VERSION "0.0.1"

NS_ :

BS_:

BU_: TCU BRK ESP MCU RDD GP TMS GW KPD1 RDE FNR ECU KPD2 ATSGO ACU IMU1 IMU2 IMU3 IMU4 IMU5 AGW PMI HDOQS EGOQS OBC EEC CBSW EJRH EJLH EPDLT EPDL2 EPDLR EPDLA TRBDZ ECU1 CLST LC510 EGDL JS SMB KPAC ACCU Audio TGU RDRR RDLH RDRH AVM CHMSL CTC SMK MC3D EVC MCU2

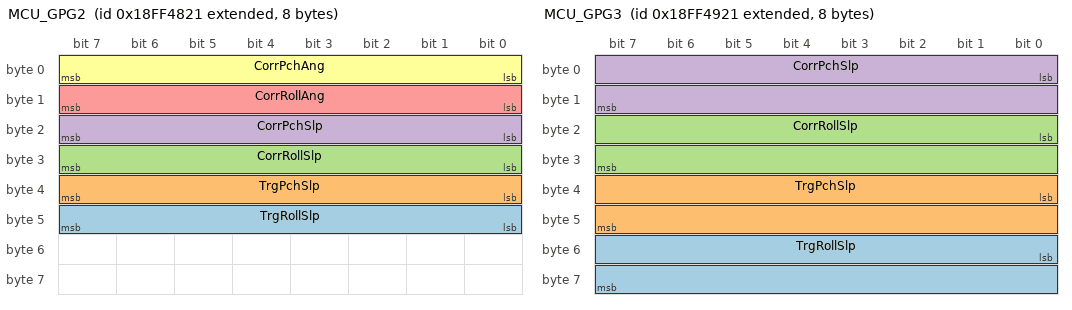
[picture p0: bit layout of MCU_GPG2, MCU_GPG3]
BO_ 2566866977 MCU_GPG2: 8 MCU
 SG_ TrgRollSlp : 40|8@1+ (1,-125) [-125|125] "%" Vector__XXX
 SG_ TrgPchSlp : 32|8@1+ (1,-125) [-125|125] "%" Vector__XXX
 SG_ CorrRollSlp : 24|8@1+ (1,-125) [-125|125] "%" Vector__XXX
 SG_ CorrPchSlp : 16|8@1+ (1,-125) [-125|125] "%" Vector__XXX
 SG_ CorrRollAng : 8|8@1+ (0.5,-65) [-65|60] "deg" Vector__XXX
 SG_ CorrPchAng : 0|8@1+ (0.5,-65) [-65|60] "deg" Vector__XXX

BO_ 2566867233 MCU_GPG3: 8 MCU
 SG_ TrgRollSlp : 48|16@1+ (0.01,-321.27) [-321.27|321.28] "%" Vector__XXX
 SG_ TrgPchSlp : 32|16@1+ (0.01,-321.27) [-321.27|321.28] "%" Vector__XXX
 SG_ CorrRollSlp : 16|16@1+ (0.01,-321.27) [-321.27|321.28] "%" Vector__XXX
 SG_ CorrPchSlp : 0|16@1+ (0.01,-321.27) [-321.27|321.28] "%" Vector__XXX

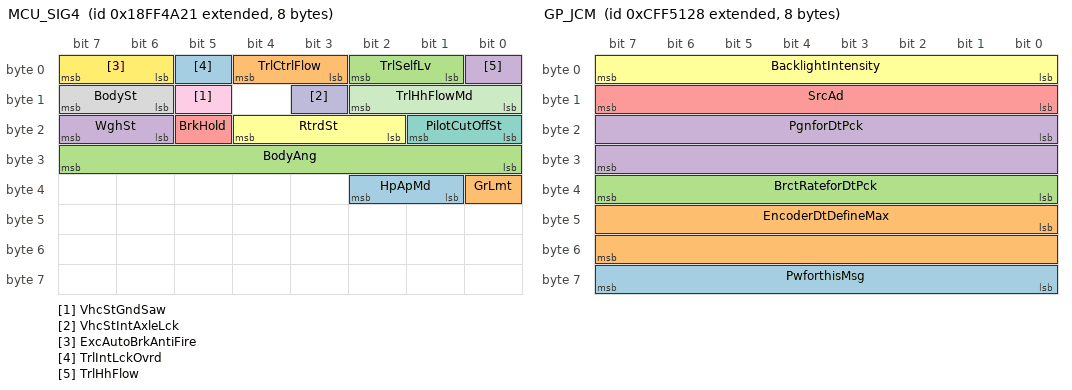
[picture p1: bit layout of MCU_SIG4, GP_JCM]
BO_ 2566867489 MCU_SIG4: 8 MCU
 SG_ HpApMd : 33|2@1+ (1,0) [0|3] "" Vector__XXX
 SG_ GrLmt : 32|1@1+ (1,0) [0|1] "" Vector__XXX
 SG_ BodyAng : 24|8@1+ (1,-125) [-125|125] "deg" Vector__XXX
 SG_ WghSt : 22|2@1+ (1,0) [0|3] "" Vector__XXX
 SG_ BrkHold : 21|1@1+ (1,0) [0|1] "" Vector__XXX
 SG_ RtrdSt : 18|3@1+ (1,0) [0|7] "" Vector__XXX
 SG_ PilotCutOffSt : 16|2@1+ (1,0) [0|3] "" Vector__XXX
 SG_ BodySt : 14|2@1+ (1,0) [0|3] "" Vector__XXX
 SG_ VhcStGndSaw : 13|1@1+ (1,0) [0|1] "" Vector__XXX
 SG_ VhcStIntAxleLck : 11|1@1+ (1,0) [0|1] "" Vector__XXX
 SG_ TrlHhFlowMd : 8|3@1+ (1,0) [0|7] "" Vector__XXX
 SG_ ExcAutoBrkAntiFire : 6|2@1+ (1,0) [0|3] "" Vector__XXX
 SG_ TrlIntLckOvrd : 5|1@1+ (1,0) [0|1] "" Vector__XXX
 SG_ TrlCtrlFlow : 3|2@1+ (1,0) [0|3] "" Vector__XXX
 SG_ TrlSelfLv : 1|2@1+ (1,0) [0|3] "" Vector__XXX
 SG_ TrlHhFlow : 0|1@1+ (1,0) [0|1] "" Vector__XXX

BO_ 2566867745 MCU_GPG4: 8 MCU
 SG_ EcoGgSt : 8|3@1+ (1,0) [0|7] "" Vector__XXX
 SG_ EcoGgLv : 0|8@1+ (1,0) [0|250] "%" Vector__XXX

BO_ 2566868257 MCU_METPSC: 250 MCU
 SG_ MaximumEgSpd : 40|16@1+ (0.125,0) [0|8031.875] "Rpm" Vector__XXX
 SG_ AutoCalbMd : 35|1@1+ (1,0) [0|1] "" Vector__XXX
 SG_ CalbReq : 34|1@1+ (1,0) [0|1] "" Vector__XXX
 SG_ VhcStTpsCalb : 32|2@1+ (1,0) [0|3] "" Vector__XXX
 SG_ MinimumEgSpd : 8|16@1+ (0.125,0) [0|8031.875] "rpm" Vector__XXX
 SG_ VhcStSsNrm : 3|1@1+ (1,0) [0|1] "" Vector__XXX
 SG_ VhcStEgIgn : 2|1@1+ (1,0) [0|1] "" Vector__XXX
 SG_ VhcStPilotCutOff : 1|1@1+ (1,0) [0|1] "" Vector__XXX
 SG_ VhcStEgCtrlDialMax : 0|1@1+ (1,0) [0|1] "" Vector__XXX

BO_ 2566868921 EGDL_EDO: 8 EGDL

BO_ 2566869025 MCU_JSO: 8 MCU

BO_ 2566869158 JS_JSO: 8 JS

BO_ 2365542696 GP_JCM: 8 GP
 SG_ PwforthisMsg : 56|8@1+ (1,0) [0|254] "" Vector__XXX
 SG_ EncoderDtDefineMax : 40|16@1+ (1,0) [0|65534] "" Vector__XXX
 SG_ BrctRateforDtPck : 32|8@1+ (1,0) [0|254] "" Vector__XXX
 SG_ PgnforDtPck : 16|16@1+ (1,0) [0|65534] "" Vector__XXX
 SG_ SrcAd : 8|8@1+ (1,0) [0|254] "" Vector__XXX
 SG_ BacklightIntensity : 0|8@1+ (1,0) [0|254] "" Vector__XXX

BO_ 2365542917 FNR_ZFTC1: 8 FNR

BO_ 2365543201 MCU_KEYPADBI: 8 MCU

BO_ 2365543504 KPD1_KEYPADS: 8 KPD1

BO_ 2365543713 MCU_KEYPADI1: 8 MCU

BO_ 2365543969 MCU_KEYPADMI1: 8 MCU

BO_ 2365544225 MCU_KEYPADMI2: 8 MCU

BO_ 2365544481 MCU_KEYPADI2: 8 MCU

BO_ 2365544737 MCU_KEYPADI3: 8 MCU

BO_ 2566871629 CBSW_HCMD: 8 CBSW

BO_ 2566872001 IMU1_ASI: 8 IMU1

BO_ 2566872002 IMU2_ASI: 8 IMU2

BO_ 2566872003 IMU3_ASI: 8 IMU3

BO_ 2566872004 IMU4_ASI: 8 IMU4

BO_ 2566872005 IMU5_ASI: 8 IMU5

BO_ 2365545552 KPD1_KEYPADS2: 8 KPD1

BO_ 2365545761 MCU_KEYPADI4: 8 MCU

BO_ 2566873377 MCU_ACUCTR: 8 MCU
 SG_ LowOutReq8 : 46|2@1+ (1,0) [0|3] "" Vector__XXX
 SG_ LowOutReq7 : 44|2@1+ (1,0) [0|3] "" Vector__XXX
 SG_ LowOutReq6 : 42|2@1+ (1,0) [0|3] "" Vector__XXX
 SG_ LowOutReq5 : 40|2@1+ (1,0) [0|3] "" Vector__XXX
 SG_ LowOutReq4 : 38|2@1+ (1,0) [0|3] "" Vector__XXX
 SG_ LowOutReq3 : 36|2@1+ (1,0) [0|3] "" Vector__XXX
 SG_ LowOutReq2 : 34|2@1+ (1,0) [0|3] "" Vector__XXX
 SG_ LowOutReq1 : 32|2@1+ (1,0) [0|3] "" Vector__XXX
 SG_ OutReq15 : 28|2@1+ (1,0) [0|3] "" Vector__XXX
 SG_ OutReq14 : 26|2@1+ (1,0) [0|3] "" Vector__XXX
 SG_ OutReq13 : 24|2@1+ (1,0) [0|3] "" Vector__XXX
 SG_ OutReq12 : 22|2@1+ (1,0) [0|3] "" Vector__XXX
 SG_ OutReq11 : 20|2@1+ (1,0) [0|3] "" Vector__XXX
 SG_ OutReq10 : 18|2@1+ (1,0) [0|3] "" Vector__XXX
 SG_ OutReq9 : 16|2@1+ (1,0) [0|3] "" Vector__XXX
 SG_ OutReq8 : 14|2@1+ (1,0) [0|3] "" Vector__XXX
 SG_ OutReq7 : 12|2@1+ (1,0) [0|3] "" Vector__XXX
 SG_ OutReq6 : 10|2@1+ (1,0) [0|3] "" Vector__XXX
 SG_ OutReq5 : 8|2@1+ (1,0) [0|3] "" Vector__XXX
 SG_ OutReq4 : 6|2@1+ (1,0) [0|3] "" Vector__XXX
 SG_ OutReq3 : 4|2@1+ (1,0) [0|3] "" Vector__XXX
 SG_ OutReq2 : 2|2@1+ (1,0) [0|3] "" Vector__XXX
 SG_ OutReq1 : 0|2@1+ (1,0) [0|3] "" Vector__XXX

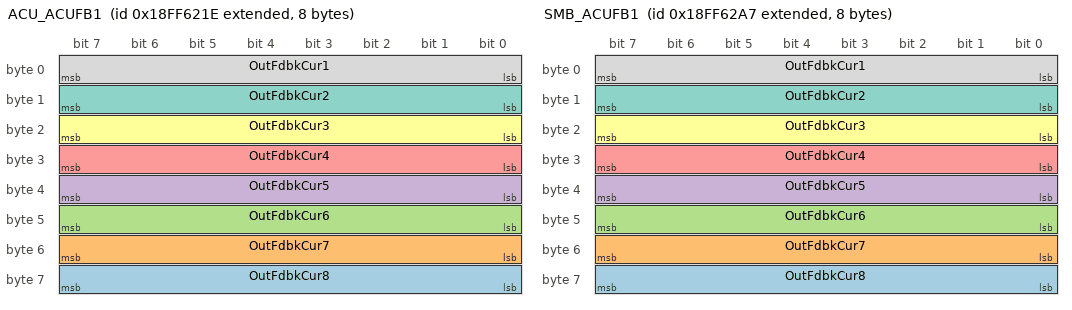
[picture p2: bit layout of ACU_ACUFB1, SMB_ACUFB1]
BO_ 2566873630 ACU_ACUFB1: 8 ACU
 SG_ OutFdbkCur8 : 56|8@1+ (1,0) [0|255] "" Vector__XXX
 SG_ OutFdbkCur7 : 48|8@1+ (1,0) [0|255] "" Vector__XXX
 SG_ OutFdbkCur6 : 40|8@1+ (1,0) [0|255] "" Vector__XXX
 SG_ OutFdbkCur5 : 32|8@1+ (1,0) [0|255] "" Vector__XXX
 SG_ OutFdbkCur4 : 24|8@1+ (1,0) [0|255] "" Vector__XXX
 SG_ OutFdbkCur3 : 16|8@1+ (1,0) [0|255] "" Vector__XXX
 SG_ OutFdbkCur2 : 8|8@1+ (1,0) [0|255] "" Vector__XXX
 SG_ OutFdbkCur1 : 0|8@1+ (0.05,0) [0|12.65] "A" Vector__XXX

BO_ 2566873767 SMB_ACUFB1: 8 SMB
 SG_ OutFdbkCur8 : 56|8@1+ (1,0) [0|255] "" Vector__XXX
 SG_ OutFdbkCur7 : 48|8@1+ (1,0) [0|255] "" Vector__XXX
 SG_ OutFdbkCur6 : 40|8@1+ (1,0) [0|255] "" Vector__XXX
 SG_ OutFdbkCur5 : 32|8@1+ (1,0) [0|255] "" Vector__XXX
 SG_ OutFdbkCur4 : 24|8@1+ (1,0) [0|255] "" Vector__XXX
 SG_ OutFdbkCur3 : 16|8@1+ (1,0) [0|255] "" Vector__XXX
 SG_ OutFdbkCur2 : 8|8@1+ (1,0) [0|255] "" Vector__XXX
 SG_ OutFdbkCur1 : 0|8@1+ (0.05,0) [0|12.65] "A" Vector__XXX

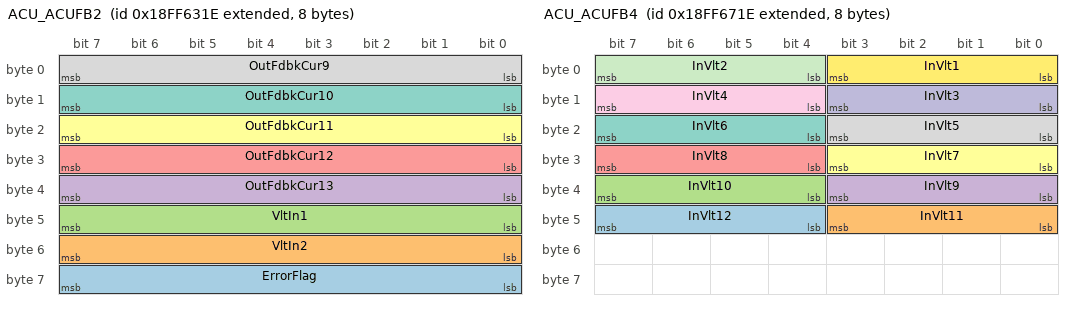
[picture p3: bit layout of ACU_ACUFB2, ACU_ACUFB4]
BO_ 2566873886 ACU_ACUFB2: 8 ACU
 SG_ ErrorFlag : 56|8@1+ (1,0) [0|255] "" Vector__XXX
 SG_ VltIn2 : 48|8@1+ (1,0) [0|255] "" Vector__XXX
 SG_ VltIn1 : 40|8@1+ (0.125,0) [0|31.625] "V" Vector__XXX
 SG_ OutFdbkCur13 : 32|8@1+ (1,0) [0|255] "" Vector__XXX
 SG_ OutFdbkCur12 : 24|8@1+ (1,0) [0|255] "" Vector__XXX
 SG_ OutFdbkCur11 : 16|8@1+ (1,0) [0|255] "" Vector__XXX
 SG_ OutFdbkCur10 : 8|8@1+ (1,0) [0|255] "" Vector__XXX
 SG_ OutFdbkCur9 : 0|8@1+ (0.05,0) [0|12.65] "A" Vector__XXX

BO_ 2566874654 ACU_ACUFB3: 8 ACU
 SG_ OutFdbkActvLowCur8 : 62|2@1+ (1,0) [0|3] "" Vector__XXX
 SG_ OutFdbkActvLowCur7 : 60|2@1+ (1,0) [0|3] "" Vector__XXX
 SG_ OutFdbkActvLowCur6 : 58|2@1+ (1,0) [0|3] "" Vector__XXX
 SG_ OutFdbkActvLowCur5 : 56|2@1+ (1,0) [0|3] "" Vector__XXX
 SG_ OutFdbkActvLowCur4 : 54|2@1+ (1,0) [0|3] "" Vector__XXX
 SG_ OutFdbkActvLowCur3 : 52|2@1+ (1,0) [0|3] "" Vector__XXX
 SG_ OutFdbkActvLowCur2 : 50|2@1+ (1,0) [0|3] "" Vector__XXX
 SG_ OutFdbkActvLowCur1 : 48|2@1+ (1,0) [0|3] "" Vector__XXX
 SG_ OutFdbkActvHighCur15 : 46|2@1+ (1,0) [0|3] "" Vector__XXX
 SG_ OutFdbkActvHighCur14 : 44|2@1+ (1,0) [0|3] "" Vector__XXX
 SG_ OutFdbkActvHighCur13 : 42|2@1+ (1,0) [0|3] "" Vector__XXX
 SG_ OutFdbkActvHighCur12 : 40|2@1+ (1,0) [0|3] "" Vector__XXX
 SG_ OutFdbkActvHighCur11 : 38|2@1+ (1,0) [0|3] "" Vector__XXX
 SG_ OutFdbkActvHighCur10 : 36|2@1+ (1,0) [0|3] "" Vector__XXX
 SG_ OutFdbkActvHighCur9 : 34|2@1+ (1,0) [0|3] "" Vector__XXX
 SG_ OutFdbkActvHighCur8 : 32|2@1+ (1,0) [0|3] "" Vector__XXX
 SG_ OutFdbkActvHighCur7 : 30|2@1+ (1,0) [0|3] "" Vector__XXX
 SG_ OutFdbkActvHighCur6 : 28|2@1+ (1,0) [0|3] "" Vector__XXX
 SG_ OutFdbkActvHighCur5 : 26|2@1+ (1,0) [0|3] "" Vector__XXX
 SG_ OutFdbkActvHighCur4 : 24|2@1+ (1,0) [0|3] "" Vector__XXX
 SG_ OutFdbkActvHighCur3 : 16|8@1+ (1,0) [0|255] "" Vector__XXX
 SG_ OutFdbkActvHighCur2 : 8|8@1+ (1,0) [0|255] "" Vector__XXX
 SG_ OutFdbkActvHighCur1 : 0|8@1+ (0.1,0) [0|25.3] "A" Vector__XXX

BO_ 2566874910 ACU_ACUFB4: 8 ACU
 SG_ InVlt12 : 44|4@1+ (1,0) [0|15] "" Vector__XXX
 SG_ InVlt11 : 40|4@1+ (1,0) [0|15] "" Vector__XXX
 SG_ InVlt10 : 36|4@1+ (1,0) [0|15] "" Vector__XXX
 SG_ InVlt9 : 32|4@1+ (1,0) [0|15] "" Vector__XXX
 SG_ InVlt8 : 28|4@1+ (1,0) [0|15] "" Vector__XXX
 SG_ InVlt7 : 24|4@1+ (1,0) [0|15] "" Vector__XXX
 SG_ InVlt6 : 20|4@1+ (1,0) [0|15] "" Vector__XXX
 SG_ InVlt5 : 16|4@1+ (1,0) [0|15] "" Vector__XXX
 SG_ InVlt4 : 12|4@1+ (1,0) [0|15] "" Vector__XXX
 SG_ InVlt3 : 8|4@1+ (1,0) [0|15] "" Vector__XXX
 SG_ InVlt2 : 4|4@1+ (1,0) [0|15] "" Vector__XXX
 SG_ InVlt1 : 0|4@1+ (2,0) [0|30] "V" Vector__XXX

BO_ 2566875297 KPAC_ACCMD: 8 KPAC

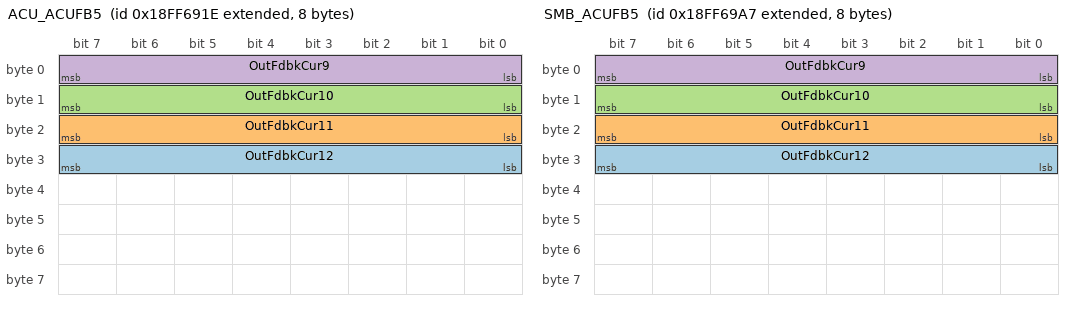
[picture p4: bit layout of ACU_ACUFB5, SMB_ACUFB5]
BO_ 2566875422 ACU_ACUFB5: 8 ACU
 SG_ OutFdbkCur12 : 24|8@1+ (1,0) [0|255] "" Vector__XXX
 SG_ OutFdbkCur11 : 16|8@1+ (1,0) [0|255] "" Vector__XXX
 SG_ OutFdbkCur10 : 8|8@1+ (1,0) [0|255] "" Vector__XXX
 SG_ OutFdbkCur9 : 0|8@1+ (0.1,0) [0|25.3] "A" Vector__XXX

BO_ 2566875559 SMB_ACUFB5: 8 SMB
 SG_ OutFdbkCur12 : 24|8@1+ (1,0) [0|255] "" Vector__XXX
 SG_ OutFdbkCur11 : 16|8@1+ (1,0) [0|255] "" Vector__XXX
 SG_ OutFdbkCur10 : 8|8@1+ (1,0) [0|255] "" Vector__XXX
 SG_ OutFdbkCur9 : 0|8@1+ (0.1,0) [0|25.3] "A" Vector__XXX

BO_ 2566875678 ACU_ACUFB6: 28 ACU
 SG_ MiniRly30AFuse2St : 221|1@1+ (1,0) [0|1] "" Vector__XXX
 SG_ MiniRly30AFuse1St : 220|1@1+ (1,0) [0|1] "" Vector__XXX
 SG_ MicroRly20AFuse5St : 219|1@1+ (1,0) [0|1] "" Vector__XXX
 SG_ MicroRly20AFuse4St : 218|1@1+ (1,0) [0|1] "" Vector__XXX
 SG_ MicroRly20AFuse3St : 217|1@1+ (1,0) [0|1] "" Vector__XXX
 SG_ MicroRly20AFuse2St : 216|1@1+ (1,0) [0|1] "" Vector__XXX
 SG_ MicroRly20AFuse1St : 215|1@1+ (1,0) [0|1] "" Vector__XXX
 SG_ KeyOn30AFuse5St : 214|1@1+ (1,0) [0|1] "" Vector__XXX
 SG_ KeyOn30AFuse4St : 213|1@1+ (1,0) [0|1] "" Vector__XXX
 SG_ KeyOn30AFuse3St : 212|1@1+ (1,0) [0|1] "" Vector__XXX
 SG_ KeyOn30AFuse2St : 211|1@1+ (1,0) [0|1] "" Vector__XXX
 SG_ KeyOn30AFuse1St : 210|1@1+ (1,0) [0|1] "" Vector__XXX
 SG_ KeyOn20AFuse10St : 209|1@1+ (1,0) [0|1] "" Vector__XXX
 SG_ KeyOn20AFuse9St : 208|1@1+ (1,0) [0|1] "" Vector__XXX
 SG_ KeyOn20AFuse8St : 207|1@1+ (1,0) [0|1] "" Vector__XXX
 SG_ KeyOn20AFuse7St : 206|1@1+ (1,0) [0|1] "" Vector__XXX
 SG_ KeyOn20AFuse6St : 205|1@1+ (1,0) [0|1] "" Vector__XXX
 SG_ KeyOn20AFuse5St : 204|1@1+ (1,0) [0|1] "" Vector__XXX
 SG_ KeyOn20AFuse4St : 203|1@1+ (1,0) [0|1] "" Vector__XXX
 SG_ KeyOn20AFuse3St : 202|1@1+ (1,0) [0|1] "" Vector__XXX
 SG_ KeyOn20AFuse2St : 201|1@1+ (1,0) [0|1] "" Vector__XXX
 SG_ KeyOn20AFuse1St : 200|1@1+ (1,0) [0|1] "" Vector__XXX
 SG_ KeyOn10AFuse5St : 199|1@1+ (1,0) [0|1] "" Vector__XXX
 SG_ KeyOn10AFuse4St : 198|1@1+ (1,0) [0|1] "" Vector__XXX
 SG_ KeyOn10AFuse3St : 197|1@1+ (1,0) [0|1] "" Vector__XXX
 SG_ KeyOn10AFuse2St : 196|1@1+ (1,0) [0|1] "" Vector__XXX
 SG_ KeyOn10AFuse1St : 195|1@1+ (1,0) [0|1] "" Vector__XXX
 SG_ KeyOn5AFuse15St : 194|1@1+ (1,0) [0|1] "" Vector__XXX
 SG_ KeyOn5AFuse14St : 193|1@1+ (1,0) [0|1] "" Vector__XXX
 SG_ KeyOn5AFuse13St : 192|1@1+ (1,0) [0|1] "" Vector__XXX
 SG_ KeyOn5AFuse12St : 191|1@1+ (1,0) [0|1] "" Vector__XXX
 SG_ KeyOn5AFuse11St : 190|1@1+ (1,0) [0|1] "" Vector__XXX
 SG_ KeyOn5AFuse10St : 189|1@1+ (1,0) [0|1] "" Vector__XXX
 SG_ KeyOn5AFuse9St : 188|1@1+ (1,0) [0|1] "" Vector__XXX
 SG_ KeyOn5AFuse8St : 187|1@1+ (1,0) [0|1] "" Vector__XXX
 SG_ KeyOn5AFuse7St : 186|1@1+ (1,0) [0|1] "" Vector__XXX
 SG_ KeyOn5AFuse6St : 185|1@1+ (1,0) [0|1] "" Vector__XXX
 SG_ KeyOn5AFuse5St : 184|1@1+ (1,0) [0|1] "" Vector__XXX
 SG_ KeyOn5AFuse4St : 183|1@1+ (1,0) [0|1] "" Vector__XXX
 SG_ KeyOn5AFuse3St : 182|1@1+ (1,0) [0|1] "" Vector__XXX
 SG_ KeyOn5AFuse2St : 181|1@1+ (1,0) [0|1] "" Vector__XXX
 SG_ KeyOn5AFuse1St : 180|1@1+ (1,0) [0|1] "" Vector__XXX
 SG_ BPlus30AFuse5St : 179|1@1+ (1,0) [0|1] "" Vector__XXX
 SG_ BPlus30AFuse4St : 178|1@1+ (1,0) [0|1] "" Vector__XXX
 SG_ BPlus30AFuse3St : 177|1@1+ (1,0) [0|1] "" Vector__XXX
 SG_ BPlus30AFuse2St : 176|1@1+ (1,0) [0|1] "" Vector__XXX
 SG_ BPlus30AFuse1St : 175|1@1+ (1,0) [0|1] "" Vector__XXX
 SG_ BPlus20AFuse5St : 174|1@1+ (1,0) [0|1] "" Vector__XXX
 SG_ BPlus20AFuse4St : 173|1@1+ (1,0) [0|1] "" Vector__XXX
 SG_ BPlus20AFuse3St : 172|1@1+ (1,0) [0|1] "" Vector__XXX
 SG_ BPlus20AFuse2St : 171|1@1+ (1,0) [0|1] "" Vector__XXX
 SG_ BPlus20AFuse1St : 170|1@1+ (1,0) [0|1] "" Vector__XXX
 SG_ BPlus5AFuse10St : 169|1@1+ (1,0) [0|1] "" Vector__XXX
 SG_ BPlus5AFuse9St : 168|1@1+ (1,0) [0|1] "" Vector__XXX
 SG_ BPlus5AFuse8St : 167|1@1+ (1,0) [0|1] "" Vector__XXX
 SG_ BPlus5AFuse7St : 166|1@1+ (1,0) [0|1] "" Vector__XXX
 SG_ BPlus5AFuse6St : 165|1@1+ (1,0) [0|1] "" Vector__XXX
 SG_ BPlus5AFuse5St : 164|1@1+ (1,0) [0|1] "" Vector__XXX
 SG_ BPlus5AFuse4St : 163|1@1+ (1,0) [0|1] "" Vector__XXX
 SG_ BPlus5AFuse3St : 162|1@1+ (1,0) [0|1] "" Vector__XXX
 SG_ BPlus5AFuse2St : 161|1@1+ (1,0) [0|1] "" Vector__XXX
 SG_ BPlus5AFuse1St : 160|1@1+ (1,0) [0|1] "" Vector__XXX
 SG_ IPSTotalCur : 144|16@1+ (0.1,0) [0|102] "%" Vector__XXX
 SG_ MINIFuse2Cur : 128|16@1+ (0.05,0) [0|3212.75] "A" Vector__XXX
 SG_ MINIFuse1Cur : 112|16@1+ (0.05,0) [0|3212.75] "A" Vector__XXX
 SG_ MicroFuse5Cur : 96|16@1+ (0.05,0) [0|3212.75] "A" Vector__XXX
 SG_ MicroFuse4Cur : 80|16@1+ (0.05,0) [0|3212.75] "A" Vector__XXX
 SG_ MicroFuse3Cur : 64|16@1+ (0.05,0) [0|3212.75] "A" Vector__XXX
 SG_ MicroFuse2Cur : 48|16@1+ (0.05,0) [0|3212.75] "A" Vector__XXX
 SG_ MicroFuse1Cur : 32|16@1+ (0.05,0) [0|3212.75] "A" Vector__XXX
 SG_ KeyOnPwrCur : 16|16@1+ (0.05,0) [0|3212.75] "A" Vector__XXX
 SG_ BPlusPwrCur : 0|16@1+ (0.05,0) [0|3212.75] "A" Vector__XXX

BO_ 2566875815 SMB_ACUFB6: 28 SMB
 SG_ MiniRly30AFuse2St : 221|1@1+ (1,0) [0|1] "" Vector__XXX
 SG_ MiniRly30AFuse1St : 220|1@1+ (1,0) [0|1] "" Vector__XXX
 SG_ MicroRly20AFuse5St : 219|1@1+ (1,0) [0|1] "" Vector__XXX
 SG_ MicroRly20AFuse4St : 218|1@1+ (1,0) [0|1] "" Vector__XXX
 SG_ MicroRly20AFuse3St : 217|1@1+ (1,0) [0|1] "" Vector__XXX
 SG_ MicroRly20AFuse2St : 216|1@1+ (1,0) [0|1] "" Vector__XXX
 SG_ MicroRly20AFuse1St : 215|1@1+ (1,0) [0|1] "" Vector__XXX
 SG_ KeyOn30AFuse5St : 214|1@1+ (1,0) [0|1] "" Vector__XXX
 SG_ KeyOn30AFuse4St : 213|1@1+ (1,0) [0|1] "" Vector__XXX
 SG_ KeyOn30AFuse3St : 212|1@1+ (1,0) [0|1] "" Vector__XXX
 SG_ KeyOn30AFuse2St : 211|1@1+ (1,0) [0|1] "" Vector__XXX
 SG_ KeyOn30AFuse1St : 210|1@1+ (1,0) [0|1] "" Vector__XXX
 SG_ KeyOn20AFuse10St : 209|1@1+ (1,0) [0|1] "" Vector__XXX
 SG_ KeyOn20AFuse9St : 208|1@1+ (1,0) [0|1] "" Vector__XXX
 SG_ KeyOn20AFuse8St : 207|1@1+ (1,0) [0|1] "" Vector__XXX
 SG_ KeyOn20AFuse7St : 206|1@1+ (1,0) [0|1] "" Vector__XXX
 SG_ KeyOn20AFuse6St : 205|1@1+ (1,0) [0|1] "" Vector__XXX
 SG_ KeyOn20AFuse5St : 204|1@1+ (1,0) [0|1] "" Vector__XXX
 SG_ KeyOn20AFuse4St : 203|1@1+ (1,0) [0|1] "" Vector__XXX
 SG_ KeyOn20AFuse3St : 202|1@1+ (1,0) [0|1] "" Vector__XXX
 SG_ KeyOn20AFuse2St : 201|1@1+ (1,0) [0|1] "" Vector__XXX
 SG_ KeyOn20AFuse1St : 200|1@1+ (1,0) [0|1] "" Vector__XXX
 SG_ KeyOn10AFuse5St : 199|1@1+ (1,0) [0|1] "" Vector__XXX
 SG_ KeyOn10AFuse4St : 198|1@1+ (1,0) [0|1] "" Vector__XXX
 SG_ KeyOn10AFuse3St : 197|1@1+ (1,0) [0|1] "" Vector__XXX
 SG_ KeyOn10AFuse2St : 196|1@1+ (1,0) [0|1] "" Vector__XXX
 SG_ KeyOn10AFuse1St : 195|1@1+ (1,0) [0|1] "" Vector__XXX
 SG_ KeyOn5AFuse15St : 194|1@1+ (1,0) [0|1] "" Vector__XXX
 SG_ KeyOn5AFuse14St : 193|1@1+ (1,0) [0|1] "" Vector__XXX
 SG_ KeyOn5AFuse13St : 192|1@1+ (1,0) [0|1] "" Vector__XXX
 SG_ KeyOn5AFuse12St : 191|1@1+ (1,0) [0|1] "" Vector__XXX
 SG_ KeyOn5AFuse11St : 190|1@1+ (1,0) [0|1] "" Vector__XXX
 SG_ KeyOn5AFuse10St : 189|1@1+ (1,0) [0|1] "" Vector__XXX
 SG_ KeyOn5AFuse9St : 188|1@1+ (1,0) [0|1] "" Vector__XXX
 SG_ KeyOn5AFuse8St : 187|1@1+ (1,0) [0|1] "" Vector__XXX
 SG_ KeyOn5AFuse7St : 186|1@1+ (1,0) [0|1] "" Vector__XXX
 SG_ KeyOn5AFuse6St : 185|1@1+ (1,0) [0|1] "" Vector__XXX
 SG_ KeyOn5AFuse5St : 184|1@1+ (1,0) [0|1] "" Vector__XXX
 SG_ KeyOn5AFuse4St : 183|1@1+ (1,0) [0|1] "" Vector__XXX
 SG_ KeyOn5AFuse3St : 182|1@1+ (1,0) [0|1] "" Vector__XXX
 SG_ KeyOn5AFuse2St : 181|1@1+ (1,0) [0|1] "" Vector__XXX
 SG_ KeyOn5AFuse1St : 180|1@1+ (1,0) [0|1] "" Vector__XXX
 SG_ BPlus30AFuse5St : 179|1@1+ (1,0) [0|1] "" Vector__XXX
 SG_ BPlus30AFuse4St : 178|1@1+ (1,0) [0|1] "" Vector__XXX
 SG_ BPlus30AFuse3St : 177|1@1+ (1,0) [0|1] "" Vector__XXX
 SG_ BPlus30AFuse2St : 176|1@1+ (1,0) [0|1] "" Vector__XXX
 SG_ BPlus30AFuse1St : 175|1@1+ (1,0) [0|1] "" Vector__XXX
 SG_ BPlus20AFuse5St : 174|1@1+ (1,0) [0|1] "" Vector__XXX
 SG_ BPlus20AFuse4St : 173|1@1+ (1,0) [0|1] "" Vector__XXX
 SG_ BPlus20AFuse3St : 172|1@1+ (1,0) [0|1] "" Vector__XXX
 SG_ BPlus20AFuse2St : 171|1@1+ (1,0) [0|1] "" Vector__XXX
 SG_ BPlus20AFuse1St : 170|1@1+ (1,0) [0|1] "" Vector__XXX
 SG_ BPlus5AFuse10St : 169|1@1+ (1,0) [0|1] "" Vector__XXX
 SG_ BPlus5AFuse9St : 168|1@1+ (1,0) [0|1] "" Vector__XXX
 SG_ BPlus5AFuse8St : 167|1@1+ (1,0) [0|1] "" Vector__XXX
 SG_ BPlus5AFuse7St : 166|1@1+ (1,0) [0|1] "" Vector__XXX
 SG_ BPlus5AFuse6St : 165|1@1+ (1,0) [0|1] "" Vector__XXX
 SG_ BPlus5AFuse5St : 164|1@1+ (1,0) [0|1] "" Vector__XXX
 SG_ BPlus5AFuse4St : 163|1@1+ (1,0) [0|1] "" Vector__XXX
 SG_ BPlus5AFuse3St : 162|1@1+ (1,0) [0|1] "" Vector__XXX
 SG_ BPlus5AFuse2St : 161|1@1+ (1,0) [0|1] "" Vector__XXX
 SG_ BPlus5AFuse1St : 160|1@1+ (1,0) [0|1] "" Vector__XXX
 SG_ IPSTotalCur : 144|16@1+ (0.1,0) [0|102] "%" Vector__XXX
 SG_ MINIFuse2Cur : 128|16@1+ (0.05,0) [0|3212.75] "A" Vector__XXX
 SG_ MINIFuse1Cur : 112|16@1+ (0.05,0) [0|3212.75] "A" Vector__XXX
 SG_ MicroFuse5Cur : 96|16@1+ (0.05,0) [0|3212.75] "A" Vector__XXX
 SG_ MicroFuse4Cur : 80|16@1+ (0.05,0) [0|3212.75] "A" Vector__XXX
 SG_ MicroFuse3Cur : 64|16@1+ (0.05,0) [0|3212.75] "A" Vector__XXX
 SG_ MicroFuse2Cur : 48|16@1+ (0.05,0) [0|3212.75] "A" Vector__XXX
 SG_ MicroFuse1Cur : 32|16@1+ (0.05,0) [0|3212.75] "A" Vector__XXX
 SG_ KeyOnPwrCur : 16|16@1+ (0.05,0) [0|3212.75] "A" Vector__XXX
 SG_ BPlusPwrCur : 0|16@1+ (0.05,0) [0|3212.75] "A" Vector__XXX

BO_ 2566875929 ACCU_ACRM: 8 ACCU
 SG_ AcpSsPrs : 56|8@1+ (16,0) [0|4000] "" Vector__XXX
 SG_ CurAmbTmpCelsRealTm : 48|8@1+ (0.5,-40) [-40|86] "Celsius" Vector__XXX
 SG_ TmpSt : 44|4@1+ (1,0) [1|15] "Step" Vector__XXX
 SG_ CurBlowerSpd : 40|4@1+ (1,0) [0|13] "" Vector__XXX
 SG_ CurAmbTmpCelsFilt : 32|8@1+ (0.5,-40) [-40|86] "Celsius" Vector__XXX
 SG_ VhcStSybACOffInd : 29|2@1+ (1,0) [0|3] "" Vector__XXX
 SG_ CurTmpSet : 24|5@1+ (0.5,17) [17|32] "Celsius" Vector__XXX
 SG_ CpsSt : 22|2@1+ (1,0) [0|3] "" Vector__XXX
 SG_ TmpSetValBelowSt : 20|2@1+ (1,0) [0|3] "" Vector__XXX
 SG_ TmpSetValOverSt : 18|2@1+ (1,0) [0|3] "" Vector__XXX
 SG_ HvacPwrSt : 16|2@1+ (1,0) [0|3] "" Vector__XXX
 SG_ WindDirDefIndSt : 14|2@1+ (1,0) [0|3] "" Vector__XXX
 SG_ WindDirFloorIndSt : 12|2@1+ (1,0) [0|3] "" Vector__XXX
 SG_ WindDirRrIndSt : 10|2@1+ (1,0) [0|3] "" Vector__XXX
 SG_ WindDirFrIndSt : 8|2@1+ (1,0) [0|3] "" Vector__XXX
 SG_ DefMdSt : 6|2@1+ (1,0) [0|3] "" Vector__XXX
 SG_ OutInMdSel : 4|2@1+ (1,0) [0|3] "" Vector__XXX
 SG_ AcMdSt : 2|2@1+ (1,0) [0|3] "" Vector__XXX
 SG_ MnAutoMdSt : 0|2@1+ (1,0) [0|3] "" Vector__XXX

BO_ 2566876320 Audio_DCAI: 8 Audio

BO_ 2566876576 Audio_AFRTGP: 250 Audio

BO_ 2566876832 Audio_APFGP: 250 Audio

BO_ 2566876961 MCU_ACUCTR2: 8 MCU
 SG_ LowOutReq8 : 46|2@1+ (1,0) [0|3] "" Vector__XXX
 SG_ LowOutReq7 : 44|2@1+ (1,0) [0|3] "" Vector__XXX
 SG_ LowOutReq6 : 42|2@1+ (1,0) [0|3] "" Vector__XXX
 SG_ LowOutReq5 : 40|2@1+ (1,0) [0|3] "" Vector__XXX
 SG_ LowOutReq4 : 38|2@1+ (1,0) [0|3] "" Vector__XXX
 SG_ LowOutReq3 : 36|2@1+ (1,0) [0|3] "" Vector__XXX
 SG_ LowOutReq2 : 34|2@1+ (1,0) [0|3] "" Vector__XXX
 SG_ LowOutReq1 : 32|2@1+ (1,0) [0|3] "" Vector__XXX
 SG_ OutReq15 : 28|2@1+ (1,0) [0|3] "" Vector__XXX
 SG_ OutReq14 : 26|2@1+ (1,0) [0|3] "" Vector__XXX
 SG_ OutReq13 : 24|2@1+ (1,0) [0|3] "" Vector__XXX
 SG_ OutReq12 : 22|2@1+ (1,0) [0|3] "" Vector__XXX
 SG_ OutReq11 : 20|2@1+ (1,0) [0|3] "" Vector__XXX
 SG_ OutReq10 : 18|2@1+ (1,0) [0|3] "" Vector__XXX
 SG_ OutReq9 : 16|2@1+ (1,0) [0|3] "" Vector__XXX
 SG_ OutReq8 : 14|2@1+ (1,0) [0|3] "" Vector__XXX
 SG_ OutReq7 : 12|2@1+ (1,0) [0|3] "" Vector__XXX
 SG_ OutReq6 : 10|2@1+ (1,0) [0|3] "" Vector__XXX
 SG_ OutReq5 : 8|2@1+ (1,0) [0|3] "" Vector__XXX
 SG_ OutReq4 : 6|2@1+ (1,0) [0|3] "" Vector__XXX
 SG_ OutReq3 : 4|2@1+ (1,0) [0|3] "" Vector__XXX
 SG_ OutReq2 : 2|2@1+ (1,0) [0|3] "" Vector__XXX
 SG_ OutReq1 : 0|2@1+ (1,0) [0|3] "" Vector__XXX

BO_ 2566877258 TMS_TMSVI: 250 TMS

BO_ 2566877514 TMS_TMSVTI: 250 TMS

BO_ 2566877770 TGU_TMSGPSI: 17 TGU
 SG_ Offset : 104|32@1+ (1,0) [-43200|43200] "S" Vector__XXX
 SG_ St : 96|8@1+ (1,0) [0|3] "" Vector__XXX
 SG_ GpsSatNo : 88|8@1+ (1,0) [0|255] "" Vector__XXX
 SG_ Spd : 80|8@1+ (1,0) [0|255] "km/h" Vector__XXX
 SG_ Z : 48|32@1+ (1,0) [-2147483648|2147483647] "m" Vector__XXX
 SG_ Y : 24|24@1+ (1,0) [-180|180] "Degree" Vector__XXX
 SG_ X : 0|24@1+ (1,0) [-90|90] "Degree" Vector__XXX

BO_ 2566878026 TGU_TMSNIC: 250 TGU

BO_ 2566878282 TMS_TMSNIS: 250 TMS

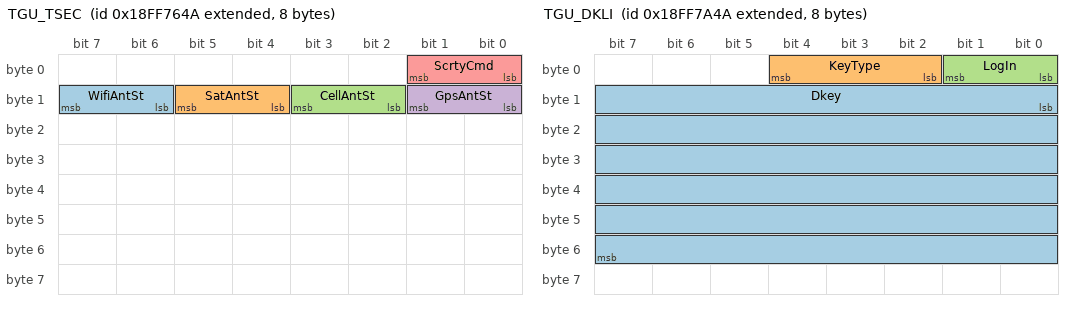
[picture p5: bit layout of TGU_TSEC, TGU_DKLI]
BO_ 2566878794 TGU_TSEC: 8 TGU
 SG_ WifiAntSt : 14|2@1+ (1,0) [0|3] "" Vector__XXX
 SG_ SatAntSt : 12|2@1+ (1,0) [0|3] "" Vector__XXX
 SG_ CellAntSt : 10|2@1+ (1,0) [0|3] "" Vector__XXX
 SG_ GpsAntSt : 8|2@1+ (1,0) [0|3] "" Vector__XXX
 SG_ ScrtyCmd : 0|2@1+ (1,0) [0|3] "" Vector__XXX

BO_ 2566879050 TMS_TMSGPSI2: 8 TMS

BO_ 2566879272 GP_TMSTP: 8 GP
 SG_ Sha1Hash : 0|32@1+ (1,0) [0|255] "" Vector__XXX

BO_ 2566879306 TGU_TMSTP: 8 TGU
 SG_ Sha1Hash : 0|32@1+ (1,0) [0|255] "" Vector__XXX

BO_ 2566879562 TGU_TMSLURT: 8 TGU
 SG_ Cd : 0|48@1+ (1,0) [0|255] "" Vector__XXX

BO_ 2566879818 TGU_DKLI: 8 TGU
 SG_ Dkey : 8|48@1+ (1,0) [0|281474976710655] "" Vector__XXX
 SG_ KeyType : 2|3@1+ (1,0) [0|7] "" Vector__XXX
 SG_ LogIn : 0|2@1+ (1,0) [0|3] "" Vector__XXX

BO_ 2566880074 TGU_DKLD: 9 TGU
 SG_ DkeyList : 8|64@1+ (1,0) [0|0] "" Vector__XXX
 SG_ Cnt : 0|8@1+ (1,0) [0|255] "" Vector__XXX

BO_ 2566880330 TGU_DKSEL: 8 TGU
 SG_ DigitalKey : 8|48@1+ (1,0) [0|281474976710655] "" Vector__XXX
 SG_ SelType : 0|3@1+ (1,0) [0|7] "" Vector__XXX

BO_ 2566880586 TMS_TMSACKNACK: 8 TMS

BO_ 2566880842 TGU_TMSPUC: 8 TGU
 SG_ TmsPmntUnlockCd : 0|32@1+ (1,0) [0|4294967295] "" Vector__XXX

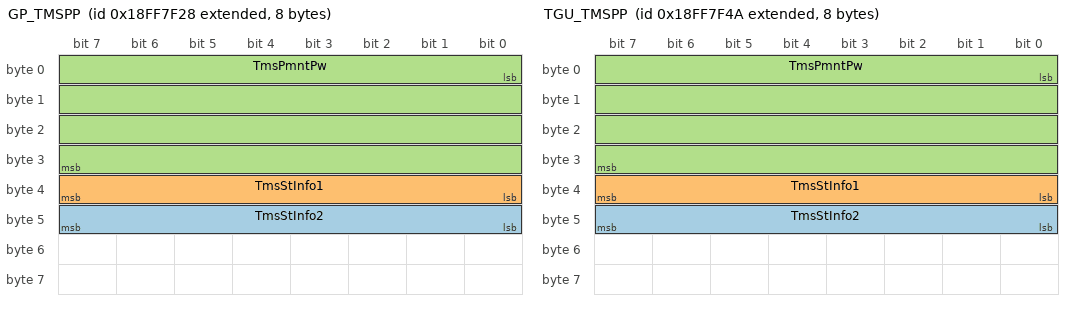
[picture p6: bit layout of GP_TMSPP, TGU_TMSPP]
BO_ 2566881064 GP_TMSPP: 8 GP
 SG_ TmsStInfo2 : 40|8@1+ (1,0) [0|255] "" Vector__XXX
 SG_ TmsStInfo1 : 32|8@1+ (1,0) [0|255] "" Vector__XXX
 SG_ TmsPmntPw : 0|32@1+ (1,0) [0|4294967295] "" Vector__XXX

BO_ 2566881098 TGU_TMSPP: 8 TGU
 SG_ TmsStInfo2 : 40|8@1+ (1,0) [0|255] "" Vector__XXX
 SG_ TmsStInfo1 : 32|8@1+ (1,0) [0|255] "" Vector__XXX
 SG_ TmsPmntPw : 0|32@1+ (1,0) [0|4294967295] "" Vector__XXX

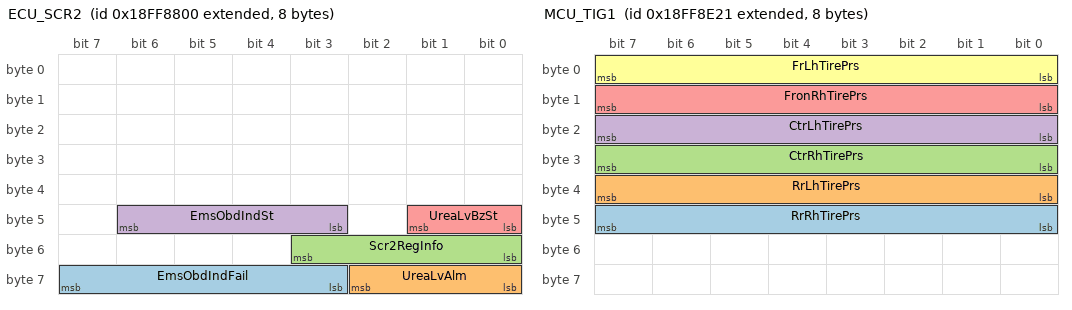
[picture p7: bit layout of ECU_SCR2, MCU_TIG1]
BO_ 2566883328 ECU_SCR2: 8 ECU
 SG_ EmsObdIndFail : 59|5@1+ (1,0) [0|31] "" Vector__XXX
 SG_ UreaLvAlm : 56|3@1+ (1,0) [0|7] "" Vector__XXX
 SG_ Scr2RegInfo : 48|4@1+ (1,0) [0|15] "" Vector__XXX
 SG_ EmsObdIndSt : 43|4@1+ (1,0) [0|15] "" Vector__XXX
 SG_ UreaLvBzSt : 40|2@1+ (1,0) [0|3] "" Vector__XXX

BO_ 2566883873 MCU_AASI: 62 MCU
 SG_ AltVlt : 480|16@1+ (0.001,0) [0|64.255] "V" Vector__XXX
 SG_ Rr2BrkSsPrs : 464|16@1+ (0.0625,0) [0|500] "bar" Vector__XXX
 SG_ BoomCylRodSsPrs : 448|16@1+ (0.0625,0) [0|500] "bar" Vector__XXX
 SG_ BoomCylHeadSsPrs : 432|16@1+ (0.0625,0) [0|500] "bar" Vector__XXX
 SG_ CtrPinAngSs1Vlt : 416|16@1+ (0.001,0) [0|64.255] "V" Vector__XXX
 SG_ AccPdlSs2Vlt : 400|16@1+ (0.001,0) [0|64.255] "V" Vector__XXX
 SG_ DumpBedAngSs2Vlt : 384|16@1+ (0.001,0) [0|64.255] "V" Vector__XXX
 SG_ DumpBedAngSs1Vlt : 368|16@1+ (0.001,0) [0|64.255] "V" Vector__XXX
 SG_ BrkInchPdlSs1Vlt : 352|16@1+ (0.001,0) [0|64.255] "V" Vector__XXX
 SG_ TipJoySs1Vlt : 336|16@1+ (0.001,0) [0|64.255] "V" Vector__XXX
 SG_ RhCylSsPrs : 320|16@1+ (0.0625,0) [0|500] "bar" Vector__XXX
 SG_ EmgStrSsPrs : 304|16@1+ (0.0625,0) [0|500] "bar" Vector__XXX
 SG_ AxleOilSsTmp : 288|16@1+ (1,-40) [-40|210] "�C" Vector__XXX
 SG_ FuelSsLv : 272|16@1+ (1,0) [0|250] "%" Vector__XXX
 SG_ Rr1BrkSsPrs : 256|16@1+ (0.0625,0) [0|500] "bar" Vector__XXX
 SG_ FrBrkSsPrs : 240|16@1+ (0.0625,0) [0|500] "bar" Vector__XXX
 SG_ AccPdlSs1Vlt : 224|16@1+ (0.001,0) [0|64.255] "V" Vector__XXX
 SG_ CtrPinAngSs2Vlt : 208|16@1+ (0.001,0) [0|64.255] "V" Vector__XXX
 SG_ TmsSecVlt : 192|16@1+ (0.001,0) [0|64.255] "V" Vector__XXX
 SG_ LhCylSsPrs : 176|16@1+ (0.0625,0) [0|500] "bar" Vector__XXX
 SG_ Acc3SsPrs : 160|16@1+ (0.0625,0) [0|500] "bar" Vector__XXX
 SG_ BrkInchPdlSs2Vlt : 144|16@1+ (0.001,0) [0|64.255] "V" Vector__XXX
 SG_ CacFanSsPrs : 128|16@1+ (0.0625,0) [0|500] "bar" Vector__XXX
 SG_ Acc2SsPrs : 112|16@1+ (0.0625,0) [0|500] "bar" Vector__XXX
 SG_ TipJoySs2Vlt : 96|16@1+ (0.001,0) [0|64.255] "V" Vector__XXX
 SG_ TocFanSsPrs : 80|16@1+ (0.0625,0) [0|500] "bar" Vector__XXX
 SG_ Acc1SsPrs : 64|16@1+ (0.0625,0) [0|500] "bar" Vector__XXX
 SG_ PrkBrkSsPrs : 48|16@1+ (0.0625,0) [0|500] "bar" Vector__XXX
 SG_ MainSsPrs : 32|16@1+ (0.0625,0) [0|500] "bar" Vector__XXX
 SG_ WifSsVlt : 16|16@1+ (0.001,0) [0|64.255] "V" Vector__XXX
 SG_ HydOilSsTmp : 0|16@1+ (1,-40) [-40|210] "�C" Vector__XXX

BO_ 2566884129 MCU_AAAI: 16 MCU
 SG_ FanDrvTocEvc : 112|16@1+ (1,0) [0|2000] "mA" Vector__XXX
 SG_ eFan2DutyRatio : 96|16@1+ (0.01,-321.27) [-321.27|321.28] "%" Vector__XXX
 SG_ eFan3DutyRatio : 80|16@1+ (0.01,-321.27) [-321.27|321.28] "%" Vector__XXX
 SG_ eBrkEvc : 64|16@1+ (1,0) [0|2000] "mA" Vector__XXX
 SG_ eFan1DutyRatio : 48|16@1+ (0.01,-321.27) [-321.27|321.28] "%" Vector__XXX
 SG_ FanDrvRadCacEvc : 32|16@1+ (1,0) [0|2000] "mA" Vector__XXX
 SG_ BodyDnEvc : 16|16@1+ (1,0) [0|2000] "mA" Vector__XXX
 SG_ BodyUpEvc : 0|16@1+ (1,0) [0|2000] "mA" Vector__XXX

BO_ 2566884385 MCU_ADSI: 250 MCU
 SG_ StartCrkSw : 38|2@1+ (1,0) [0|3] "" Vector__XXX
 SG_ GrSelSw : 36|2@1+ (1,0) [0|3] "" Vector__XXX
 SG_ GrSelNtrlSw : 34|2@1+ (1,0) [0|3] "" Vector__XXX
 SG_ PrkSw : 32|2@1+ (1,0) [0|3] "" Vector__XXX
 SG_ GrSelRvsSw : 30|2@1+ (1,0) [0|3] "" Vector__XXX
 SG_ GrSelShftDnSw : 28|2@1+ (1,0) [0|3] "" Vector__XXX
 SG_ GrSelShftUpSw : 26|2@1+ (1,0) [0|3] "" Vector__XXX
 SG_ GrSelFwdSw : 24|2@1+ (1,0) [0|3] "" Vector__XXX
 SG_ DustIndSw : 22|2@1+ (1,0) [0|3] "" Vector__XXX
 SG_ StartAccSw : 20|2@1+ (1,0) [0|3] "" Vector__XXX
 SG_ AtsForceRgnSw : 18|2@1+ (1,0) [0|3] "" Vector__XXX
 SG_ AtsRgnIhbsw : 16|2@1+ (1,0) [0|3] "" Vector__XXX
 SG_ eFan3ErrSt : 14|2@1+ (1,0) [0|3] "" Vector__XXX
 SG_ KeyBrSw : 12|2@1+ (1,0) [0|3] "" Vector__XXX
 SG_ TipJoySw : 10|2@1+ (1,0) [0|3] "" Vector__XXX
 SG_ AgsSw : 8|2@1+ (1,0) [0|3] "" Vector__XXX
 SG_ eFan2ErrSt : 6|2@1+ (1,0) [0|3] "" Vector__XXX
 SG_ eFan1ErrSt : 4|2@1+ (1,0) [0|3] "" Vector__XXX
 SG_ SeatBeltSt : 2|2@1+ (1,0) [0|3] "" Vector__XXX
 SG_ FrWiperStpSw : 0|2@1+ (1,0) [0|3] "" Vector__XXX

BO_ 2566884641 MCU_ADAI: 250 MCU
 SG_ SusRhDn : 40|2@1+ (1,0) [0|3] "" Vector__XXX
 SG_ TocRvs : 38|2@1+ (1,0) [0|3] "" Vector__XXX
 SG_ TurnSigRhRly : 36|2@1+ (1,0) [0|3] "" Vector__XXX
 SG_ TurnSigLhRly : 34|2@1+ (1,0) [0|3] "" Vector__XXX
 SG_ SusRhUp : 32|2@1+ (1,0) [0|3] "" Vector__XXX
 SG_ EgRunOutSig : 30|2@1+ (1,0) [0|3] "" Vector__XXX
 SG_ SusLhDn : 28|2@1+ (1,0) [0|3] "" Vector__XXX
 SG_ UreaSuperChgWrnSig : 26|2@1+ (1,0) [0|3] "" Vector__XXX
 SG_ FanStpSv : 24|2@1+ (1,0) [0|3] "" Vector__XXX
 SG_ Dhl3Sig : 22|2@1+ (1,0) [0|3] "" Vector__XXX
 SG_ Dhl2Sig : 20|2@1+ (1,0) [0|3] "" Vector__XXX
 SG_ SusLhUp : 18|2@1+ (1,0) [0|3] "" Vector__XXX
 SG_ PrkBrkRlsSv : 16|2@1+ (1,0) [0|3] "" Vector__XXX
 SG_ AxleOilCoolSv : 14|2@1+ (1,0) [0|3] "" Vector__XXX
 SG_ TocUnloading : 12|2@1+ (1,0) [0|3] "" Vector__XXX
 SG_ AccRly : 10|2@1+ (1,0) [0|3] "" Vector__XXX
 SG_ RrWinHtRly : 8|2@1+ (1,0) [0|3] "" Vector__XXX
 SG_ LiftArmFlt : 6|2@1+ (1,0) [0|3] "" Vector__XXX
 SG_ AutoShutOffRly : 4|2@1+ (1,0) [0|3] "" Vector__XXX
 SG_ BrkChgSv : 2|2@1+ (1,0) [0|3] "" Vector__XXX
 SG_ Dhl1Sig : 0|2@1+ (1,0) [0|3] "" Vector__XXX

BO_ 2566884897 MCU_TIG1: 8 MCU
 SG_ RrRhTirePrs : 40|8@1+ (4,0) [0|1000] "kPa" Vector__XXX
 SG_ RrLhTirePrs : 32|8@1+ (4,0) [0|1000] "kPa" Vector__XXX
 SG_ CtrRhTirePrs : 24|8@1+ (4,0) [0|1000] "kPa" Vector__XXX
 SG_ CtrLhTirePrs : 16|8@1+ (4,0) [0|1000] "kPa" Vector__XXX
 SG_ FronRhTirePrs : 8|8@1+ (4,0) [0|1000] "kPa" Vector__XXX
 SG_ FrLhTirePrs : 0|8@1+ (4,0) [0|1000] "kPa" Vector__XXX

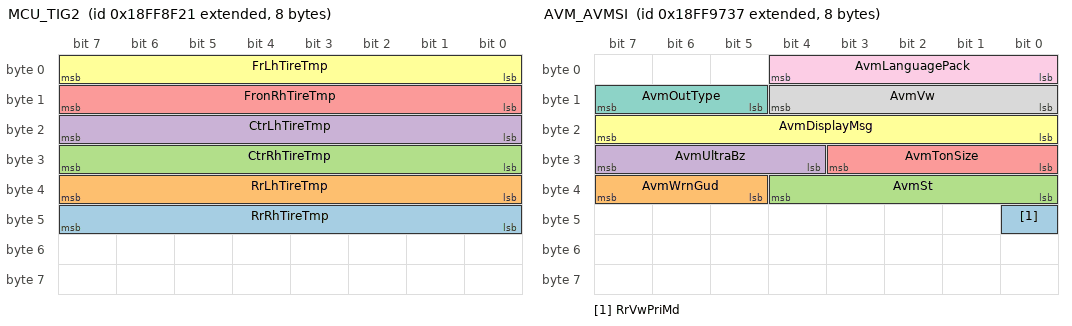
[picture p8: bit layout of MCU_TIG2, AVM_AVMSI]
BO_ 2566885153 MCU_TIG2: 8 MCU
 SG_ RrRhTireTmp : 40|8@1+ (1,-40) [-40|210] "�C" Vector__XXX
 SG_ RrLhTireTmp : 32|8@1+ (1,-40) [-40|210] "�C" Vector__XXX
 SG_ CtrRhTireTmp : 24|8@1+ (1,-40) [-40|210] "�C" Vector__XXX
 SG_ CtrLhTireTmp : 16|8@1+ (1,-40) [-40|210] "�C" Vector__XXX
 SG_ FronRhTireTmp : 8|8@1+ (1,-40) [-40|210] "�C" Vector__XXX
 SG_ FrLhTireTmp : 0|8@1+ (1,-40) [-40|210] "�C" Vector__XXX

BO_ 2566885409 MCU_QRCI: 55 MCU
 SG_ PartNo : 312|128@1+ (1,0) [0|255] "" Vector__XXX
 SG_ SerialNo : 184|128@1+ (1,0) [0|255] "" Vector__XXX
 SG_ MnftCode : 120|64@1+ (1,0) [0|255] "" Vector__XXX
 SG_ ComCode : 56|64@1+ (1,0) [0|255] "" Vector__XXX
 SG_ Year : 48|8@1+ (1,1985) [1985|2235] "year" Vector__XXX
 SG_ Day : 40|8@1+ (0.25,0) [0|62.5] "days" Vector__XXX
 SG_ Month : 32|8@1+ (1,0) [0|250] "month" Vector__XXX
 SG_ VcuSwVer : 0|32@1+ (1,0) [0|255] "" Vector__XXX

BO_ 2566885665 MCU_ECORI: 30 MCU
 SG_ TotAvgReliefOprPct : 232|8@1+ (1,0) [0|250] "%" Vector__XXX
 SG_ TotAvgLwIdleOprPct : 224|8@1+ (1,0) [0|250] "%" Vector__XXX
 SG_ TotAvgHhIdleOprPct : 216|8@1+ (1,0) [0|250] "%" Vector__XXX
 SG_ Day7ReliefOprPct : 208|8@1+ (1,0) [0|250] "%" Vector__XXX
 SG_ Day7LwIdleOprPct : 200|8@1+ (1,0) [0|250] "%" Vector__XXX
 SG_ Day7HhIdleOprPct : 192|8@1+ (1,0) [0|250] "%" Vector__XXX
 SG_ Day6ReliefOprPct : 184|8@1+ (1,0) [0|250] "%" Vector__XXX
 SG_ Day6LwIdleOprPct : 176|8@1+ (1,0) [0|250] "%" Vector__XXX
 SG_ Day6HhIdleOprPct : 168|8@1+ (1,0) [0|250] "%" Vector__XXX
 SG_ Day5ReliefOprPct : 160|8@1+ (1,0) [0|250] "%" Vector__XXX
 SG_ Day5LwIdleOprPct : 152|8@1+ (1,0) [0|250] "%" Vector__XXX
 SG_ Day5HhIdleOprPct : 144|8@1+ (1,0) [0|250] "%" Vector__XXX
 SG_ Day4ReliefOprPct : 136|8@1+ (1,0) [0|250] "%" Vector__XXX
 SG_ Day4LwIdleOprPct : 128|8@1+ (1,0) [0|250] "%" Vector__XXX
 SG_ Day4HhIdleOprPct : 120|8@1+ (1,0) [0|250] "%" Vector__XXX
 SG_ Day3ReliefOprPct : 112|8@1+ (1,0) [0|250] "%" Vector__XXX
 SG_ Day3LwIdleOprPct : 104|8@1+ (1,0) [0|250] "%" Vector__XXX
 SG_ Day3HhIdleOprPct : 96|8@1+ (1,0) [0|250] "%" Vector__XXX
 SG_ Day2ReliefOprPct : 88|8@1+ (1,0) [0|250] "%" Vector__XXX
 SG_ Day2LwIdleOprPct : 80|8@1+ (1,0) [0|250] "%" Vector__XXX
 SG_ Day2HhIdleOprPct : 72|8@1+ (1,0) [0|250] "%" Vector__XXX
 SG_ Day1ReliefOprPct : 64|8@1+ (1,0) [0|250] "%" Vector__XXX
 SG_ Day1LwIdleOprPct : 56|8@1+ (1,0) [0|250] "%" Vector__XXX
 SG_ Day1HhIdleOprPct : 48|8@1+ (1,0) [0|250] "%" Vector__XXX
 SG_ NowReliefOprLv : 40|8@1+ (1,0) [0|250] "%" Vector__XXX
 SG_ NowLwIdleOprLv : 32|8@1+ (1,0) [0|250] "%" Vector__XXX
 SG_ NowHhIdleOprLv : 24|8@1+ (1,0) [0|250] "%" Vector__XXX
 SG_ NowReliefOprPct : 16|8@1+ (1,0) [0|250] "%" Vector__XXX
 SG_ NowLwIdleOprPct : 8|8@1+ (1,0) [0|250] "%" Vector__XXX
 SG_ NowHhIdleOprPct : 0|8@1+ (1,0) [0|250] "%" Vector__XXX

BO_ 2566886586 RDRR_ROZI: 8 RDRR

BO_ 2566886587 RDLH_ROZI: 8 RDLH

BO_ 2566886588 RDRH_ROZI: 8 RDRH

BO_ 2566886842 RDRR_ROI: 8 RDRR

BO_ 2566886843 RDLH_ROI: 8 RDLH

BO_ 2566886844 RDRH_ROI: 8 RDRH

BO_ 2566886952 GP_AVMVM: 8 GP
 SG_ RrVwPriMd : 4|1@1+ (1,0) [0|1] "" Vector__XXX
 SG_ VwMd : 0|4@1+ (1,0) [0|15] "" Vector__XXX

BO_ 2566887223 AVM_AVMSI: 8 AVM
 SG_ RrVwPriMd : 40|1@1+ (1,0) [0|1] "" Vector__XXX
 SG_ AvmWrnGud : 37|3@1+ (1,0) [0|7] "" Vector__XXX
 SG_ AvmSt : 32|5@1+ (1,0) [0|31] "" Vector__XXX
 SG_ AvmUltraBz : 28|4@1+ (1,0) [0|15] "" Vector__XXX
 SG_ AvmTonSize : 24|4@1+ (1,0) [0|15] "" Vector__XXX
 SG_ AvmDisplayMsg : 16|8@1+ (1,0) [0|255] "" Vector__XXX
 SG_ AvmOutType : 13|3@1+ (1,0) [0|7] "" Vector__XXX
 SG_ AvmVw : 8|5@1+ (1,0) [0|31] "" Vector__XXX
 SG_ AvmLanguagePack : 0|5@1+ (1,0) [0|31] "" Vector__XXX

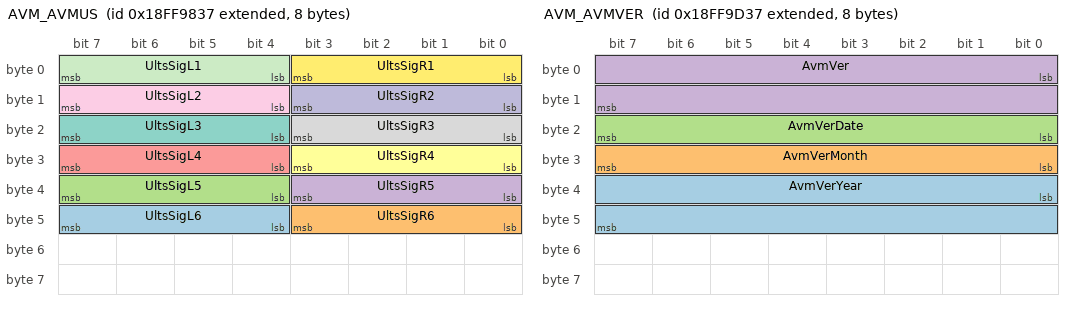
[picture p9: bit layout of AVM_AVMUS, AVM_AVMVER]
BO_ 2566887479 AVM_AVMUS: 8 AVM
 SG_ UltsSigL6 : 44|4@1+ (1,0) [0|15] "" Vector__XXX
 SG_ UltsSigR6 : 40|4@1+ (1,0) [0|15] "" Vector__XXX
 SG_ UltsSigL5 : 36|4@1+ (1,0) [0|15] "" Vector__XXX
 SG_ UltsSigR5 : 32|4@1+ (1,0) [0|15] "" Vector__XXX
 SG_ UltsSigL4 : 28|4@1+ (1,0) [0|15] "" Vector__XXX
 SG_ UltsSigR4 : 24|4@1+ (1,0) [0|15] "" Vector__XXX
 SG_ UltsSigL3 : 20|4@1+ (1,0) [0|15] "" Vector__XXX
 SG_ UltsSigR3 : 16|4@1+ (1,0) [0|15] "" Vector__XXX
 SG_ UltsSigL2 : 12|4@1+ (1,0) [0|15] "" Vector__XXX
 SG_ UltsSigR2 : 8|4@1+ (1,0) [0|15] "" Vector__XXX
 SG_ UltsSigL1 : 4|4@1+ (1,0) [0|15] "" Vector__XXX
 SG_ UltsSigR1 : 0|4@1+ (1,0) [0|15] "" Vector__XXX

BO_ 2566887720 GP_AVMRM: 8 GP
 SG_ CamPrmtCorCompleteSt : 63|1@1+ (1,0) [0|1] "" Vector__XXX
 SG_ CamPrmtVerMsb : 56|7@1+ (1,0) [0|127] "" Vector__XXX
 SG_ CamPrmtVerLsb : 48|8@1+ (1,0) [0|255] "" Vector__XXX
 SG_ Language : 42|6@1+ (1,0) [0|63] "" Vector__XXX
 SG_ ToleranceCorMenuentryCmd : 41|1@1+ (1,0) [0|1] "" Vector__XXX
 SG_ WrnGudSetCmd : 40|1@1+ (1,0) [0|1] "" Vector__XXX
 SG_ UltsSs08Cmd : 39|1@1+ (1,0) [0|1] "" Vector__XXX
 SG_ UltsSs07Cmd : 38|1@1+ (1,0) [0|1] "" Vector__XXX
 SG_ UltsSs06Cmd : 37|1@1+ (1,0) [0|1] "" Vector__XXX
 SG_ UltsSs05Cmd : 36|1@1+ (1,0) [0|1] "" Vector__XXX
 SG_ UltsSs04Cmd : 35|1@1+ (1,0) [0|1] "" Vector__XXX
 SG_ UltsSs03Cmd : 34|1@1+ (1,0) [0|1] "" Vector__XXX
 SG_ UltsSs02Cmd : 33|1@1+ (1,0) [0|1] "" Vector__XXX
 SG_ UltsSs01Cmd : 32|1@1+ (1,0) [0|1] "" Vector__XXX
 SG_ UltsSs12Cmd : 31|1@1+ (1,0) [0|1] "" Vector__XXX
 SG_ UltsSs11Cmd : 30|1@1+ (1,0) [0|1] "" Vector__XXX
 SG_ UltsSs10Cmd : 29|1@1+ (1,0) [0|1] "" Vector__XXX
 SG_ UltsSs09Cmd : 28|1@1+ (1,0) [0|1] "" Vector__XXX
 SG_ SetApplicationCmd : 27|1@1+ (1,0) [0|1] "" Vector__XXX
 SG_ ToleranceCorCmd : 25|2@1+ (1,0) [0|3] "" Vector__XXX
 SG_ FactoryReCmd : 24|1@1+ (1,0) [0|1] "" Vector__XXX
 SG_ UltsSsOpt : 23|1@1+ (1,0) [0|1] "" Vector__XXX
 SG_ UltsBuzzerStopSig : 22|1@1+ (1,0) [0|1] "" Vector__XXX
 SG_ BoomCamOpt : 21|1@1+ (1,0) [0|1] "" Vector__XXX
 SG_ UltsBzOffSig : 20|1@1+ (1,0) [0|1] "" Vector__XXX
 SG_ UltsRecognitionDistanceSet : 19|1@1+ (1,0) [0|1] "" Vector__XXX
 SG_ VhcType2 : 17|2@1+ (1,0) [0|3] "" Vector__XXX
 SG_ VhcType1 : 16|1@1+ (1,0) [0|1] "" Vector__XXX
 SG_ TonsOftheTensDigit : 12|4@1+ (1,0) [0|15] "" Vector__XXX
 SG_ TonsOftheUnitsDigit : 8|4@1+ (1,0) [0|15] "" Vector__XXX
 SG_ FactoryType : 4|4@1+ (1,0) [0|15] "" Vector__XXX
 SG_ VwMd : 0|4@1+ (1,0) [0|15] "" Vector__XXX

BO_ 2566887991 AVM_AVMSM: 8 AVM
 SG_ CamPrmtCorCompleteSt : 63|1@1+ (1,0) [0|1] "" Vector__XXX
 SG_ CamPrmtVerMsb : 56|7@1+ (1,0) [0|127] "" Vector__XXX
 SG_ CamPrmtVerLsb : 48|8@1+ (1,0) [0|255] "" Vector__XXX
 SG_ Language : 42|6@1+ (1,0) [0|63] "" Vector__XXX
 SG_ ToleranceCorMenuentryCmd : 41|1@1+ (1,0) [0|1] "" Vector__XXX
 SG_ WrnGudSetCmd : 40|1@1+ (1,0) [0|1] "" Vector__XXX
 SG_ UltsSs08Cmd : 39|1@1+ (1,0) [0|1] "" Vector__XXX
 SG_ UltsSs07Cmd : 38|1@1+ (1,0) [0|1] "" Vector__XXX
 SG_ UltsSs06Cmd : 37|1@1+ (1,0) [0|1] "" Vector__XXX
 SG_ UltsSs05Cmd : 36|1@1+ (1,0) [0|1] "" Vector__XXX
 SG_ UltsSs04Cmd : 35|1@1+ (1,0) [0|1] "" Vector__XXX
 SG_ UltsSs03Cmd : 34|1@1+ (1,0) [0|1] "" Vector__XXX
 SG_ UltsSs02Cmd : 33|1@1+ (1,0) [0|1] "" Vector__XXX
 SG_ UltsSs01Cmd : 32|1@1+ (1,0) [0|1] "" Vector__XXX
 SG_ UltsSs12Cmd : 31|1@1+ (1,0) [0|1] "" Vector__XXX
 SG_ UltsSs11Cmd : 30|1@1+ (1,0) [0|1] "" Vector__XXX
 SG_ UltsSs10Cmd : 29|1@1+ (1,0) [0|1] "" Vector__XXX
 SG_ UltsSs09Cmd : 28|1@1+ (1,0) [0|1] "" Vector__XXX
 SG_ SetAppCmd : 27|1@1+ (1,0) [0|1] "" Vector__XXX
 SG_ ToleranceCorCmd : 25|2@1+ (1,0) [0|3] "" Vector__XXX
 SG_ FactoryResetCmd : 24|1@1+ (1,0) [0|1] "" Vector__XXX
 SG_ UltsSsOpt : 23|1@1+ (1,0) [0|1] "" Vector__XXX
 SG_ UltsBzStopSig : 22|1@1+ (1,0) [0|1] "" Vector__XXX
 SG_ BoomCamOpt : 21|1@1+ (1,0) [0|1] "" Vector__XXX
 SG_ UltsBzOffSig : 20|1@1+ (1,0) [0|1] "" Vector__XXX
 SG_ UltsRecognitionDistanceSet : 19|1@1+ (1,0) [0|1] "" Vector__XXX
 SG_ VhcType2 : 17|2@1+ (1,0) [0|3] "" Vector__XXX
 SG_ VhcType1 : 16|1@1+ (1,0) [0|1] "" Vector__XXX
 SG_ TonsOftheTensDigit : 12|4@1+ (1,0) [0|15] "" Vector__XXX
 SG_ TonsOftheUnitsDigit : 8|4@1+ (1,0) [0|15] "" Vector__XXX
 SG_ FactoryType : 4|4@1+ (1,0) [0|15] "" Vector__XXX
 SG_ VwMd : 0|4@1+ (1,0) [0|15] "" Vector__XXX

BO_ 2566888503 AVM_AVMCP: 96 AVM
 SG_ AvmCamPrmt4 : 672|96@1+ (1,0) [0|7.92281625142643E+028] "" Vector__XXX
 SG_ AvmCamPrmt3 : 448|224@1+ (1,0) [0|2.69599466671506E+067] "" Vector__XXX
 SG_ AvmCamPrmt2 : 224|224@1+ (1,0) [0|2.69599466671506E+067] "" Vector__XXX
 SG_ AvmCamPrmt1 : 0|224@1+ (1,0) [0|2.69599466671506E+067] "" Vector__XXX

BO_ 2566888759 AVM_AVMVER: 8 AVM
 SG_ AvmVerYear : 32|16@1+ (16,0) [0|0] "" Vector__XXX
 SG_ AvmVerMonth : 24|8@1+ (8,0) [0|0] "" Vector__XXX
 SG_ AvmVerDate : 16|8@1+ (8,0) [0|0] "" Vector__XXX
 SG_ AvmVer : 0|16@1+ (16,0) [0|0] "" Vector__XXX

BO_ 2566889388 CHMSL_CHMSLI: 8 CHMSL

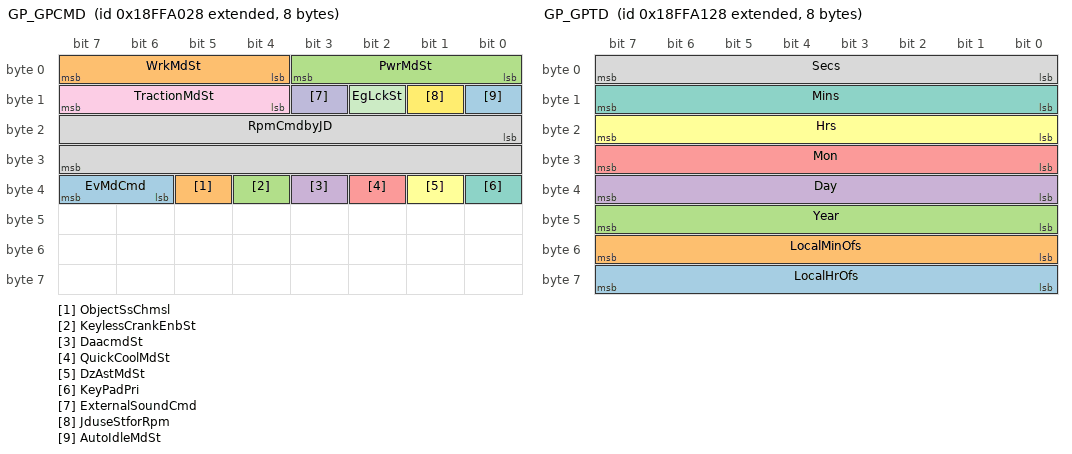
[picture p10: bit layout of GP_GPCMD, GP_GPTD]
BO_ 2566889512 GP_GPCMD: 8 GP
 SG_ EvMdCmd : 38|2@1+ (1,0) [0|3] "" Vector__XXX
 SG_ ObjectSsChmsl : 37|1@1+ (1,0) [0|1] "" Vector__XXX
 SG_ KeylessCrankEnbSt : 36|1@1+ (1,0) [0|1] "" Vector__XXX
 SG_ DaacmdSt : 35|1@1+ (1,0) [0|1] "" Vector__XXX
 SG_ QuickCoolMdSt : 34|1@1+ (1,0) [0|1] "" Vector__XXX
 SG_ DzAstMdSt : 33|1@1+ (1,0) [0|1] "" Vector__XXX
 SG_ KeyPadPri : 32|1@1+ (1,0) [0|1] "" Vector__XXX
 SG_ RpmCmdbyJD : 16|16@1+ (0.001,0) [0|64.255] "" Vector__XXX
 SG_ TractionMdSt : 12|4@1+ (1,0) [0|15] "" Vector__XXX
 SG_ ExternalSoundCmd : 11|1@1+ (1,0) [0|1] "" Vector__XXX
 SG_ EgLckSt : 10|1@1+ (1,0) [0|1] "" Vector__XXX
 SG_ JduseStforRpm : 9|1@1+ (1,0) [0|1] "" Vector__XXX
 SG_ AutoIdleMdSt : 8|1@1+ (1,0) [0|1] "" Vector__XXX
 SG_ WrkMdSt : 4|4@1+ (1,0) [0|15] "" Vector__XXX
 SG_ PwrMdSt : 0|4@1+ (1,0) [0|15] "" Vector__XXX

BO_ 2566889768 GP_GPTD: 8 GP
 SG_ LocalHrOfs : 56|8@1+ (1,-125) [-125|125] "" Vector__XXX
 SG_ LocalMinOfs : 48|8@1+ (1,-125) [-125|125] "" Vector__XXX
 SG_ Year : 40|8@1+ (1,1985) [1985|2235] "" Vector__XXX
 SG_ Day : 32|8@1+ (0.25,0) [0|62.5] "" Vector__XXX
 SG_ Mon : 24|8@1+ (1,0) [0|250] "" Vector__XXX
 SG_ Hrs : 16|8@1+ (1,0) [0|250] "" Vector__XXX
 SG_ Mins : 8|8@1+ (1,0) [0|250] "" Vector__XXX
 SG_ Secs : 0|8@1+ (0.25,0) [0|62.5] "" Vector__XXX

BO_ 2566890024 GP_SVGP: 21 GP
 SG_ AvmSwVer : 136|32@1+ (1,0) [0|255] "" Vector__XXX
 SG_ AvmSwVerYear : 128|8@1+ (1,1985) [1985|2235] "" Vector__XXX
 SG_ AvmSwVerDay : 120|8@1+ (0.25,0) [0|62.5] "" Vector__XXX
 SG_ AvmSwVerMon : 112|8@1+ (1,0) [0|250] "" Vector__XXX
 SG_ GpOsSwVer : 80|32@1+ (1,0) [0|255] "" Vector__XXX
 SG_ GpOsSwVerYear : 72|8@1+ (1,1985) [1985|2235] "" Vector__XXX
 SG_ GpOsSwVerDay : 64|8@1+ (0.25,0) [0|62.5] "" Vector__XXX
 SG_ GpOsSwVerMon : 56|8@1+ (1,0) [0|250] "" Vector__XXX
 SG_ GpAppSwVer : 24|32@1+ (1,0) [0|255] "" Vector__XXX
 SG_ GpAppSwVerYear : 16|8@1+ (1,1985) [1985|2235] "" Vector__XXX
 SG_ GpAppSwVerDay : 8|8@1+ (0.25,0) [0|62.5] "" Vector__XXX
 SG_ GpAppSwVerMon : 0|8@1+ (1,0) [0|250] "" Vector__XXX

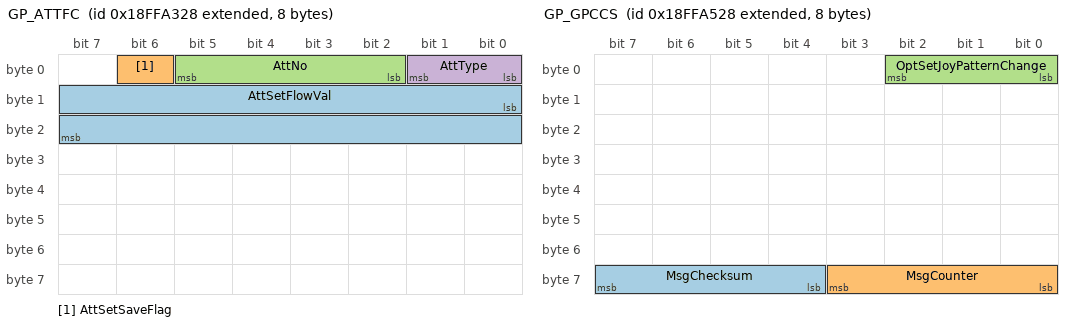
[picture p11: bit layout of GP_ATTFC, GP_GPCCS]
BO_ 2566890280 GP_ATTFC: 8 GP
 SG_ AttSetFlowVal : 8|16@1+ (1,0) [0|65000] "lpm" Vector__XXX
 SG_ AttSetSaveFlag : 6|1@1+ (1,0) [0|1] "" Vector__XXX
 SG_ AttNo : 2|4@1+ (1,0) [0|15] "" Vector__XXX
 SG_ AttType : 0|2@1+ (1,0) [0|3] "" Vector__XXX

BO_ 2566890536 GP_MG2DBC: 8 GP
 SG_ MgSoundGudStep : 3|4@1+ (1,0) [0|15] "" Vector__XXX
 SG_ AlmSt : 0|3@1+ (1,0) [0|7] "" Vector__XXX

BO_ 2566890561 GW_MG2DBC: 11 GW
 SG_ MgSoundGudStep : 3|4@1+ (1,0) [0|15] "" Vector__XXX
 SG_ AlmSt : 0|3@1+ (1,0) [0|7] "" Vector__XXX

BO_ 2566890792 GP_GPCCS: 8 GP
 SG_ MsgChecksum : 60|4@1+ (1,0) [0|15] "count" Vector__XXX
 SG_ MsgCounter : 56|4@1+ (1,0) [0|15] "count" Vector__XXX
 SG_ OptSetJoyPatternChange : 0|3@1+ (1,0) [0|7] "" Vector__XXX

BO_ 2566891041 MCU_ZFIMP: 8 MCU

BO_ 2566891688 CTC_CAV: 8 CTC

BO_ 2566892072 GP_DCAP: 8 GP
 SG_ ReqCallIndex : 48|4@1+ (1,0) [0|15] "" Vector__XXX
 SG_ PairingRequest : 46|2@1+ (1,0) [0|3] "" Vector__XXX
 SG_ HangUpBtn : 44|2@1+ (1,0) [0|3] "" Vector__XXX
 SG_ DabSel : 42|2@1+ (1,0) [0|3] "" Vector__XXX
 SG_ MdSel : 40|2@1+ (1,0) [0|3] "" Vector__XXX
 SG_ AudioVolDownSel : 38|2@1+ (1,0) [0|3] "" Vector__XXX
 SG_ AudioVolUpSel : 36|2@1+ (1,0) [0|3] "" Vector__XXX
 SG_ BandSel : 34|2@1+ (1,0) [0|3] "" Vector__XXX
 SG_ TalkBtn : 32|2@1+ (1,0) [0|3] "" Vector__XXX
 SG_ AudioTuneDownSel : 30|2@1+ (1,0) [0|3] "" Vector__XXX
 SG_ AudioCallListPopupSt : 28|2@1+ (1,0) [0|3] "" Vector__XXX
 SG_ AudioMenuSel : 26|2@1+ (1,0) [0|3] "" Vector__XXX
 SG_ AudioPowerSel : 24|2@1+ (1,0) [0|3] "" Vector__XXX
 SG_ AudioP5Sel : 22|2@1+ (1,0) [0|3] "" Vector__XXX
 SG_ AudioP6Sel : 20|2@1+ (1,0) [0|3] "" Vector__XXX
 SG_ AudioTuneSel : 18|2@1+ (1,0) [0|3] "" Vector__XXX
 SG_ AudioTuneUpSel : 16|2@1+ (1,0) [0|3] "" Vector__XXX
 SG_ AudioP1Sel : 14|2@1+ (1,0) [0|3] "" Vector__XXX
 SG_ AudioP2Sel : 12|2@1+ (1,0) [0|3] "" Vector__XXX
 SG_ AudioP3Sel : 10|2@1+ (1,0) [0|3] "" Vector__XXX
 SG_ AudioP4Sel : 8|2@1+ (1,0) [0|3] "" Vector__XXX
 SG_ AudioAmSel : 6|2@1+ (1,0) [0|3] "" Vector__XXX
 SG_ AudioFmSel : 4|2@1+ (1,0) [0|3] "" Vector__XXX
 SG_ AudioUsbSel : 2|2@1+ (1,0) [0|3] "" Vector__XXX
 SG_ AudioAuxSel : 0|2@1+ (1,0) [0|3] "" Vector__XXX

BO_ 2566892448 Audio_APLGP: 250 Audio

BO_ 2566892704 Audio_ALITGP: 250 Audio

BO_ 2566892960 Audio_ADLSGP: 250 Audio

BO_ 2566893216 Audio_AICTGP: 250 Audio

BO_ 2566893472 Audio_ATG: 250 Audio

CM_ BO_ 2566866977 "Gauge Data Group 2";
CM_ SG_ 2566866977 TrgRollSlp "TargetRollSlope";
CM_ SG_ 2566866977 TrgPchSlp "TargetPitchSlope";
CM_ SG_ 2566866977 CorrRollSlp "CorrectedRollSlope";
CM_ SG_ 2566866977 CorrPchSlp "CorrectedPitchSlope";
CM_ SG_ 2566866977 CorrRollAng "CorrectedRollAngle";
CM_ SG_ 2566866977 CorrPchAng "CorrectedPitchAngle";
CM_ BO_ 2566867233 "Gauge Data Group 3";
CM_ SG_ 2566867233 TrgRollSlp "TargetRollSlope";
CM_ SG_ 2566867233 TrgPchSlp "TargetPitchSlope";
CM_ SG_ 2566867233 CorrRollSlp "CorrectedRollSlope";
CM_ SG_ 2566867233 CorrPchSlp "CorrectedPitchSlope";
CM_ BO_ 2566867489 "State Information Group 4";
CM_ SG_ 2566867489 HpApMd "HP/APMode";
CM_ SG_ 2566867489 GrLmt "VehicleStateSymbol;GearLimit";
CM_ SG_ 2566867489 BodyAng "BodyAngle";
CM_ SG_ 2566867489 WghSt "WeightState";
CM_ SG_ 2566867489 BrkHold "VehicleStateSymbol;BrakeHold";
CM_ SG_ 2566867489 RtrdSt "RetarderState";
CM_ SG_ 2566867489 PilotCutOffSt "VehicleStateSymbol;PilotCutOffStatus";
CM_ SG_ 2566867489 BodySt "IndicatorSymbol;Bodystate";
CM_ SG_ 2566867489 VhcStGndSaw "VehicleStateSymbol;GroundSaw";
CM_ SG_ 2566867489 VhcStIntAxleLck "VehicleStateSymbol;InterAxleLock";
CM_ SG_ 2566867489 TrlHhFlowMd "TrackLoaderTypeGraphic;HighFlowMode";
CM_ SG_ 2566867489 ExcAutoBrkAntiFire "ExcavatorTypeSymbol;AutoBreaker,AntiBlankFireIndicator";
CM_ SG_ 2566867489 TrlIntLckOvrd "TrackLoaderTypeSymbol;InterlockOverride";
CM_ SG_ 2566867489 TrlCtrlFlow "TrackLoaderTypeSymbol;ContinuousFlowIndicator";
CM_ SG_ 2566867489 TrlSelfLv "TrackLoaderTypeSymbol;SelfLevelIndicator";
CM_ SG_ 2566867489 TrlHhFlow "TrackLoaderTypeSymbol;HighFlowIndicator";
CM_ BO_ 2566867745 "Gauge Data Group 4";
CM_ SG_ 2566867745 EcoGgSt "EcoGaugeStatus";
CM_ SG_ 2566867745 EcoGgLv "EcoGaugeLevel";
CM_ BO_ 2566868257 "Mech. Engine TPS Calibration ";
CM_ SG_ 2566868257 MaximumEgSpd "MaximumRpm";
CM_ SG_ 2566868257 AutoCalbMd "AutoCalibrationMode";
CM_ SG_ 2566868257 CalbReq "RequestCalibration";
CM_ SG_ 2566868257 VhcStTpsCalb "VehicelState(2bit)-TPSCalibrationState";
CM_ SG_ 2566868257 MinimumEgSpd "MinimumRpm";
CM_ SG_ 2566868257 VhcStSsNrm "VehicelState(1bit)-????";
CM_ SG_ 2566868257 VhcStEgIgn "VehicelState(1bit)-????";
CM_ SG_ 2566868257 VhcStPilotCutOff "VehicelState(1bit)-??????";
CM_ SG_ 2566868257 VhcStEgCtrlDialMax "VehicelState(1bit)-??????????";
CM_ BO_ 2566868921 "Engine Dial Output";
CM_ BO_ 2566869025 "Jog Shuttle Output";
CM_ BO_ 2566869158 "Jog Shuttle Output";
CM_ BO_ 2365542696 "Jog Control Message";
CM_ SG_ 2365542696 PwforthisMsg "Passwordforthismessage";
CM_ SG_ 2365542696 EncoderDtDefineMax "EncoderData,DefineMaximum";
CM_ SG_ 2365542696 BrctRateforDtPck "BroadcastingrateforDataPackage";
CM_ SG_ 2365542696 PgnforDtPck "PGNforDataPackage";
CM_ SG_ 2365542696 SrcAd "SourceAddress(CommandedAddress)";
CM_ SG_ 2365542696 BacklightIntensity "BacklightIntensity";
CM_ BO_ 2365542917 "ZFTC1";
CM_ BO_ 2365543201 "KeyPad Basic Indicate";
CM_ BO_ 2365543504 "KeyPad Signal";
CM_ BO_ 2365543713 "KeyPad Indicate 1";
CM_ BO_ 2365543969 "KeyPad Machine Indicate 1";
CM_ BO_ 2365544225 "KeyPad Machine Indicate 2";
CM_ BO_ 2365544481 "KeyPad Indicate 2";
CM_ BO_ 2365544737 "KeyPad Indicate 3";
CM_ BO_ 2566871629 "Horn Command";
CM_ BO_ 2566872001 "Accelleration Sensor Information";
CM_ BO_ 2566872002 "Accelleration Sensor Information";
CM_ BO_ 2566872003 "Accelleration Sensor Information";
CM_ BO_ 2566872004 "Accelleration Sensor Information";
CM_ BO_ 2566872005 "Accelleration Sensor Information";
CM_ BO_ 2365545552 "KeyPad Signal 2";
CM_ BO_ 2365545761 "KeyPad Indicate 4";
CM_ BO_ 2566873377 "ACU Control";
CM_ SG_ 2566873377 LowOutReq8 "LowOutputrequest#8";
CM_ SG_ 2566873377 LowOutReq7 "LowOutputrequest#7";
CM_ SG_ 2566873377 LowOutReq6 "LowOutputrequest#6";
CM_ SG_ 2566873377 LowOutReq5 "LowOutputrequest#5";
CM_ SG_ 2566873377 LowOutReq4 "LowOutputrequest#4";
CM_ SG_ 2566873377 LowOutReq3 "LowOutputrequest#3";
CM_ SG_ 2566873377 LowOutReq2 "LowOutputrequest#2";
CM_ SG_ 2566873377 LowOutReq1 "LowOutputrequest#1";
CM_ SG_ 2566873377 OutReq15 "Outputrequest#15";
CM_ SG_ 2566873377 OutReq14 "Outputrequest#14";
CM_ SG_ 2566873377 OutReq13 "Outputrequest#13";
CM_ SG_ 2566873377 OutReq12 "Outputrequest#12";
CM_ SG_ 2566873377 OutReq11 "Outputrequest#11";
CM_ SG_ 2566873377 OutReq10 "Outputrequest#10";
CM_ SG_ 2566873377 OutReq9 "Outputrequest#9";
CM_ SG_ 2566873377 OutReq8 "Outputrequest#8";
CM_ SG_ 2566873377 OutReq7 "Outputrequest#7";
CM_ SG_ 2566873377 OutReq6 "Outputrequest#6";
CM_ SG_ 2566873377 OutReq5 "Outputrequest#5";
CM_ SG_ 2566873377 OutReq4 "Outputrequest#4";
CM_ SG_ 2566873377 OutReq3 "Outputrequest#3";
CM_ SG_ 2566873377 OutReq2 "Outputrequest#2";
CM_ SG_ 2566873377 OutReq1 "Outputrequest#1";
CM_ BO_ 2566873630 "ACU Feedback1";
CM_ SG_ 2566873630 OutFdbkCur8 "OutputFeedbackCurrent#8";
CM_ SG_ 2566873630 OutFdbkCur7 "OutputFeedbackCurrent#7";
CM_ SG_ 2566873630 OutFdbkCur6 "OutputFeedbackCurrent#6";
CM_ SG_ 2566873630 OutFdbkCur5 "OutputFeedbackCurrent#5";
CM_ SG_ 2566873630 OutFdbkCur4 "OutputFeedbackCurrent#4";
CM_ SG_ 2566873630 OutFdbkCur3 "OutputFeedbackCurrent#3";
CM_ SG_ 2566873630 OutFdbkCur2 "OutputFeedbackCurrent#2";
CM_ SG_ 2566873630 OutFdbkCur1 "OutputFeedbackCurrent#1";
CM_ BO_ 2566873767 "ACU Feedback1";
CM_ SG_ 2566873767 OutFdbkCur8 "OutputFeedbackCurrent#8";
CM_ SG_ 2566873767 OutFdbkCur7 "OutputFeedbackCurrent#7";
CM_ SG_ 2566873767 OutFdbkCur6 "OutputFeedbackCurrent#6";
CM_ SG_ 2566873767 OutFdbkCur5 "OutputFeedbackCurrent#5";
CM_ SG_ 2566873767 OutFdbkCur4 "OutputFeedbackCurrent#4";
CM_ SG_ 2566873767 OutFdbkCur3 "OutputFeedbackCurrent#3";
CM_ SG_ 2566873767 OutFdbkCur2 "OutputFeedbackCurrent#2";
CM_ SG_ 2566873767 OutFdbkCur1 "OutputFeedbackCurrent#1";
CM_ BO_ 2566873886 "ACU Feedback2";
CM_ SG_ 2566873886 ErrorFlag "ErrorFlag";
CM_ SG_ 2566873886 VltIn2 "VoltageInput#2";
CM_ SG_ 2566873886 VltIn1 "VoltageInput#1";
CM_ SG_ 2566873886 OutFdbkCur13 "OutputFeedbackCurrent#13";
CM_ SG_ 2566873886 OutFdbkCur12 "OutputFeedbackCurrent#12";
CM_ SG_ 2566873886 OutFdbkCur11 "OutputFeedbackCurrent#11";
CM_ SG_ 2566873886 OutFdbkCur10 "OutputFeedbackCurrent#10";
CM_ SG_ 2566873886 OutFdbkCur9 "OutputFeedbackCurrent#9";
CM_ BO_ 2566874654 "ACU Feedback3";
CM_ SG_ 2566874654 OutFdbkActvLowCur8 "OutputFeedbackActiveLowCurrent#8";
CM_ SG_ 2566874654 OutFdbkActvLowCur7 "OutputFeedbackActiveLowCurrent#7";
CM_ SG_ 2566874654 OutFdbkActvLowCur6 "OutputFeedbackActiveLowCurrent#6";
CM_ SG_ 2566874654 OutFdbkActvLowCur5 "OutputFeedbackActiveLowCurrent#5";
CM_ SG_ 2566874654 OutFdbkActvLowCur4 "OutputFeedbackActiveLowCurrent#4";
CM_ SG_ 2566874654 OutFdbkActvLowCur3 "OutputFeedbackActiveLowCurrent#3";
CM_ SG_ 2566874654 OutFdbkActvLowCur2 "OutputFeedbackActiveLowCurrent#2";
CM_ SG_ 2566874654 OutFdbkActvLowCur1 "OutputFeedbackActiveLowCurrent#1";
CM_ SG_ 2566874654 OutFdbkActvHighCur15 "OutputFeedbackActiveHighCurrent#15";
CM_ SG_ 2566874654 OutFdbkActvHighCur14 "OutputFeedbackActiveHighCurrent#14";
CM_ SG_ 2566874654 OutFdbkActvHighCur13 "OutputFeedbackActiveHighCurrent#13";
CM_ SG_ 2566874654 OutFdbkActvHighCur12 "OutputFeedbackActiveHighCurrent#12";
CM_ SG_ 2566874654 OutFdbkActvHighCur11 "OutputFeedbackActiveHighCurrent#11";
CM_ SG_ 2566874654 OutFdbkActvHighCur10 "OutputFeedbackActiveHighCurrent#10";
CM_ SG_ 2566874654 OutFdbkActvHighCur9 "OutputFeedbackActiveHighCurrent#9";
CM_ SG_ 2566874654 OutFdbkActvHighCur8 "OutputFeedbackActiveHighCurrent#8";
CM_ SG_ 2566874654 OutFdbkActvHighCur7 "OutputFeedbackActiveHighCurrent#7";
CM_ SG_ 2566874654 OutFdbkActvHighCur6 "OutputFeedbackActiveHighCurrent#6";
CM_ SG_ 2566874654 OutFdbkActvHighCur5 "OutputFeedbackActiveHighCurrent#5";
CM_ SG_ 2566874654 OutFdbkActvHighCur4 "OutputFeedbackActiveHighCurrent#4";
CM_ SG_ 2566874654 OutFdbkActvHighCur3 "OutputFeedbackActiveHighCurrent#3";
CM_ SG_ 2566874654 OutFdbkActvHighCur2 "OutputFeedbackActiveHighCurrent#2";
CM_ SG_ 2566874654 OutFdbkActvHighCur1 "OutputFeedbackActiveHighCurrent#1";
CM_ BO_ 2566874910 "ACU Feedback4";
CM_ SG_ 2566874910 InVlt12 "InputVoltage#12";
CM_ SG_ 2566874910 InVlt11 "InputVoltage#11";
CM_ SG_ 2566874910 InVlt10 "InputVoltage#10";
CM_ SG_ 2566874910 InVlt9 "InputVoltage#9";
CM_ SG_ 2566874910 InVlt8 "InputVoltage#8";
CM_ SG_ 2566874910 InVlt7 "InputVoltage#7";
CM_ SG_ 2566874910 InVlt6 "InputVoltage#6";
CM_ SG_ 2566874910 InVlt5 "InputVoltage#5";
CM_ SG_ 2566874910 InVlt4 "InputVoltage#4";
CM_ SG_ 2566874910 InVlt3 "InputVoltage#3";
CM_ SG_ 2566874910 InVlt2 "InputVoltage#2";
CM_ SG_ 2566874910 InVlt1 "InputVoltage#1";
CM_ BO_ 2566875297 "KeyPad AirCon Command";
CM_ BO_ 2566875422 "ACU Feedback5";
CM_ SG_ 2566875422 OutFdbkCur12 "OutputFeedbackCurrent#12";
CM_ SG_ 2566875422 OutFdbkCur11 "OutputFeedbackCurrent#11";
CM_ SG_ 2566875422 OutFdbkCur10 "OutputFeedbackCurrent#10";
CM_ SG_ 2566875422 OutFdbkCur9 "OutputFeedbackCurrent#9";
CM_ BO_ 2566875559 "ACU Feedback5";
CM_ SG_ 2566875559 OutFdbkCur12 "OutputFeedbackCurrent#12";
CM_ SG_ 2566875559 OutFdbkCur11 "OutputFeedbackCurrent#11";
CM_ SG_ 2566875559 OutFdbkCur10 "OutputFeedbackCurrent#10";
CM_ SG_ 2566875559 OutFdbkCur9 "OutputFeedbackCurrent#9";
CM_ BO_ 2566875678 "ACU Feedback6";
CM_ SG_ 2566875678 MiniRly30AFuse2St "MiniRelay30AFuse#2Status";
CM_ SG_ 2566875678 MiniRly30AFuse1St "MiniRelay30AFuse#1Status";
CM_ SG_ 2566875678 MicroRly20AFuse5St "MicroRelay20AFuse#5Status";
CM_ SG_ 2566875678 MicroRly20AFuse4St "MicroRelay20AFuse#4Status";
CM_ SG_ 2566875678 MicroRly20AFuse3St "MicroRelay20AFuse#3Status";
CM_ SG_ 2566875678 MicroRly20AFuse2St "MicroRelay20AFuse#2Status";
CM_ SG_ 2566875678 MicroRly20AFuse1St "MicroRelay20AFuse#1Status";
CM_ SG_ 2566875678 KeyOn30AFuse5St "KeyOn30AFuse#5Status";
CM_ SG_ 2566875678 KeyOn30AFuse4St "KeyOn30AFuse#4Status";
CM_ SG_ 2566875678 KeyOn30AFuse3St "KeyOn30AFuse#3Status";
CM_ SG_ 2566875678 KeyOn30AFuse2St "KeyOn30AFuse#2Status";
CM_ SG_ 2566875678 KeyOn30AFuse1St "KeyOn30AFuse#1Status";
CM_ SG_ 2566875678 KeyOn20AFuse10St "KeyOn20AFuse#10Status";
CM_ SG_ 2566875678 KeyOn20AFuse9St "KeyOn20AFuse#9Status";
CM_ SG_ 2566875678 KeyOn20AFuse8St "KeyOn20AFuse#8Status";
CM_ SG_ 2566875678 KeyOn20AFuse7St "KeyOn20AFuse#7Status";
CM_ SG_ 2566875678 KeyOn20AFuse6St "KeyOn20AFuse#6Status";
CM_ SG_ 2566875678 KeyOn20AFuse5St "KeyOn20AFuse#5Status";
CM_ SG_ 2566875678 KeyOn20AFuse4St "KeyOn20AFuse#4Status";
CM_ SG_ 2566875678 KeyOn20AFuse3St "KeyOn20AFuse#3Status";
CM_ SG_ 2566875678 KeyOn20AFuse2St "KeyOn20AFuse#2Status";
CM_ SG_ 2566875678 KeyOn20AFuse1St "KeyOn20AFuse#1Status";
CM_ SG_ 2566875678 KeyOn10AFuse5St "KeyOn10AFuse#5Status";
CM_ SG_ 2566875678 KeyOn10AFuse4St "KeyOn10AFuse#4Status";
CM_ SG_ 2566875678 KeyOn10AFuse3St "KeyOn10AFuse#3Status";
CM_ SG_ 2566875678 KeyOn10AFuse2St "KeyOn10AFuse#2Status";
CM_ SG_ 2566875678 KeyOn10AFuse1St "KeyOn10AFuse#1Status";
CM_ SG_ 2566875678 KeyOn5AFuse15St "KeyOn5AFuse#15Status";
CM_ SG_ 2566875678 KeyOn5AFuse14St "KeyOn5AFuse#14Status";
CM_ SG_ 2566875678 KeyOn5AFuse13St "KeyOn5AFuse#13Status";
CM_ SG_ 2566875678 KeyOn5AFuse12St "KeyOn5AFuse#12Status";
CM_ SG_ 2566875678 KeyOn5AFuse11St "KeyOn5AFuse#11Status";
CM_ SG_ 2566875678 KeyOn5AFuse10St "KeyOn5AFuse#10Status";
CM_ SG_ 2566875678 KeyOn5AFuse9St "KeyOn5AFuse#9Status";
CM_ SG_ 2566875678 KeyOn5AFuse8St "KeyOn5AFuse#8Status";
CM_ SG_ 2566875678 KeyOn5AFuse7St "KeyOn5AFuse#7Status";
CM_ SG_ 2566875678 KeyOn5AFuse6St "KeyOn5AFuse#6Status";
CM_ SG_ 2566875678 KeyOn5AFuse5St "KeyOn5AFuse#5Status";
CM_ SG_ 2566875678 KeyOn5AFuse4St "KeyOn5AFuse#4Status";
CM_ SG_ 2566875678 KeyOn5AFuse3St "KeyOn5AFuse#3Status";
CM_ SG_ 2566875678 KeyOn5AFuse2St "KeyOn5AFuse#2Status";
CM_ SG_ 2566875678 KeyOn5AFuse1St "KeyOn5AFuse#1Status";
CM_ SG_ 2566875678 BPlus30AFuse5St "B+30AFuse#5Status";
CM_ SG_ 2566875678 BPlus30AFuse4St "B+30AFuse#4Status";
CM_ SG_ 2566875678 BPlus30AFuse3St "B+30AFuse#3Status";
CM_ SG_ 2566875678 BPlus30AFuse2St "B+30AFuse#2Status";
CM_ SG_ 2566875678 BPlus30AFuse1St "B+30AFuse#1Status";
CM_ SG_ 2566875678 BPlus20AFuse5St "B+20AFuse#5Status";
CM_ SG_ 2566875678 BPlus20AFuse4St "B+20AFuse#4Status";
CM_ SG_ 2566875678 BPlus20AFuse3St "B+20AFuse#3Status";
CM_ SG_ 2566875678 BPlus20AFuse2St "B+20AFuse#2Status";
CM_ SG_ 2566875678 BPlus20AFuse1St "B+20AFuse#1Status";
CM_ SG_ 2566875678 BPlus5AFuse10St "B+5AFuse#10Status";
CM_ SG_ 2566875678 BPlus5AFuse9St "B+5AFuse#9Status";
CM_ SG_ 2566875678 BPlus5AFuse8St "B+5AFuse#8Status";
CM_ SG_ 2566875678 BPlus5AFuse7St "B+5AFuse#7Status";
CM_ SG_ 2566875678 BPlus5AFuse6St "B+5AFuse#6Status";
CM_ SG_ 2566875678 BPlus5AFuse5St "B+5AFuse#5Status";
CM_ SG_ 2566875678 BPlus5AFuse4St "B+5AFuse#4Status";
CM_ SG_ 2566875678 BPlus5AFuse3St "B+5AFuse#3Status";
CM_ SG_ 2566875678 BPlus5AFuse2St "B+5AFuse#2Status";
CM_ SG_ 2566875678 BPlus5AFuse1St "B+5AFuse#1Status";
CM_ SG_ 2566875678 IPSTotalCur "IPSTotalCurrent";
CM_ SG_ 2566875678 MINIFuse2Cur "MINIFuse#2Current";
CM_ SG_ 2566875678 MINIFuse1Cur "MINIFuse#1Current";
CM_ SG_ 2566875678 MicroFuse5Cur "MicroFuse#5Current";
CM_ SG_ 2566875678 MicroFuse4Cur "MicroFuse#4Current";
CM_ SG_ 2566875678 MicroFuse3Cur "MicroFuse#3Current";
CM_ SG_ 2566875678 MicroFuse2Cur "MicroFuse#2Current";
CM_ SG_ 2566875678 MicroFuse1Cur "MicroFuse#1Current";
CM_ SG_ 2566875678 KeyOnPwrCur "KEYONPowerCurrent";
CM_ SG_ 2566875678 BPlusPwrCur "B+PowerCurrent";
CM_ BO_ 2566875815 "ACU Feedback6";
CM_ SG_ 2566875815 MiniRly30AFuse2St "MiniRelay30AFuse#2Status";
CM_ SG_ 2566875815 MiniRly30AFuse1St "MiniRelay30AFuse#1Status";
CM_ SG_ 2566875815 MicroRly20AFuse5St "MicroRelay20AFuse#5Status";
CM_ SG_ 2566875815 MicroRly20AFuse4St "MicroRelay20AFuse#4Status";
CM_ SG_ 2566875815 MicroRly20AFuse3St "MicroRelay20AFuse#3Status";
CM_ SG_ 2566875815 MicroRly20AFuse2St "MicroRelay20AFuse#2Status";
CM_ SG_ 2566875815 MicroRly20AFuse1St "MicroRelay20AFuse#1Status";
CM_ SG_ 2566875815 KeyOn30AFuse5St "KeyOn30AFuse#5Status";
CM_ SG_ 2566875815 KeyOn30AFuse4St "KeyOn30AFuse#4Status";
CM_ SG_ 2566875815 KeyOn30AFuse3St "KeyOn30AFuse#3Status";
CM_ SG_ 2566875815 KeyOn30AFuse2St "KeyOn30AFuse#2Status";
CM_ SG_ 2566875815 KeyOn30AFuse1St "KeyOn30AFuse#1Status";
CM_ SG_ 2566875815 KeyOn20AFuse10St "KeyOn20AFuse#10Status";
CM_ SG_ 2566875815 KeyOn20AFuse9St "KeyOn20AFuse#9Status";
CM_ SG_ 2566875815 KeyOn20AFuse8St "KeyOn20AFuse#8Status";
CM_ SG_ 2566875815 KeyOn20AFuse7St "KeyOn20AFuse#7Status";
CM_ SG_ 2566875815 KeyOn20AFuse6St "KeyOn20AFuse#6Status";
CM_ SG_ 2566875815 KeyOn20AFuse5St "KeyOn20AFuse#5Status";
CM_ SG_ 2566875815 KeyOn20AFuse4St "KeyOn20AFuse#4Status";
CM_ SG_ 2566875815 KeyOn20AFuse3St "KeyOn20AFuse#3Status";
CM_ SG_ 2566875815 KeyOn20AFuse2St "KeyOn20AFuse#2Status";
CM_ SG_ 2566875815 KeyOn20AFuse1St "KeyOn20AFuse#1Status";
CM_ SG_ 2566875815 KeyOn10AFuse5St "KeyOn10AFuse#5Status";
CM_ SG_ 2566875815 KeyOn10AFuse4St "KeyOn10AFuse#4Status";
CM_ SG_ 2566875815 KeyOn10AFuse3St "KeyOn10AFuse#3Status";
CM_ SG_ 2566875815 KeyOn10AFuse2St "KeyOn10AFuse#2Status";
CM_ SG_ 2566875815 KeyOn10AFuse1St "KeyOn10AFuse#1Status";
CM_ SG_ 2566875815 KeyOn5AFuse15St "KeyOn5AFuse#15Status";
CM_ SG_ 2566875815 KeyOn5AFuse14St "KeyOn5AFuse#14Status";
CM_ SG_ 2566875815 KeyOn5AFuse13St "KeyOn5AFuse#13Status";
CM_ SG_ 2566875815 KeyOn5AFuse12St "KeyOn5AFuse#12Status";
CM_ SG_ 2566875815 KeyOn5AFuse11St "KeyOn5AFuse#11Status";
CM_ SG_ 2566875815 KeyOn5AFuse10St "KeyOn5AFuse#10Status";
CM_ SG_ 2566875815 KeyOn5AFuse9St "KeyOn5AFuse#9Status";
CM_ SG_ 2566875815 KeyOn5AFuse8St "KeyOn5AFuse#8Status";
CM_ SG_ 2566875815 KeyOn5AFuse7St "KeyOn5AFuse#7Status";
CM_ SG_ 2566875815 KeyOn5AFuse6St "KeyOn5AFuse#6Status";
CM_ SG_ 2566875815 KeyOn5AFuse5St "KeyOn5AFuse#5Status";
CM_ SG_ 2566875815 KeyOn5AFuse4St "KeyOn5AFuse#4Status";
CM_ SG_ 2566875815 KeyOn5AFuse3St "KeyOn5AFuse#3Status";
CM_ SG_ 2566875815 KeyOn5AFuse2St "KeyOn5AFuse#2Status";
CM_ SG_ 2566875815 KeyOn5AFuse1St "KeyOn5AFuse#1Status";
CM_ SG_ 2566875815 BPlus30AFuse5St "B+30AFuse#5Status";
CM_ SG_ 2566875815 BPlus30AFuse4St "B+30AFuse#4Status";
CM_ SG_ 2566875815 BPlus30AFuse3St "B+30AFuse#3Status";
CM_ SG_ 2566875815 BPlus30AFuse2St "B+30AFuse#2Status";
CM_ SG_ 2566875815 BPlus30AFuse1St "B+30AFuse#1Status";
CM_ SG_ 2566875815 BPlus20AFuse5St "B+20AFuse#5Status";
CM_ SG_ 2566875815 BPlus20AFuse4St "B+20AFuse#4Status";
CM_ SG_ 2566875815 BPlus20AFuse3St "B+20AFuse#3Status";
CM_ SG_ 2566875815 BPlus20AFuse2St "B+20AFuse#2Status";
CM_ SG_ 2566875815 BPlus20AFuse1St "B+20AFuse#1Status";
CM_ SG_ 2566875815 BPlus5AFuse10St "B+5AFuse#10Status";
CM_ SG_ 2566875815 BPlus5AFuse9St "B+5AFuse#9Status";
CM_ SG_ 2566875815 BPlus5AFuse8St "B+5AFuse#8Status";
CM_ SG_ 2566875815 BPlus5AFuse7St "B+5AFuse#7Status";
CM_ SG_ 2566875815 BPlus5AFuse6St "B+5AFuse#6Status";
CM_ SG_ 2566875815 BPlus5AFuse5St "B+5AFuse#5Status";
CM_ SG_ 2566875815 BPlus5AFuse4St "B+5AFuse#4Status";
CM_ SG_ 2566875815 BPlus5AFuse3St "B+5AFuse#3Status";
CM_ SG_ 2566875815 BPlus5AFuse2St "B+5AFuse#2Status";
CM_ SG_ 2566875815 BPlus5AFuse1St "B+5AFuse#1Status";
CM_ SG_ 2566875815 IPSTotalCur "IPSTotalCurrent";
CM_ SG_ 2566875815 MINIFuse2Cur "MINIFuse#2Current";
CM_ SG_ 2566875815 MINIFuse1Cur "MINIFuse#1Current";
CM_ SG_ 2566875815 MicroFuse5Cur "MicroFuse#5Current";
CM_ SG_ 2566875815 MicroFuse4Cur "MicroFuse#4Current";
CM_ SG_ 2566875815 MicroFuse3Cur "MicroFuse#3Current";
CM_ SG_ 2566875815 MicroFuse2Cur "MicroFuse#2Current";
CM_ SG_ 2566875815 MicroFuse1Cur "MicroFuse#1Current";
CM_ SG_ 2566875815 KeyOnPwrCur "KEYONPowerCurrent";
CM_ SG_ 2566875815 BPlusPwrCur "B+PowerCurrent";
CM_ BO_ 2566875929 "Aircon Response Message";
CM_ SG_ 2566875929 AcpSsPrs "ACPsensorPressure";
CM_ SG_ 2566875929 CurAmbTmpCelsRealTm "CurrentAmbientTemperature(Celsius),RealTime";
CM_ SG_ 2566875929 TmpSt "TemperatureState";
CM_ SG_ 2566875929 CurBlowerSpd "CurrentBlowerSpeed";
CM_ SG_ 2566875929 CurAmbTmpCelsFilt "CurrentAmbientTemperature(Celsius),Filtered";
CM_ SG_ 2566875929 VhcStSybACOffInd "VehicleStateSymbol;A/COffIndicator";
CM_ SG_ 2566875929 CurTmpSet "CurrentTemperatureSetting(Celsius)";
CM_ SG_ 2566875929 CpsSt "CompressorState";
CM_ SG_ 2566875929 TmpSetValBelowSt "TemperatureSettingvalueBelowState";
CM_ SG_ 2566875929 TmpSetValOverSt "TemperatureSettingvalueOverState";
CM_ SG_ 2566875929 HvacPwrSt "HVACPowerState";
CM_ SG_ 2566875929 WindDirDefIndSt "WindDirectionDEFIndicatorstate";
CM_ SG_ 2566875929 WindDirFloorIndSt "WindDirectionFloorIndicatorstate";
CM_ SG_ 2566875929 WindDirRrIndSt "WindDirectionRearIndicatorstate";
CM_ SG_ 2566875929 WindDirFrIndSt "WindDirectionFrontIndicatorstate";
CM_ SG_ 2566875929 DefMdSt "DEFModeState";
CM_ SG_ 2566875929 OutInMdSel "Outtake/IntakeModeselect";
CM_ SG_ 2566875929 AcMdSt "A/CModeState";
CM_ SG_ 2566875929 MnAutoMdSt "Manual/AutoModeState";
CM_ BO_ 2566876320 "Doosan CAN Audio Information";
CM_ BO_ 2566876576 "Audio Frequency to GP";
CM_ BO_ 2566876832 "Audio Preset Frequency to GP";
CM_ BO_ 2566876961 "ACU Control2";
CM_ SG_ 2566876961 LowOutReq8 "LowOutputrequest#8";
CM_ SG_ 2566876961 LowOutReq7 "LowOutputrequest#7";
CM_ SG_ 2566876961 LowOutReq6 "LowOutputrequest#6";
CM_ SG_ 2566876961 LowOutReq5 "LowOutputrequest#5";
CM_ SG_ 2566876961 LowOutReq4 "LowOutputrequest#4";
CM_ SG_ 2566876961 LowOutReq3 "LowOutputrequest#3";
CM_ SG_ 2566876961 LowOutReq2 "LowOutputrequest#2";
CM_ SG_ 2566876961 LowOutReq1 "LowOutputrequest#1";
CM_ SG_ 2566876961 OutReq15 "Outputrequest#15";
CM_ SG_ 2566876961 OutReq14 "Outputrequest#14";
CM_ SG_ 2566876961 OutReq13 "Outputrequest#13";
CM_ SG_ 2566876961 OutReq12 "Outputrequest#12";
CM_ SG_ 2566876961 OutReq11 "Outputrequest#11";
CM_ SG_ 2566876961 OutReq10 "Outputrequest#10";
CM_ SG_ 2566876961 OutReq9 "Outputrequest#9";
CM_ SG_ 2566876961 OutReq8 "Outputrequest#8";
CM_ SG_ 2566876961 OutReq7 "Outputrequest#7";
CM_ SG_ 2566876961 OutReq6 "Outputrequest#6";
CM_ SG_ 2566876961 OutReq5 "Outputrequest#5";
CM_ SG_ 2566876961 OutReq4 "Outputrequest#4";
CM_ SG_ 2566876961 OutReq3 "Outputrequest#3";
CM_ SG_ 2566876961 OutReq2 "Outputrequest#2";
CM_ SG_ 2566876961 OutReq1 "Outputrequest#1";
CM_ BO_ 2566877258 "Terminal Version Information";
CM_ BO_ 2566877514 "Vehicle and Terminal Information";
CM_ BO_ 2566877770 "GPS Information";
CM_ SG_ 2566877770 Offset "LocalTimeOffset";
CM_ SG_ 2566877770 St "GPSState";
CM_ SG_ 2566877770 GpsSatNo "NumberofSatellites";
CM_ SG_ 2566877770 Spd "Speed";
CM_ SG_ 2566877770 Z "Altitude";
CM_ SG_ 2566877770 Y "Longitude";
CM_ SG_ 2566877770 X "Latitude";
CM_ BO_ 2566878026 "Network Information: Cell";
CM_ BO_ 2566878282 "Network Information: Satellite";
CM_ BO_ 2566878794 "Telematics Security";
CM_ SG_ 2566878794 WifiAntSt "WiFiAntennaStatus";
CM_ SG_ 2566878794 SatAntSt "SatelliteAntennaStatus";
CM_ SG_ 2566878794 CellAntSt "GSMAntennaStatus";
CM_ SG_ 2566878794 GpsAntSt "GPSAntennaStatus";
CM_ SG_ 2566878794 ScrtyCmd "SecurityCommand";
CM_ BO_ 2566879050 "GPS Information #2 (periodic broadcasting, Terminal -> other controller)";
CM_ BO_ 2566879272 "TMS Temporary Unlock Password Information";
CM_ SG_ 2566879272 Sha1Hash "SHA1Hash";
CM_ BO_ 2566879306 "Temp Unlock";
CM_ SG_ 2566879306 Sha1Hash "SHA1Hash";
CM_ BO_ 2566879562 "Lock/Unlock Request from Tester.";
CM_ SG_ 2566879562 Cd "Code";
CM_ BO_ 2566879818 "Digital Key Log In";
CM_ SG_ 2566879818 Dkey "DigitalKeyLoggedIn";
CM_ SG_ 2566879818 KeyType "KeyType";
CM_ SG_ 2566879818 LogIn "LogIn";
CM_ BO_ 2566880074 "Digital Key List Detected";
CM_ SG_ 2566880074 DkeyList "DigitalKeyList";
CM_ SG_ 2566880074 Cnt "DigitalKeyCount";
CM_ BO_ 2566880330 "Subscription Status";
CM_ SG_ 2566880330 DigitalKey "DigitalKeySelected";
CM_ SG_ 2566880330 SelType "SelectType";
CM_ BO_ 2566880586 "Ack/Nack or Status";
CM_ BO_ 2566880842 "P.Unlock Seed EPOS->GP/DMS/TGU";
CM_ SG_ 2566880842 TmsPmntUnlockCd "TMSPermanentUnlockCode";
CM_ BO_ 2566881064 "Security Status Information";
CM_ SG_ 2566881064 TmsStInfo2 "TMSStatusInformation2";
CM_ SG_ 2566881064 TmsStInfo1 "TMSStatusInformation1";
CM_ SG_ 2566881064 TmsPmntPw "TMSPermanentPassword";
CM_ BO_ 2566881098 "Security Status Information";
CM_ SG_ 2566881098 TmsStInfo2 "TMSStatusInformation2";
CM_ SG_ 2566881098 TmsStInfo1 "TMSStatusInformation1";
CM_ SG_ 2566881098 TmsPmntPw "TMSPermanentPassword";
CM_ BO_ 2566883328 "Transmission of Proprietary SCR2 frame over CAN";
CM_ SG_ 2566883328 EmsObdIndFail "EmissionOBDInducementfailurereason";
CM_ SG_ 2566883328 UreaLvAlm "Urealevelalarm";
CM_ SG_ 2566883328 Scr2RegInfo "SCR2RegulationInformation";
CM_ SG_ 2566883328 EmsObdIndSt "Emission-OBDinducementstate";
CM_ SG_ 2566883328 UreaLvBzSt "Urealevelbuzzerstatus";
CM_ BO_ 2566883873 "ADT Analog Sensor Information";
CM_ SG_ 2566883873 AltVlt "AlternaterVoltage";
CM_ SG_ 2566883873 Rr2BrkSsPrs "Rear2BrakePress.SensorPress.";
CM_ SG_ 2566883873 BoomCylRodSsPrs "BoomCyclinderPress.(Rod)SensorPress.";
CM_ SG_ 2566883873 BoomCylHeadSsPrs "BoomCyclinderPress.(Head)SensorPress.";
CM_ SG_ 2566883873 CtrPinAngSs1Vlt "CenterPinAngleSensor1Voltage";
CM_ SG_ 2566883873 AccPdlSs2Vlt "AccelPedalSensor2Voltage";
CM_ SG_ 2566883873 DumpBedAngSs2Vlt "DumpBedAngleSensor2Voltage";
CM_ SG_ 2566883873 DumpBedAngSs1Vlt "DumpBedAngleSensor1Voltage";
CM_ SG_ 2566883873 BrkInchPdlSs1Vlt "Brake/InchPedalSensor1Voltage";
CM_ SG_ 2566883873 TipJoySs1Vlt "TipJoystickSensor1Voltage";
CM_ SG_ 2566883873 RhCylSsPrs "RHCyclinderPress.SensorPress.";
CM_ SG_ 2566883873 EmgStrSsPrs "EmergencySteer.Press.SensorPress.";
CM_ SG_ 2566883873 AxleOilSsTmp "AxleOilTemp.SensorTemp.";
CM_ SG_ 2566883873 FuelSsLv "FuelSensorLevel";
CM_ SG_ 2566883873 Rr1BrkSsPrs "Rear1BrakePress.SensorPress.";
CM_ SG_ 2566883873 FrBrkSsPrs "FrontBrakePress.SensorPress.";
CM_ SG_ 2566883873 AccPdlSs1Vlt "AccelPedalSensor1Voltage";
CM_ SG_ 2566883873 CtrPinAngSs2Vlt "CenterPinAngleSensor2Voltage";
CM_ SG_ 2566883873 TmsSecVlt "TMS3.5VLineVoltage";
CM_ SG_ 2566883873 LhCylSsPrs "LHCyclinderPress.SensorPress.";
CM_ SG_ 2566883873 Acc3SsPrs "ACC3Press.SensorPress.";
CM_ SG_ 2566883873 BrkInchPdlSs2Vlt "Brake/InchPedalSensor2Voltage";
CM_ SG_ 2566883873 CacFanSsPrs "CACFanPressSensorPress.";
CM_ SG_ 2566883873 Acc2SsPrs "ACC2Press.SensorPress.";
CM_ SG_ 2566883873 TipJoySs2Vlt "TipJoystickSensor2Voltage";
CM_ SG_ 2566883873 TocFanSsPrs "TOCFanPressSensorPress.";
CM_ SG_ 2566883873 Acc1SsPrs "ACC1Press.SensorPress.";
CM_ SG_ 2566883873 PrkBrkSsPrs "ParkingBrakeSensorPress.";
CM_ SG_ 2566883873 MainSsPrs "MainPress.SensorPress.";
CM_ SG_ 2566883873 WifSsVlt "WIFSensorVoltage";
CM_ SG_ 2566883873 HydOilSsTmp "HydraulicOilTemp.SensorTemp.";
CM_ BO_ 2566884129 "ADT Analog Actuator Information";
CM_ SG_ 2566884129 FanDrvTocEvc "FanDrive(TOC)EPPRV/VCurrent";
CM_ SG_ 2566884129 eFan2DutyRatio "E-Fan2DutyRatio";
CM_ SG_ 2566884129 eFan3DutyRatio "E-Fan3DutyRatio";
CM_ SG_ 2566884129 eBrkEvc "E-BrakeEPPRV/VCurrent";
CM_ SG_ 2566884129 eFan1DutyRatio "E-Fan1DutyRatio";
CM_ SG_ 2566884129 FanDrvRadCacEvc "FanDrive(RAD/CAC)EPPRV/VCurrent";
CM_ SG_ 2566884129 BodyDnEvc "BodyDownEPPRV/VCurrent";
CM_ SG_ 2566884129 BodyUpEvc "BodyUpEPPRV/VCurrent";
CM_ BO_ 2566884385 "ADT Digital Sensor Information";
CM_ SG_ 2566884385 StartCrkSw "StarterCrankingSwitch";
CM_ SG_ 2566884385 GrSelSw "GearSelectorSwitch";
CM_ SG_ 2566884385 GrSelNtrlSw "GearSelectorNeutrualSwitch";
CM_ SG_ 2566884385 PrkSw "ParkingSwitch";
CM_ SG_ 2566884385 GrSelRvsSw "GearSelectorReverseSwitch";
CM_ SG_ 2566884385 GrSelShftDnSw "GearSelectorShiftDownSwitch";
CM_ SG_ 2566884385 GrSelShftUpSw "GearSelectorShiftUpSwitch";
CM_ SG_ 2566884385 GrSelFwdSw "GearSelectorForwardSwitch";
CM_ SG_ 2566884385 DustIndSw "DustIndicatorSwitch";
CM_ SG_ 2566884385 StartAccSw "StarterACCSwitch";
CM_ SG_ 2566884385 AtsForceRgnSw "ATSForcedRegenerationSwitch";
CM_ SG_ 2566884385 AtsRgnIhbsw "ATSRegenerationInhibitSwitch";
CM_ SG_ 2566884385 eFan3ErrSt "E-Fan3ErrorState";
CM_ SG_ 2566884385 KeyBrSw "Key(Br)Switch";
CM_ SG_ 2566884385 TipJoySw "TipJoystickSwitch";
CM_ SG_ 2566884385 AgsSw "AGSSwitch";
CM_ SG_ 2566884385 eFan2ErrSt "E-Fan2ErrorState";
CM_ SG_ 2566884385 eFan1ErrSt "E-Fan1ErrorState";
CM_ SG_ 2566884385 SeatBeltSt "SeatBeltState";
CM_ SG_ 2566884385 FrWiperStpSw "FrontWiperStopSwitch";
CM_ BO_ 2566884641 "ADT Digital Actuator Information";
CM_ SG_ 2566884641 SusRhDn "Sus.RHDown";
CM_ SG_ 2566884641 TocRvs "TOCReverse";
CM_ SG_ 2566884641 TurnSigRhRly "TurnSignalRHRelay";
CM_ SG_ 2566884641 TurnSigLhRly "TurnSignalLHRelay";
CM_ SG_ 2566884641 SusRhUp "Sus.RHUp";
CM_ SG_ 2566884641 EgRunOutSig "EngineRunningOutputSignal";
CM_ SG_ 2566884641 SusLhDn "Sus.LHDown";
CM_ SG_ 2566884641 UreaSuperChgWrnSig "UreaSuperchargingWarningSignal";
CM_ SG_ 2566884641 FanStpSv "FanStopS/V";
CM_ SG_ 2566884641 Dhl3Sig "DHL3Signal";
CM_ SG_ 2566884641 Dhl2Sig "DHL2Signal";
CM_ SG_ 2566884641 SusLhUp "Sus.LHUp";
CM_ SG_ 2566884641 PrkBrkRlsSv "ParkingBrakeReleaseS/V";
CM_ SG_ 2566884641 AxleOilCoolSv "AxleOilCoolerS/V";
CM_ SG_ 2566884641 TocUnloading "TOCUnloading";
CM_ SG_ 2566884641 AccRly "ACCRelay";
CM_ SG_ 2566884641 RrWinHtRly "RearWindowHeatingRelay";
CM_ SG_ 2566884641 LiftArmFlt "LiftArmFloat";
CM_ SG_ 2566884641 AutoShutOffRly "AutoShutOffRelay";
CM_ SG_ 2566884641 BrkChgSv "BrakeChargeS/V";
CM_ SG_ 2566884641 Dhl1Sig "DHL1Signal";
CM_ BO_ 2566884897 "Tire Information Group 1";
CM_ SG_ 2566884897 RrRhTirePrs "RearRightTirePressure";
CM_ SG_ 2566884897 RrLhTirePrs "RearLeftTirePressure";
CM_ SG_ 2566884897 CtrRhTirePrs "CenterRightTirePressure";
CM_ SG_ 2566884897 CtrLhTirePrs "CenterLeftTirePressure";
CM_ SG_ 2566884897 FronRhTirePrs "FrontRightTirePressure";
CM_ SG_ 2566884897 FrLhTirePrs "FrontLeftTirePressure";
CM_ BO_ 2566885153 "Tire Information Group 2";
CM_ SG_ 2566885153 RrRhTireTmp "RearRightTireTemperature";
CM_ SG_ 2566885153 RrLhTireTmp "RearLeftTireTemperature";
CM_ SG_ 2566885153 CtrRhTireTmp "CenterRightTireTemperature";
CM_ SG_ 2566885153 CtrLhTireTmp "CenterLeftTireTemperature";
CM_ SG_ 2566885153 FronRhTireTmp "FrontRightTireTemperature";
CM_ SG_ 2566885153 FrLhTireTmp "FrontLeftTireTemperature";
CM_ BO_ 2566885409 "QR Code Information";
CM_ SG_ 2566885409 PartNo "PartNumber";
CM_ SG_ 2566885409 SerialNo "SerialNumber";
CM_ SG_ 2566885409 MnftCode "ManufacturerCode";
CM_ SG_ 2566885409 ComCode "ComponentCode";
CM_ SG_ 2566885409 Year "Year";
CM_ SG_ 2566885409 Day "Day";
CM_ SG_ 2566885409 Month "Month";
CM_ SG_ 2566885409 VcuSwVer "VCUSWVersion";
CM_ BO_ 2566885665 "ECO Report Information";
CM_ SG_ 2566885665 TotAvgReliefOprPct "TotalAverageofReliefIdleOperationPercentage";
CM_ SG_ 2566885665 TotAvgLwIdleOprPct "TotalAverageofLowIdleOperationPercentage";
CM_ SG_ 2566885665 TotAvgHhIdleOprPct "TotalAverageofHighIdleOperationPercentage";
CM_ SG_ 2566885665 Day7ReliefOprPct "7stDayReliefOperationPercentage";
CM_ SG_ 2566885665 Day7LwIdleOprPct "7stDayLowIdleOperationPercentage";
CM_ SG_ 2566885665 Day7HhIdleOprPct "7stDayHighIdleOperationPercentage";
CM_ SG_ 2566885665 Day6ReliefOprPct "6stDayReliefOperationPercentage";
CM_ SG_ 2566885665 Day6LwIdleOprPct "6stDayLowIdleOperationPercentage";
CM_ SG_ 2566885665 Day6HhIdleOprPct "6stDayHighIdleOperationPercentage";
CM_ SG_ 2566885665 Day5ReliefOprPct "5stDayReliefOperationPercentage";
CM_ SG_ 2566885665 Day5LwIdleOprPct "5stDayLowIdleOperationPercentage";
CM_ SG_ 2566885665 Day5HhIdleOprPct "5stDayHighIdleOperationPercentage";
CM_ SG_ 2566885665 Day4ReliefOprPct "4stDayReliefOperationPercentage";
CM_ SG_ 2566885665 Day4LwIdleOprPct "4stDayLowIdleOperationPercentage";
CM_ SG_ 2566885665 Day4HhIdleOprPct "4stDayHighIdleOperationPercentage";
CM_ SG_ 2566885665 Day3ReliefOprPct "3stDayReliefOperationPercentage";
CM_ SG_ 2566885665 Day3LwIdleOprPct "3stDayLowIdleOperationPercentage";
CM_ SG_ 2566885665 Day3HhIdleOprPct "3stDayHighIdleOperationPercentage";
CM_ SG_ 2566885665 Day2ReliefOprPct "2stDayReliefOperationPercentage";
CM_ SG_ 2566885665 Day2LwIdleOprPct "2stDayLowIdleOperationPercentage";
CM_ SG_ 2566885665 Day2HhIdleOprPct "2stDayHighIdleOperationPercentage";
CM_ SG_ 2566885665 Day1ReliefOprPct "1stDayReliefOperationPercentage";
CM_ SG_ 2566885665 Day1LwIdleOprPct "1stDayLowIdleOperationPercentage";
CM_ SG_ 2566885665 Day1HhIdleOprPct "1stDayHighIdleOperationPercentage";
CM_ SG_ 2566885665 NowReliefOprLv "(??)ReliefOperationLevel";
CM_ SG_ 2566885665 NowLwIdleOprLv "(??)LowIdleOperationLevel";
CM_ SG_ 2566885665 NowHhIdleOprLv "(??)HighIdleOperationLevel";
CM_ SG_ 2566885665 NowReliefOprPct "(??)ReliefOperationPercentage";
CM_ SG_ 2566885665 NowLwIdleOprPct "(??)LowIdleOperationPercentage";
CM_ SG_ 2566885665 NowHhIdleOprPct "(??)HighIdleOperationPercentage";
CM_ BO_ 2566886586 "Radar Object Zone Index ";
CM_ BO_ 2566886587 "Radar Object Zone Index ";
CM_ BO_ 2566886588 "Radar Object Zone Index ";
CM_ BO_ 2566886842 "Radar Object Information ";
CM_ BO_ 2566886843 "Radar Object Information ";
CM_ BO_ 2566886844 "Radar Object Information ";
CM_ BO_ 2566886952 "AVM View Mode";
CM_ SG_ 2566886952 RrVwPriMd "RearViewPriorityMode";
CM_ SG_ 2566886952 VwMd "ViewMode";
CM_ BO_ 2566887223 "AVM Setting Information";
CM_ SG_ 2566887223 RrVwPriMd "RearViewPriorityMode";
CM_ SG_ 2566887223 AvmWrnGud "AVMWarningGuide";
CM_ SG_ 2566887223 AvmSt "AVMStatus";
CM_ SG_ 2566887223 AvmUltraBz "AVMUltraBuzzer";
CM_ SG_ 2566887223 AvmTonSize "AVMTonSize";
CM_ SG_ 2566887223 AvmDisplayMsg "AVMDisplayMessage";
CM_ SG_ 2566887223 AvmOutType "AVMOutputType";
CM_ SG_ 2566887223 AvmVw "AVMView";
CM_ SG_ 2566887223 AvmLanguagePack "AVMLanguagePack";
CM_ BO_ 2566887479 "AVM Ultral Sonic Sensor signal";
CM_ SG_ 2566887479 UltsSigL6 "UltraSonicSignalL6";
CM_ SG_ 2566887479 UltsSigR6 "UltraSonicSignalR6";
CM_ SG_ 2566887479 UltsSigL5 "UltraSonicSignalL5";
CM_ SG_ 2566887479 UltsSigR5 "UltraSonicSignalR5";
CM_ SG_ 2566887479 UltsSigL4 "UltraSonicSignalL4";
CM_ SG_ 2566887479 UltsSigR4 "UltraSonicSignalR4";
CM_ SG_ 2566887479 UltsSigL3 "UltraSonicSignalL3";
CM_ SG_ 2566887479 UltsSigR3 "UltraSonicSignalR3";
CM_ SG_ 2566887479 UltsSigL2 "UltraSonicSignalL2";
CM_ SG_ 2566887479 UltsSigR2 "UltraSonicSignalR2";
CM_ SG_ 2566887479 UltsSigL1 "UltraSonicSignalL1";
CM_ SG_ 2566887479 UltsSigR1 "UltraSonicSignalR1";
CM_ BO_ 2566887720 "AVM Cal Rx";
CM_ SG_ 2566887720 CamPrmtCorCompleteSt "CameraParameters??????";
CM_ SG_ 2566887720 CamPrmtVerMsb "CameraParametersVersion(MSB)";
CM_ SG_ 2566887720 CamPrmtVerLsb "CameraParametersVersion(LSB)";
CM_ SG_ 2566887720 Language "Language";
CM_ SG_ 2566887720 ToleranceCorMenuentryCmd "????????Command(ToleranceCorrectionMenuentry)";
CM_ SG_ 2566887720 WrnGudSetCmd "???????Command(WariningGuideSetting)";
CM_ SG_ 2566887720 UltsSs08Cmd "?????08Command(UltrasonicSensor)";
CM_ SG_ 2566887720 UltsSs07Cmd "?????07Command(UltrasonicSensor)";
CM_ SG_ 2566887720 UltsSs06Cmd "?????06Command(UltrasonicSensor)";
CM_ SG_ 2566887720 UltsSs05Cmd "?????05Command(UltrasonicSensor)";
CM_ SG_ 2566887720 UltsSs04Cmd "?????04Command(UltrasonicSensor)";
CM_ SG_ 2566887720 UltsSs03Cmd "?????03Command(UltrasonicSensor)";
CM_ SG_ 2566887720 UltsSs02Cmd "?????02Command(UltrasonicSensor)";
CM_ SG_ 2566887720 UltsSs01Cmd "?????01Command(UltrasonicSensor)";
CM_ SG_ 2566887720 UltsSs12Cmd "?????12Command(UltrasonicSensor)";
CM_ SG_ 2566887720 UltsSs11Cmd "?????11Command(UltrasonicSensor)";
CM_ SG_ 2566887720 UltsSs10Cmd "?????10Command(UltrasonicSensor)";
CM_ SG_ 2566887720 UltsSs09Cmd "?????09Command(UltrasonicSensor)";
CM_ SG_ 2566887720 SetApplicationCmd "????Command(SettingApplication)";
CM_ SG_ 2566887720 ToleranceCorCmd "????Command(ToleranceCorrection)";
CM_ SG_ 2566887720 FactoryReCmd "?????Command(FactoryReset)";
CM_ SG_ 2566887720 UltsSsOpt "?????Opt??(UltrasonicSensorOption)";
CM_ SG_ 2566887720 UltsBuzzerStopSig "?????Stop???(UltrasonicBuzzerStopSignal)";
CM_ SG_ 2566887720 BoomCamOpt "BoomCameraOption";
CM_ SG_ 2566887720 UltsBzOffSig "?????OFF???(UltrasonicBuzzerOFFSignal)";
CM_ SG_ 2566887720 UltsRecognitionDistanceSet "?????????(UltrasonicRecognitionDistanceSetting)";
CM_ SG_ 2566887720 VhcType2 "????02(VehicleType)";
CM_ SG_ 2566887720 VhcType1 "????01(VehicleType)";
CM_ SG_ 2566887720 TonsOftheTensDigit "10????(TonsOftheTensDigit)";
CM_ SG_ 2566887720 TonsOftheUnitsDigit "1????(TonsOftheUnitsDigit)";
CM_ SG_ 2566887720 FactoryType "????(FactoryType)";
CM_ SG_ 2566887720 VwMd "ViewMode";
CM_ BO_ 2566887991 "AVM Cal Tx";
CM_ SG_ 2566887991 CamPrmtCorCompleteSt "CameraParameters??????";
CM_ SG_ 2566887991 CamPrmtVerMsb "CameraParametersVersion(MSB)";
CM_ SG_ 2566887991 CamPrmtVerLsb "CameraParametersVersion(LSB)";
CM_ SG_ 2566887991 Language "Language";
CM_ SG_ 2566887991 ToleranceCorMenuentryCmd "????????Command(ToleranceCorrectionMenuentry)";
CM_ SG_ 2566887991 WrnGudSetCmd "???????Command(WariningGuideSetting)";
CM_ SG_ 2566887991 UltsSs08Cmd "?????08Command";
CM_ SG_ 2566887991 UltsSs07Cmd "?????07Command";
CM_ SG_ 2566887991 UltsSs06Cmd "?????06Command";
CM_ SG_ 2566887991 UltsSs05Cmd "?????05Command";
CM_ SG_ 2566887991 UltsSs04Cmd "?????04Command";
CM_ SG_ 2566887991 UltsSs03Cmd "?????03Command";
CM_ SG_ 2566887991 UltsSs02Cmd "?????02Command";
CM_ SG_ 2566887991 UltsSs01Cmd "?????01Command";
CM_ SG_ 2566887991 UltsSs12Cmd "?????12Command";
CM_ SG_ 2566887991 UltsSs11Cmd "?????11Command";
CM_ SG_ 2566887991 UltsSs10Cmd "?????10Command";
CM_ SG_ 2566887991 UltsSs09Cmd "?????09Command";
CM_ SG_ 2566887991 SetAppCmd "????Command(SettingApplication)";
CM_ SG_ 2566887991 ToleranceCorCmd "????Command(ToleranceCorrection)";
CM_ SG_ 2566887991 FactoryResetCmd "?????Command(FactoryReset)";
CM_ SG_ 2566887991 UltsSsOpt "?????????(UltrasonicSensorOption)";
CM_ SG_ 2566887991 UltsBzStopSig "?????Stop???(UltrasonicBuzzerStopSignal)";
CM_ SG_ 2566887991 BoomCamOpt "BoomCameraOption";
CM_ SG_ 2566887991 UltsBzOffSig "?????OFF???(UltrasonicBuzzerOFFSignal)";
CM_ SG_ 2566887991 UltsRecognitionDistanceSet "?????????(UltrasonicRecognitionDistanceSetting)";
CM_ SG_ 2566887991 VhcType2 "????02(VehicleType)";
CM_ SG_ 2566887991 VhcType1 "????01(VehicleType)";
CM_ SG_ 2566887991 TonsOftheTensDigit "10????(TonsOftheTensDigit)";
CM_ SG_ 2566887991 TonsOftheUnitsDigit "1????(TonsOftheUnitsDigit)";
CM_ SG_ 2566887991 FactoryType "????(FactoryType)";
CM_ SG_ 2566887991 VwMd "ViewMode";
CM_ BO_ 2566888503 "Camera Parameter";
CM_ SG_ 2566888503 AvmCamPrmt4 "AVMCameraParameters4";
CM_ SG_ 2566888503 AvmCamPrmt3 "AVMCameraParameters3";
CM_ SG_ 2566888503 AvmCamPrmt2 "AVMCameraParameters2";
CM_ SG_ 2566888503 AvmCamPrmt1 "AVMCameraParameters1";
CM_ BO_ 2566888759 "AVM Version";
CM_ SG_ 2566888759 AvmVerYear "AVMVersionYear";
CM_ SG_ 2566888759 AvmVerMonth "AVMVersionMonth";
CM_ SG_ 2566888759 AvmVerDate "AVMVersionDate";
CM_ SG_ 2566888759 AvmVer "AVMVersion";
CM_ BO_ 2566889388 "CHMSL Information";
CM_ BO_ 2566889512 "GP Command";
CM_ SG_ 2566889512 EvMdCmd "EVModeCommand";
CM_ SG_ 2566889512 ObjectSsChmsl "ObjectSensing;CHMSL";
CM_ SG_ 2566889512 KeylessCrankEnbSt "KeylessCrankEnableState";
CM_ SG_ 2566889512 DaacmdSt "DAACModeState";
CM_ SG_ 2566889512 QuickCoolMdSt "QuickCoolingModeState";
CM_ SG_ 2566889512 DzAstMdSt "DozingAssistModeState";
CM_ SG_ 2566889512 KeyPadPri "KeyPadPriority";
CM_ SG_ 2566889512 RpmCmdbyJD "RpmCommandbyJogDial";
CM_ SG_ 2566889512 TractionMdSt "TractionModeState";
CM_ SG_ 2566889512 ExternalSoundCmd "????CMD(ExternalSound)";
CM_ SG_ 2566889512 EgLckSt "EngineLockState";
CM_ SG_ 2566889512 JduseStforRpm "JogDialUseStateforRpm";
CM_ SG_ 2566889512 AutoIdleMdSt "AutoIdleModeState";
CM_ SG_ 2566889512 WrkMdSt "WorkModeState";
CM_ SG_ 2566889512 PwrMdSt "PowerModeState";
CM_ BO_ 2566889768 "GP Time/Date";
CM_ SG_ 2566889768 LocalHrOfs "Localhouroffset";
CM_ SG_ 2566889768 LocalMinOfs "Localminuteoffset";
CM_ SG_ 2566889768 Year "Year";
CM_ SG_ 2566889768 Day "Day";
CM_ SG_ 2566889768 Mon "Month";
CM_ SG_ 2566889768 Hrs "Hours";
CM_ SG_ 2566889768 Mins "Minutes";
CM_ SG_ 2566889768 Secs "Seconds";
CM_ BO_ 2566890024 "Software Version";
CM_ SG_ 2566890024 AvmSwVer "AVMSWVersion";
CM_ SG_ 2566890024 AvmSwVerYear "AVMSWVersion;Year";
CM_ SG_ 2566890024 AvmSwVerDay "AVMSWVersion;Day";
CM_ SG_ 2566890024 AvmSwVerMon "AVMSWVersion;Month";
CM_ SG_ 2566890024 GpOsSwVer "GPOSSWVersion";
CM_ SG_ 2566890024 GpOsSwVerYear "GPOSSWVersion;Year";
CM_ SG_ 2566890024 GpOsSwVerDay "GPOSSWVersion;Day";
CM_ SG_ 2566890024 GpOsSwVerMon "GPOSSWVersion;Month";
CM_ SG_ 2566890024 GpAppSwVer "GPAPPSWVersion";
CM_ SG_ 2566890024 GpAppSwVerYear "GPAPPSWVersion;Year";
CM_ SG_ 2566890024 GpAppSwVerDay "GPAPPSWVersion;Day";
CM_ SG_ 2566890024 GpAppSwVerMon "GPAPPSWVersion;Month";
CM_ BO_ 2566890280 "Attachment  Flow Command";
CM_ SG_ 2566890280 AttSetFlowVal "AttachmentSettingFlowValue";
CM_ SG_ 2566890280 AttSetSaveFlag "AttachmentSettingSaveFlag";
CM_ SG_ 2566890280 AttNo "AttachmentNumber";
CM_ SG_ 2566890280 AttType "AttachmentType";
CM_ BO_ 2566890536 "2D MG Buzzer Command";
CM_ SG_ 2566890536 MgSoundGudStep "MGSoundGuidanceStep";
CM_ SG_ 2566890536 AlmSt "AlarmState";
CM_ BO_ 2566890561 "2D MG Buzzer Command";
CM_ SG_ 2566890561 MgSoundGudStep "MGSoundGuidanceStep";
CM_ SG_ 2566890561 AlmSt "AlarmState";
CM_ BO_ 2566890792 "GP Command with check sum";
CM_ SG_ 2566890792 MsgChecksum "MessageChecksum";
CM_ SG_ 2566890792 MsgCounter "MessageCounter";
CM_ SG_ 2566890792 OptSetJoyPatternChange "Opt??;JoystickPatternChange";
CM_ BO_ 2566891041 "ZFIMP";
CM_ BO_ 2566891688 "Converting Angle Value";
CM_ BO_ 2566892072 "Doosan CAN Audio Panel";
CM_ SG_ 2566892072 ReqCallIndex "RequestCallIndex";
CM_ SG_ 2566892072 PairingRequest "PairingRequest";
CM_ SG_ 2566892072 HangUpBtn "HangUpButton";
CM_ SG_ 2566892072 DabSel "DABSelect";
CM_ SG_ 2566892072 MdSel "ModeSelect";
CM_ SG_ 2566892072 AudioVolDownSel "AudioVolumeDownSelect";
CM_ SG_ 2566892072 AudioVolUpSel "AudioVolumeUpSelect";
CM_ SG_ 2566892072 BandSel "BandSelect";
CM_ SG_ 2566892072 TalkBtn "TalkButton";
CM_ SG_ 2566892072 AudioTuneDownSel "AudioTuneDownSelect";
CM_ SG_ 2566892072 AudioCallListPopupSt "AudioCallListPopupState";
CM_ SG_ 2566892072 AudioMenuSel "AudioMenuSelect";
CM_ SG_ 2566892072 AudioPowerSel "AudioPowerSelect";
CM_ SG_ 2566892072 AudioP5Sel "AudioP5Select";
CM_ SG_ 2566892072 AudioP6Sel "AudioP6Select";
CM_ SG_ 2566892072 AudioTuneSel "AudioTuneSelect";
CM_ SG_ 2566892072 AudioTuneUpSel "AudioTuneUpSelect";
CM_ SG_ 2566892072 AudioP1Sel "AudioP1Select";
CM_ SG_ 2566892072 AudioP2Sel "AudioP2Select";
CM_ SG_ 2566892072 AudioP3Sel "AudioP3Select";
CM_ SG_ 2566892072 AudioP4Sel "AudioP4Select";
CM_ SG_ 2566892072 AudioAmSel "AudioAMSelect";
CM_ SG_ 2566892072 AudioFmSel "AudioFMSelect";
CM_ SG_ 2566892072 AudioUsbSel "AudioUSBSelect";
CM_ SG_ 2566892072 AudioAuxSel "AudioAUXSelect";
CM_ BO_ 2566892448 "Audio Phone Book List to GP";
CM_ BO_ 2566892704 "Audio Large Index Text";
CM_ BO_ 2566892960 "Audio DLS Text";
CM_ BO_ 2566893216 "Audio Incoming Call Text to GP";
CM_ BO_ 2566893472 "Audio Text to GP";
BA_DEF_ BO_  "VFrameFormat" ENUM  "StandardCAN","ExtendedCAN","reserved","J1939PG";
BA_DEF_ BO_  "Channel" STRING ;
BA_DEF_ BO_  "VssMsg" STRING ;
BA_DEF_ SG_  "VssSig" STRING ;
BA_DEF_ BO_  "GenMsgCycleTime" INT 0 65535;
BA_DEF_DEF_  "VFrameFormat" "J1939PG";
BA_DEF_DEF_  "Channel" "";
BA_DEF_DEF_  "VssMsg" "";
BA_DEF_DEF_  "VssSig" "";
BA_DEF_DEF_  "GenMsgCycleTime" 0;
BA_ "GenMsgCycleTime" BO_ 2566866977 500;
BA_ "VssMsg" BO_ 2566866977 "Mch.MCU.GPG2";
BA_ "Channel" BO_ 2566866977 "can1";
BA_ "GenMsgCycleTime" BO_ 2566867233 500;
BA_ "VssMsg" BO_ 2566867233 "Mch.MCU.GPG3";
BA_ "Channel" BO_ 2566867233 "can1";
BA_ "GenMsgCycleTime" BO_ 2566867489 200;
BA_ "VssMsg" BO_ 2566867489 "Mch.MCU.SIG4";
BA_ "Channel" BO_ 2566867489 "can1";
BA_ "GenMsgCycleTime" BO_ 2566867745 200;
BA_ "VssMsg" BO_ 2566867745 "Mch.MCU.GPG4";
BA_ "Channel" BO_ 2566867745 "can1";
BA_ "VssMsg" BO_ 2566868257 "Mch.MCU.METPSC";
BA_ "Channel" BO_ 2566868257 "can1";
BA_ "GenMsgCycleTime" BO_ 2566868921 10;
BA_ "VssMsg" BO_ 2566868921 "Mch.EGDL.EDO";
BA_ "Channel" BO_ 2566868921 "can1";
BA_ "GenMsgCycleTime" BO_ 2566869025 100;
BA_ "VssMsg" BO_ 2566869025 "Mch.MCU.JSO";
BA_ "Channel" BO_ 2566869025 "can1";
BA_ "GenMsgCycleTime" BO_ 2566869158 100;
BA_ "VssMsg" BO_ 2566869158 "Mch.JS.JSO";
BA_ "Channel" BO_ 2566869158 "can1";
BA_ "VssMsg" BO_ 2365542696 "Mch.GP.JCM";
BA_ "Channel" BO_ 2365542696 "can1";
BA_ "GenMsgCycleTime" BO_ 2365542917 10;
BA_ "VssMsg" BO_ 2365542917 "Mch.FNR.ZFTC1";
BA_ "Channel" BO_ 2365542917 "can1";
BA_ "GenMsgCycleTime" BO_ 2365543201 100;
BA_ "VssMsg" BO_ 2365543201 "Mch.MCU.KEYPADBI";
BA_ "Channel" BO_ 2365543201 "can1";
BA_ "GenMsgCycleTime" BO_ 2365543504 100;
BA_ "VssMsg" BO_ 2365543504 "Mch.KPD1.KEYPADS";
BA_ "Channel" BO_ 2365543504 "can1";
BA_ "GenMsgCycleTime" BO_ 2365543713 100;
BA_ "VssMsg" BO_ 2365543713 "Mch.MCU.KEYPADI1";
BA_ "Channel" BO_ 2365543713 "can1";
BA_ "GenMsgCycleTime" BO_ 2365543969 100;
BA_ "VssMsg" BO_ 2365543969 "Mch.MCU.KEYPADMI1";
BA_ "Channel" BO_ 2365543969 "can1";
BA_ "GenMsgCycleTime" BO_ 2365544225 100;
BA_ "VssMsg" BO_ 2365544225 "Mch.MCU.KEYPADMI2";
BA_ "Channel" BO_ 2365544225 "can1";
BA_ "GenMsgCycleTime" BO_ 2365544481 100;
BA_ "VssMsg" BO_ 2365544481 "Mch.MCU.KEYPADI2";
BA_ "Channel" BO_ 2365544481 "can1";
BA_ "GenMsgCycleTime" BO_ 2365544737 100;
BA_ "VssMsg" BO_ 2365544737 "Mch.MCU.KEYPADI3";
BA_ "Channel" BO_ 2365544737 "can1";
BA_ "VssMsg" BO_ 2566871629 "Mch.CBSW.HCMD";
BA_ "Channel" BO_ 2566871629 "can1";
BA_ "GenMsgCycleTime" BO_ 2566872001 20;
BA_ "VssMsg" BO_ 2566872001 "Mch.IMU1.ASI";
BA_ "Channel" BO_ 2566872001 "can1";
BA_ "GenMsgCycleTime" BO_ 2566872002 20;
BA_ "VssMsg" BO_ 2566872002 "Mch.IMU2.ASI";
BA_ "Channel" BO_ 2566872002 "can1";
BA_ "GenMsgCycleTime" BO_ 2566872003 20;
BA_ "VssMsg" BO_ 2566872003 "Mch.IMU3.ASI";
BA_ "Channel" BO_ 2566872003 "can1";
BA_ "GenMsgCycleTime" BO_ 2566872004 20;
BA_ "VssMsg" BO_ 2566872004 "Mch.IMU4.ASI";
BA_ "Channel" BO_ 2566872004 "can1";
BA_ "GenMsgCycleTime" BO_ 2566872005 20;
BA_ "VssMsg" BO_ 2566872005 "Mch.IMU5.ASI";
BA_ "Channel" BO_ 2566872005 "can1";
BA_ "GenMsgCycleTime" BO_ 2365545552 100;
BA_ "VssMsg" BO_ 2365545552 "Mch.KPD1.KEYPADS2";
BA_ "Channel" BO_ 2365545552 "can1";
BA_ "GenMsgCycleTime" BO_ 2365545761 100;
BA_ "VssMsg" BO_ 2365545761 "Mch.MCU.KEYPADI4";
BA_ "Channel" BO_ 2365545761 "can1";
BA_ "GenMsgCycleTime" BO_ 2566873377 100;
BA_ "VssMsg" BO_ 2566873377 "Mch.MCU.ACUCTR";
BA_ "Channel" BO_ 2566873377 "can1";
BA_ "GenMsgCycleTime" BO_ 2566873630 100;
BA_ "VssMsg" BO_ 2566873630 "Mch.ACU.ACUFB1";
BA_ "Channel" BO_ 2566873630 "can1";
BA_ "GenMsgCycleTime" BO_ 2566873767 100;
BA_ "VssMsg" BO_ 2566873767 "Mch.SMB.ACUFB1";
BA_ "Channel" BO_ 2566873767 "can1";
BA_ "GenMsgCycleTime" BO_ 2566873886 100;
BA_ "VssMsg" BO_ 2566873886 "Mch.ACU.ACUFB2";
BA_ "Channel" BO_ 2566873886 "can1";
BA_ "GenMsgCycleTime" BO_ 2566874654 100;
BA_ "VssMsg" BO_ 2566874654 "Mch.ACU.ACUFB3";
BA_ "Channel" BO_ 2566874654 "can1";
BA_ "GenMsgCycleTime" BO_ 2566874910 100;
BA_ "VssMsg" BO_ 2566874910 "Mch.ACU.ACUFB4";
BA_ "Channel" BO_ 2566874910 "can1";
BA_ "GenMsgCycleTime" BO_ 2566875297 100;
BA_ "VssMsg" BO_ 2566875297 "Mch.KPAC.ACCMD";
BA_ "Channel" BO_ 2566875297 "can1";
BA_ "GenMsgCycleTime" BO_ 2566875422 100;
BA_ "VssMsg" BO_ 2566875422 "Mch.ACU.ACUFB5";
BA_ "Channel" BO_ 2566875422 "can1";
BA_ "GenMsgCycleTime" BO_ 2566875559 100;
BA_ "VssMsg" BO_ 2566875559 "Mch.SMB.ACUFB5";
BA_ "Channel" BO_ 2566875559 "can1";
BA_ "VssMsg" BO_ 2566875678 "Mch.ACU.ACUFB6";
BA_ "Channel" BO_ 2566875678 "can1";
BA_ "VssMsg" BO_ 2566875815 "Mch.SMB.ACUFB6";
BA_ "Channel" BO_ 2566875815 "can1";
BA_ "GenMsgCycleTime" BO_ 2566875929 500;
BA_ "VssMsg" BO_ 2566875929 "Mch.ACCU.ACRM";
BA_ "Channel" BO_ 2566875929 "can1";
BA_ "GenMsgCycleTime" BO_ 2566876320 100;
BA_ "VssMsg" BO_ 2566876320 "Mch.Audio.DCAI";
BA_ "Channel" BO_ 2566876320 "can1";
BA_ "VssMsg" BO_ 2566876576 "Mch.Audio.AFRTGP";
BA_ "Channel" BO_ 2566876576 "can1";
BA_ "VssMsg" BO_ 2566876832 "Mch.Audio.APFGP";
BA_ "Channel" BO_ 2566876832 "can1";
BA_ "GenMsgCycleTime" BO_ 2566876961 100;
BA_ "VssMsg" BO_ 2566876961 "Mch.MCU.ACUCTR2";
BA_ "Channel" BO_ 2566876961 "can1";
BA_ "VssMsg" BO_ 2566877258 "Mch.TMS.TMSVI";
BA_ "Channel" BO_ 2566877258 "can1";
BA_ "VssMsg" BO_ 2566877514 "Mch.TMS.TMSVTI";
BA_ "Channel" BO_ 2566877514 "can1";
BA_ "VssMsg" BO_ 2566877770 "Mch.TGU.TMSGPSI";
BA_ "Channel" BO_ 2566877770 "can1";
BA_ "VssMsg" BO_ 2566878026 "Mch.TGU.TMSNIC";
BA_ "Channel" BO_ 2566878026 "can1";
BA_ "VssMsg" BO_ 2566878282 "Mch.TMS.TMSNIS";
BA_ "Channel" BO_ 2566878282 "can1";
BA_ "GenMsgCycleTime" BO_ 2566878794 100;
BA_ "VssMsg" BO_ 2566878794 "Mch.TGU.TSEC";
BA_ "Channel" BO_ 2566878794 "can1";
BA_ "GenMsgCycleTime" BO_ 2566879050 1000;
BA_ "VssMsg" BO_ 2566879050 "Mch.TMS.TMSGPSI2";
BA_ "Channel" BO_ 2566879050 "can1";
BA_ "VssMsg" BO_ 2566879272 "Mch.GP.TMSTP";
BA_ "Channel" BO_ 2566879272 "can1";
BA_ "VssMsg" BO_ 2566879306 "Mch.TGU.TMSTP";
BA_ "Channel" BO_ 2566879306 "can1";
BA_ "VssMsg" BO_ 2566879562 "Mch.TGU.TMSLURT";
BA_ "Channel" BO_ 2566879562 "can1";
BA_ "GenMsgCycleTime" BO_ 2566879818 100;
BA_ "VssMsg" BO_ 2566879818 "Mch.TGU.DKLI";
BA_ "Channel" BO_ 2566879818 "can1";
BA_ "VssMsg" BO_ 2566880074 "Mch.TGU.DKLD";
BA_ "Channel" BO_ 2566880074 "can1";
BA_ "VssMsg" BO_ 2566880330 "Mch.TGU.DKSEL";
BA_ "Channel" BO_ 2566880330 "can1";
BA_ "VssMsg" BO_ 2566880586 "Mch.TMS.TMSACKNACK";
BA_ "Channel" BO_ 2566880586 "can1";
BA_ "VssMsg" BO_ 2566880842 "Mch.TGU.TMSPUC";
BA_ "Channel" BO_ 2566880842 "can1";
BA_ "VssMsg" BO_ 2566881064 "Mch.GP.TMSPP";
BA_ "Channel" BO_ 2566881064 "can1";
BA_ "VssMsg" BO_ 2566881098 "Mch.TGU.TMSPP";
BA_ "Channel" BO_ 2566881098 "can1";
BA_ "GenMsgCycleTime" BO_ 2566883328 1000;
BA_ "VssMsg" BO_ 2566883328 "Mch.ECU.SCR2";
BA_ "Channel" BO_ 2566883328 "can1";
BA_ "VssMsg" BO_ 2566883873 "Mch.MCU.AASI";
BA_ "Channel" BO_ 2566883873 "can1";
BA_ "VssMsg" BO_ 2566884129 "Mch.MCU.AAAI";
BA_ "Channel" BO_ 2566884129 "can1";
BA_ "VssMsg" BO_ 2566884385 "Mch.MCU.ADSI";
BA_ "Channel" BO_ 2566884385 "can1";
BA_ "VssMsg" BO_ 2566884641 "Mch.MCU.ADAI";
BA_ "Channel" BO_ 2566884641 "can1";
BA_ "GenMsgCycleTime" BO_ 2566884897 200;
BA_ "VssMsg" BO_ 2566884897 "Mch.MCU.TIG1";
BA_ "Channel" BO_ 2566884897 "can1";
BA_ "GenMsgCycleTime" BO_ 2566885153 200;
BA_ "VssMsg" BO_ 2566885153 "Mch.MCU.TIG2";
BA_ "Channel" BO_ 2566885153 "can1";
BA_ "VssMsg" BO_ 2566885409 "Mch.MCU.QRCI";
BA_ "Channel" BO_ 2566885409 "can1";
BA_ "VssMsg" BO_ 2566885665 "Mch.MCU.ECORI";
BA_ "Channel" BO_ 2566885665 "can1";
BA_ "GenMsgCycleTime" BO_ 2566886586 100;
BA_ "VssMsg" BO_ 2566886586 "Mch.RDRR.ROZI";
BA_ "Channel" BO_ 2566886586 "can1";
BA_ "GenMsgCycleTime" BO_ 2566886587 100;
BA_ "VssMsg" BO_ 2566886587 "Mch.RDLH.ROZI";
BA_ "Channel" BO_ 2566886587 "can1";
BA_ "GenMsgCycleTime" BO_ 2566886588 100;
BA_ "VssMsg" BO_ 2566886588 "Mch.RDRH.ROZI";
BA_ "Channel" BO_ 2566886588 "can1";
BA_ "GenMsgCycleTime" BO_ 2566886842 100;
BA_ "VssMsg" BO_ 2566886842 "Mch.RDRR.ROI";
BA_ "Channel" BO_ 2566886842 "can1";
BA_ "GenMsgCycleTime" BO_ 2566886843 100;
BA_ "VssMsg" BO_ 2566886843 "Mch.RDLH.ROI";
BA_ "Channel" BO_ 2566886843 "can1";
BA_ "GenMsgCycleTime" BO_ 2566886844 100;
BA_ "VssMsg" BO_ 2566886844 "Mch.RDRH.ROI";
BA_ "Channel" BO_ 2566886844 "can1";
BA_ "GenMsgCycleTime" BO_ 2566886952 100;
BA_ "VssMsg" BO_ 2566886952 "Mch.GP.AVMVM";
BA_ "Channel" BO_ 2566886952 "can1";
BA_ "VssMsg" BO_ 2566887223 "Mch.AVM.AVMSI";
BA_ "Channel" BO_ 2566887223 "can1";
BA_ "GenMsgCycleTime" BO_ 2566887479 50;
BA_ "VssMsg" BO_ 2566887479 "Mch.AVM.AVMUS";
BA_ "Channel" BO_ 2566887479 "can1";
BA_ "GenMsgCycleTime" BO_ 2566887720 1000;
BA_ "VssMsg" BO_ 2566887720 "Mch.GP.AVMRM";
BA_ "Channel" BO_ 2566887720 "can1";
BA_ "VssMsg" BO_ 2566887991 "Mch.AVM.AVMSM";
BA_ "Channel" BO_ 2566887991 "can1";
BA_ "VssMsg" BO_ 2566888503 "Mch.AVM.AVMCP";
BA_ "Channel" BO_ 2566888503 "can1";
BA_ "VssMsg" BO_ 2566888759 "Mch.AVM.AVMVER";
BA_ "Channel" BO_ 2566888759 "can1";
BA_ "VssMsg" BO_ 2566889388 "Mch.CHMSL.CHMSLI";
BA_ "Channel" BO_ 2566889388 "can1";
BA_ "GenMsgCycleTime" BO_ 2566889512 100;
BA_ "VssMsg" BO_ 2566889512 "Mch.GP.GPCMD";
BA_ "Channel" BO_ 2566889512 "can1";
BA_ "GenMsgCycleTime" BO_ 2566889768 1000;
BA_ "VssMsg" BO_ 2566889768 "Mch.GP.GPTD";
BA_ "Channel" BO_ 2566889768 "can1";
BA_ "GenMsgCycleTime" BO_ 2566890024 1000;
BA_ "VssMsg" BO_ 2566890024 "Mch.GP.SVGP";
BA_ "Channel" BO_ 2566890024 "can1";
BA_ "GenMsgCycleTime" BO_ 2566890280 200;
BA_ "VssMsg" BO_ 2566890280 "Mch.GP.ATTFC";
BA_ "Channel" BO_ 2566890280 "can1";
BA_ "GenMsgCycleTime" BO_ 2566890536 50;
BA_ "VssMsg" BO_ 2566890536 "Mch.GP.MG2DBC";
BA_ "Channel" BO_ 2566890536 "can1";
BA_ "GenMsgCycleTime" BO_ 2566890561 50;
BA_ "VssMsg" BO_ 2566890561 "Mch.GW.MG2DBC";
BA_ "Channel" BO_ 2566890561 "can1";
BA_ "GenMsgCycleTime" BO_ 2566890792 100;
BA_ "VssMsg" BO_ 2566890792 "Mch.GP.GPCCS";
BA_ "Channel" BO_ 2566890792 "can1";
BA_ "GenMsgCycleTime" BO_ 2566891041 100;
BA_ "VssMsg" BO_ 2566891041 "Mch.MCU.ZFIMP";
BA_ "Channel" BO_ 2566891041 "can1";
BA_ "GenMsgCycleTime" BO_ 2566891688 100;
BA_ "VssMsg" BO_ 2566891688 "Mch.CTC.CAV";
BA_ "Channel" BO_ 2566891688 "can1";
BA_ "VssMsg" BO_ 2566892072 "Mch.GP.DCAP";
BA_ "Channel" BO_ 2566892072 "can1";
BA_ "VssMsg" BO_ 2566892448 "Mch.Audio.APLGP";
BA_ "Channel" BO_ 2566892448 "can1";
BA_ "VssMsg" BO_ 2566892704 "Mch.Audio.ALITGP";
BA_ "Channel" BO_ 2566892704 "can1";
BA_ "VssMsg" BO_ 2566892960 "Mch.Audio.ADLSGP";
BA_ "Channel" BO_ 2566892960 "can1";
BA_ "VssMsg" BO_ 2566893216 "Mch.Audio.AICTGP";
BA_ "Channel" BO_ 2566893216 "can1";
BA_ "VssMsg" BO_ 2566893472 "Mch.Audio.ATG";
BA_ "Channel" BO_ 2566893472 "can1";
BA_ "VssSig" SG_ 2566866977 TrgRollSlp "Mch.MCU.GPG2.TrgRollSlp";
BA_ "VssSig" SG_ 2566866977 TrgPchSlp "Mch.MCU.GPG2.TrgPchSlp";
BA_ "VssSig" SG_ 2566866977 CorrRollSlp "Mch.MCU.GPG2.CorrRollSlp";
BA_ "VssSig" SG_ 2566866977 CorrPchSlp "Mch.MCU.GPG2.CorrPchSlp";
BA_ "VssSig" SG_ 2566866977 CorrRollAng "Mch.MCU.GPG2.CorrRollAng";
BA_ "VssSig" SG_ 2566866977 CorrPchAng "Mch.MCU.GPG2.CorrPchAng";
BA_ "VssSig" SG_ 2566867233 TrgRollSlp "Mch.MCU.GPG3.TrgRollSlp";
BA_ "VssSig" SG_ 2566867233 TrgPchSlp "Mch.MCU.GPG3.TrgPchSlp";
BA_ "VssSig" SG_ 2566867233 CorrRollSlp "Mch.MCU.GPG3.CorrRollSlp";
BA_ "VssSig" SG_ 2566867233 CorrPchSlp "Mch.MCU.GPG3.CorrPchSlp";
BA_ "VssSig" SG_ 2566867489 HpApMd "Mch.MCU.SIG4.HpApMd";
BA_ "VssSig" SG_ 2566867489 GrLmt "Mch.MCU.SIG4.GrLmt";
BA_ "VssSig" SG_ 2566867489 BodyAng "Mch.MCU.SIG4.BodyAng";
BA_ "VssSig" SG_ 2566867489 WghSt "Mch.MCU.SIG4.WghSt";
BA_ "VssSig" SG_ 2566867489 BrkHold "Mch.MCU.SIG4.BrkHold";
BA_ "VssSig" SG_ 2566867489 RtrdSt "Mch.MCU.SIG4.RtrdSt";
BA_ "VssSig" SG_ 2566867489 PilotCutOffSt "Mch.MCU.SIG4.PilotCutOffSt";
BA_ "VssSig" SG_ 2566867489 BodySt "Mch.MCU.SIG4.BodySt";
BA_ "VssSig" SG_ 2566867489 VhcStGndSaw "Mch.MCU.SIG4.VhcStGndSaw";
BA_ "VssSig" SG_ 2566867489 VhcStIntAxleLck "Mch.MCU.SIG4.VhcStIntAxleLck";
BA_ "VssSig" SG_ 2566867489 TrlHhFlowMd "Mch.MCU.SIG4.TrlHhFlowMd";
BA_ "VssSig" SG_ 2566867489 ExcAutoBrkAntiFire "Mch.MCU.SIG4.ExcAutoBrkAntiFire";
BA_ "VssSig" SG_ 2566867489 TrlIntLckOvrd "Mch.MCU.SIG4.TrlIntLckOvrd";
BA_ "VssSig" SG_ 2566867489 TrlCtrlFlow "Mch.MCU.SIG4.TrlCtrlFlow";
BA_ "VssSig" SG_ 2566867489 TrlSelfLv "Mch.MCU.SIG4.TrlSelfLv";
BA_ "VssSig" SG_ 2566867489 TrlHhFlow "Mch.MCU.SIG4.TrlHhFlow";
BA_ "VssSig" SG_ 2566867745 EcoGgSt "Mch.MCU.GPG4.EcoGgSt";
BA_ "VssSig" SG_ 2566867745 EcoGgLv "Mch.MCU.GPG4.EcoGgLv";
BA_ "VssSig" SG_ 2566868257 MaximumEgSpd "Mch.MCU.METPSC.MaximumEgSpd";
BA_ "VssSig" SG_ 2566868257 AutoCalbMd "Mch.MCU.METPSC.AutoCalbMd";
BA_ "VssSig" SG_ 2566868257 CalbReq "Mch.MCU.METPSC.CalbReq";
BA_ "VssSig" SG_ 2566868257 VhcStTpsCalb "Mch.MCU.METPSC.VhcStTpsCalb";
BA_ "VssSig" SG_ 2566868257 MinimumEgSpd "Mch.MCU.METPSC.MinimumEgSpd";
BA_ "VssSig" SG_ 2566868257 VhcStSsNrm "Mch.MCU.METPSC.VhcStSsNrm";
BA_ "VssSig" SG_ 2566868257 VhcStEgIgn "Mch.MCU.METPSC.VhcStEgIgn";
BA_ "VssSig" SG_ 2566868257 VhcStPilotCutOff "Mch.MCU.METPSC.VhcStPilotCutOff";
BA_ "VssSig" SG_ 2566868257 VhcStEgCtrlDialMax "Mch.MCU.METPSC.VhcStEgCtrlDialMax";
BA_ "VssSig" SG_ 2365542696 PwforthisMsg "Mch.GP.JCM.PwforthisMsg";
BA_ "VssSig" SG_ 2365542696 EncoderDtDefineMax "Mch.GP.JCM.EncoderDtDefineMax";
BA_ "VssSig" SG_ 2365542696 BrctRateforDtPck "Mch.GP.JCM.BrctRateforDtPck";
BA_ "VssSig" SG_ 2365542696 PgnforDtPck "Mch.GP.JCM.PgnforDtPck";
BA_ "VssSig" SG_ 2365542696 SrcAd "Mch.GP.JCM.SrcAd";
BA_ "VssSig" SG_ 2365542696 BacklightIntensity "Mch.GP.JCM.BacklightIntensity";
BA_ "VssSig" SG_ 2566873377 LowOutReq8 "Mch.MCU.ACUCTR.LowOutReq8";
BA_ "VssSig" SG_ 2566873377 LowOutReq7 "Mch.MCU.ACUCTR.LowOutReq7";
BA_ "VssSig" SG_ 2566873377 LowOutReq6 "Mch.MCU.ACUCTR.LowOutReq6";
BA_ "VssSig" SG_ 2566873377 LowOutReq5 "Mch.MCU.ACUCTR.LowOutReq5";
BA_ "VssSig" SG_ 2566873377 LowOutReq4 "Mch.MCU.ACUCTR.LowOutReq4";
BA_ "VssSig" SG_ 2566873377 LowOutReq3 "Mch.MCU.ACUCTR.LowOutReq3";
BA_ "VssSig" SG_ 2566873377 LowOutReq2 "Mch.MCU.ACUCTR.LowOutReq2";
BA_ "VssSig" SG_ 2566873377 LowOutReq1 "Mch.MCU.ACUCTR.LowOutReq1";
BA_ "VssSig" SG_ 2566873377 OutReq15 "Mch.MCU.ACUCTR.OutReq15";
BA_ "VssSig" SG_ 2566873377 OutReq14 "Mch.MCU.ACUCTR.OutReq14";
BA_ "VssSig" SG_ 2566873377 OutReq13 "Mch.MCU.ACUCTR.OutReq13";
BA_ "VssSig" SG_ 2566873377 OutReq12 "Mch.MCU.ACUCTR.OutReq12";
BA_ "VssSig" SG_ 2566873377 OutReq11 "Mch.MCU.ACUCTR.OutReq11";
BA_ "VssSig" SG_ 2566873377 OutReq10 "Mch.MCU.ACUCTR.OutReq10";
BA_ "VssSig" SG_ 2566873377 OutReq9 "Mch.MCU.ACUCTR.OutReq9";
BA_ "VssSig" SG_ 2566873377 OutReq8 "Mch.MCU.ACUCTR.OutReq8";
BA_ "VssSig" SG_ 2566873377 OutReq7 "Mch.MCU.ACUCTR.OutReq7";
BA_ "VssSig" SG_ 2566873377 OutReq6 "Mch.MCU.ACUCTR.OutReq6";
BA_ "VssSig" SG_ 2566873377 OutReq5 "Mch.MCU.ACUCTR.OutReq5";
BA_ "VssSig" SG_ 2566873377 OutReq4 "Mch.MCU.ACUCTR.OutReq4";
BA_ "VssSig" SG_ 2566873377 OutReq3 "Mch.MCU.ACUCTR.OutReq3";
BA_ "VssSig" SG_ 2566873377 OutReq2 "Mch.MCU.ACUCTR.OutReq2";
BA_ "VssSig" SG_ 2566873377 OutReq1 "Mch.MCU.ACUCTR.OutReq1";
BA_ "VssSig" SG_ 2566873630 OutFdbkCur8 "Mch.ACU.ACUFB1.OutFdbkCur8";
BA_ "VssSig" SG_ 2566873630 OutFdbkCur7 "Mch.ACU.ACUFB1.OutFdbkCur7";
BA_ "VssSig" SG_ 2566873630 OutFdbkCur6 "Mch.ACU.ACUFB1.OutFdbkCur6";
BA_ "VssSig" SG_ 2566873630 OutFdbkCur5 "Mch.ACU.ACUFB1.OutFdbkCur5";
BA_ "VssSig" SG_ 2566873630 OutFdbkCur4 "Mch.ACU.ACUFB1.OutFdbkCur4";
BA_ "VssSig" SG_ 2566873630 OutFdbkCur3 "Mch.ACU.ACUFB1.OutFdbkCur3";
BA_ "VssSig" SG_ 2566873630 OutFdbkCur2 "Mch.ACU.ACUFB1.OutFdbkCur2";
BA_ "VssSig" SG_ 2566873630 OutFdbkCur1 "Mch.ACU.ACUFB1.OutFdbkCur1";
BA_ "VssSig" SG_ 2566873767 OutFdbkCur8 "Mch.SMB.ACUFB1.OutFdbkCur8";
BA_ "VssSig" SG_ 2566873767 OutFdbkCur7 "Mch.SMB.ACUFB1.OutFdbkCur7";
BA_ "VssSig" SG_ 2566873767 OutFdbkCur6 "Mch.SMB.ACUFB1.OutFdbkCur6";
BA_ "VssSig" SG_ 2566873767 OutFdbkCur5 "Mch.SMB.ACUFB1.OutFdbkCur5";
BA_ "VssSig" SG_ 2566873767 OutFdbkCur4 "Mch.SMB.ACUFB1.OutFdbkCur4";
BA_ "VssSig" SG_ 2566873767 OutFdbkCur3 "Mch.SMB.ACUFB1.OutFdbkCur3";
BA_ "VssSig" SG_ 2566873767 OutFdbkCur2 "Mch.SMB.ACUFB1.OutFdbkCur2";
BA_ "VssSig" SG_ 2566873767 OutFdbkCur1 "Mch.SMB.ACUFB1.OutFdbkCur1";
BA_ "VssSig" SG_ 2566873886 ErrorFlag "Mch.ACU.ACUFB2.ErrorFlag";
BA_ "VssSig" SG_ 2566873886 VltIn2 "Mch.ACU.ACUFB2.VltIn2";
BA_ "VssSig" SG_ 2566873886 VltIn1 "Mch.ACU.ACUFB2.VltIn1";
BA_ "VssSig" SG_ 2566873886 OutFdbkCur13 "Mch.ACU.ACUFB2.OutFdbkCur13";
BA_ "VssSig" SG_ 2566873886 OutFdbkCur12 "Mch.ACU.ACUFB2.OutFdbkCur12";
BA_ "VssSig" SG_ 2566873886 OutFdbkCur11 "Mch.ACU.ACUFB2.OutFdbkCur11";
BA_ "VssSig" SG_ 2566873886 OutFdbkCur10 "Mch.ACU.ACUFB2.OutFdbkCur10";
BA_ "VssSig" SG_ 2566873886 OutFdbkCur9 "Mch.ACU.ACUFB2.OutFdbkCur9";
BA_ "VssSig" SG_ 2566874654 OutFdbkActvLowCur8 "Mch.ACU.ACUFB3.OutFdbkActvLowCur8";
BA_ "VssSig" SG_ 2566874654 OutFdbkActvLowCur7 "Mch.ACU.ACUFB3.OutFdbkActvLowCur7";
BA_ "VssSig" SG_ 2566874654 OutFdbkActvLowCur6 "Mch.ACU.ACUFB3.OutFdbkActvLowCur6";
BA_ "VssSig" SG_ 2566874654 OutFdbkActvLowCur5 "Mch.ACU.ACUFB3.OutFdbkActvLowCur5";
BA_ "VssSig" SG_ 2566874654 OutFdbkActvLowCur4 "Mch.ACU.ACUFB3.OutFdbkActvLowCur4";
BA_ "VssSig" SG_ 2566874654 OutFdbkActvLowCur3 "Mch.ACU.ACUFB3.OutFdbkActvLowCur3";
BA_ "VssSig" SG_ 2566874654 OutFdbkActvLowCur2 "Mch.ACU.ACUFB3.OutFdbkActvLowCur2";
BA_ "VssSig" SG_ 2566874654 OutFdbkActvLowCur1 "Mch.ACU.ACUFB3.OutFdbkActvLowCur1";
BA_ "VssSig" SG_ 2566874654 OutFdbkActvHighCur15 "Mch.ACU.ACUFB3.OutFdbkActvHighCur15";
BA_ "VssSig" SG_ 2566874654 OutFdbkActvHighCur14 "Mch.ACU.ACUFB3.OutFdbkActvHighCur14";
BA_ "VssSig" SG_ 2566874654 OutFdbkActvHighCur13 "Mch.ACU.ACUFB3.OutFdbkActvHighCur13";
BA_ "VssSig" SG_ 2566874654 OutFdbkActvHighCur12 "Mch.ACU.ACUFB3.OutFdbkActvHighCur12";
BA_ "VssSig" SG_ 2566874654 OutFdbkActvHighCur11 "Mch.ACU.ACUFB3.OutFdbkActvHighCur11";
BA_ "VssSig" SG_ 2566874654 OutFdbkActvHighCur10 "Mch.ACU.ACUFB3.OutFdbkActvHighCur10";
BA_ "VssSig" SG_ 2566874654 OutFdbkActvHighCur9 "Mch.ACU.ACUFB3.OutFdbkActvHighCur9";
BA_ "VssSig" SG_ 2566874654 OutFdbkActvHighCur8 "Mch.ACU.ACUFB3.OutFdbkActvHighCur8";
BA_ "VssSig" SG_ 2566874654 OutFdbkActvHighCur7 "Mch.ACU.ACUFB3.OutFdbkActvHighCur7";
BA_ "VssSig" SG_ 2566874654 OutFdbkActvHighCur6 "Mch.ACU.ACUFB3.OutFdbkActvHighCur6";
BA_ "VssSig" SG_ 2566874654 OutFdbkActvHighCur5 "Mch.ACU.ACUFB3.OutFdbkActvHighCur5";
BA_ "VssSig" SG_ 2566874654 OutFdbkActvHighCur4 "Mch.ACU.ACUFB3.OutFdbkActvHighCur4";
BA_ "VssSig" SG_ 2566874654 OutFdbkActvHighCur3 "Mch.ACU.ACUFB3.OutFdbkActvHighCur3";
BA_ "VssSig" SG_ 2566874654 OutFdbkActvHighCur2 "Mch.ACU.ACUFB3.OutFdbkActvHighCur2";
BA_ "VssSig" SG_ 2566874654 OutFdbkActvHighCur1 "Mch.ACU.ACUFB3.OutFdbkActvHighCur1";
BA_ "VssSig" SG_ 2566874910 InVlt12 "Mch.ACU.ACUFB4.InVlt12";
BA_ "VssSig" SG_ 2566874910 InVlt11 "Mch.ACU.ACUFB4.InVlt11";
BA_ "VssSig" SG_ 2566874910 InVlt10 "Mch.ACU.ACUFB4.InVlt10";
BA_ "VssSig" SG_ 2566874910 InVlt9 "Mch.ACU.ACUFB4.InVlt9";
BA_ "VssSig" SG_ 2566874910 InVlt8 "Mch.ACU.ACUFB4.InVlt8";
BA_ "VssSig" SG_ 2566874910 InVlt7 "Mch.ACU.ACUFB4.InVlt7";
BA_ "VssSig" SG_ 2566874910 InVlt6 "Mch.ACU.ACUFB4.InVlt6";
BA_ "VssSig" SG_ 2566874910 InVlt5 "Mch.ACU.ACUFB4.InVlt5";
BA_ "VssSig" SG_ 2566874910 InVlt4 "Mch.ACU.ACUFB4.InVlt4";
BA_ "VssSig" SG_ 2566874910 InVlt3 "Mch.ACU.ACUFB4.InVlt3";
BA_ "VssSig" SG_ 2566874910 InVlt2 "Mch.ACU.ACUFB4.InVlt2";
BA_ "VssSig" SG_ 2566874910 InVlt1 "Mch.ACU.ACUFB4.InVlt1";
BA_ "VssSig" SG_ 2566875422 OutFdbkCur12 "Mch.ACU.ACUFB5.OutFdbkCur12";
BA_ "VssSig" SG_ 2566875422 OutFdbkCur11 "Mch.ACU.ACUFB5.OutFdbkCur11";
BA_ "VssSig" SG_ 2566875422 OutFdbkCur10 "Mch.ACU.ACUFB5.OutFdbkCur10";
BA_ "VssSig" SG_ 2566875422 OutFdbkCur9 "Mch.ACU.ACUFB5.OutFdbkCur9";
BA_ "VssSig" SG_ 2566875559 OutFdbkCur12 "Mch.SMB.ACUFB5.OutFdbkCur12";
BA_ "VssSig" SG_ 2566875559 OutFdbkCur11 "Mch.SMB.ACUFB5.OutFdbkCur11";
BA_ "VssSig" SG_ 2566875559 OutFdbkCur10 "Mch.SMB.ACUFB5.OutFdbkCur10";
BA_ "VssSig" SG_ 2566875559 OutFdbkCur9 "Mch.SMB.ACUFB5.OutFdbkCur9";
BA_ "VssSig" SG_ 2566875678 MiniRly30AFuse2St "Mch.ACU.ACUFB6.MiniRly30AFuse2St";
BA_ "VssSig" SG_ 2566875678 MiniRly30AFuse1St "Mch.ACU.ACUFB6.MiniRly30AFuse1St";
BA_ "VssSig" SG_ 2566875678 MicroRly20AFuse5St "Mch.ACU.ACUFB6.MicroRly20AFuse5St";
BA_ "VssSig" SG_ 2566875678 MicroRly20AFuse4St "Mch.ACU.ACUFB6.MicroRly20AFuse4St";
BA_ "VssSig" SG_ 2566875678 MicroRly20AFuse3St "Mch.ACU.ACUFB6.MicroRly20AFuse3St";
BA_ "VssSig" SG_ 2566875678 MicroRly20AFuse2St "Mch.ACU.ACUFB6.MicroRly20AFuse2St";
BA_ "VssSig" SG_ 2566875678 MicroRly20AFuse1St "Mch.ACU.ACUFB6.MicroRly20AFuse1St";
BA_ "VssSig" SG_ 2566875678 KeyOn30AFuse5St "Mch.ACU.ACUFB6.KeyOn30AFuse5St";
BA_ "VssSig" SG_ 2566875678 KeyOn30AFuse4St "Mch.ACU.ACUFB6.KeyOn30AFuse4St";
BA_ "VssSig" SG_ 2566875678 KeyOn30AFuse3St "Mch.ACU.ACUFB6.KeyOn30AFuse3St";
BA_ "VssSig" SG_ 2566875678 KeyOn30AFuse2St "Mch.ACU.ACUFB6.KeyOn30AFuse2St";
BA_ "VssSig" SG_ 2566875678 KeyOn30AFuse1St "Mch.ACU.ACUFB6.KeyOn30AFuse1St";
BA_ "VssSig" SG_ 2566875678 KeyOn20AFuse10St "Mch.ACU.ACUFB6.KeyOn20AFuse10St";
BA_ "VssSig" SG_ 2566875678 KeyOn20AFuse9St "Mch.ACU.ACUFB6.KeyOn20AFuse9St";
BA_ "VssSig" SG_ 2566875678 KeyOn20AFuse8St "Mch.ACU.ACUFB6.KeyOn20AFuse8St";
BA_ "VssSig" SG_ 2566875678 KeyOn20AFuse7St "Mch.ACU.ACUFB6.KeyOn20AFuse7St";
BA_ "VssSig" SG_ 2566875678 KeyOn20AFuse6St "Mch.ACU.ACUFB6.KeyOn20AFuse6St";
BA_ "VssSig" SG_ 2566875678 KeyOn20AFuse5St "Mch.ACU.ACUFB6.KeyOn20AFuse5St";
BA_ "VssSig" SG_ 2566875678 KeyOn20AFuse4St "Mch.ACU.ACUFB6.KeyOn20AFuse4St";
BA_ "VssSig" SG_ 2566875678 KeyOn20AFuse3St "Mch.ACU.ACUFB6.KeyOn20AFuse3St";
BA_ "VssSig" SG_ 2566875678 KeyOn20AFuse2St "Mch.ACU.ACUFB6.KeyOn20AFuse2St";
BA_ "VssSig" SG_ 2566875678 KeyOn20AFuse1St "Mch.ACU.ACUFB6.KeyOn20AFuse1St";
BA_ "VssSig" SG_ 2566875678 KeyOn10AFuse5St "Mch.ACU.ACUFB6.KeyOn10AFuse5St";
BA_ "VssSig" SG_ 2566875678 KeyOn10AFuse4St "Mch.ACU.ACUFB6.KeyOn10AFuse4St";
BA_ "VssSig" SG_ 2566875678 KeyOn10AFuse3St "Mch.ACU.ACUFB6.KeyOn10AFuse3St";
BA_ "VssSig" SG_ 2566875678 KeyOn10AFuse2St "Mch.ACU.ACUFB6.KeyOn10AFuse2St";
BA_ "VssSig" SG_ 2566875678 KeyOn10AFuse1St "Mch.ACU.ACUFB6.KeyOn10AFuse1St";
BA_ "VssSig" SG_ 2566875678 KeyOn5AFuse15St "Mch.ACU.ACUFB6.KeyOn5AFuse15St";
BA_ "VssSig" SG_ 2566875678 KeyOn5AFuse14St "Mch.ACU.ACUFB6.KeyOn5AFuse14St";
BA_ "VssSig" SG_ 2566875678 KeyOn5AFuse13St "Mch.ACU.ACUFB6.KeyOn5AFuse13St";
BA_ "VssSig" SG_ 2566875678 KeyOn5AFuse12St "Mch.ACU.ACUFB6.KeyOn5AFuse12St";
BA_ "VssSig" SG_ 2566875678 KeyOn5AFuse11St "Mch.ACU.ACUFB6.KeyOn5AFuse11St";
BA_ "VssSig" SG_ 2566875678 KeyOn5AFuse10St "Mch.ACU.ACUFB6.KeyOn5AFuse10St";
BA_ "VssSig" SG_ 2566875678 KeyOn5AFuse9St "Mch.ACU.ACUFB6.KeyOn5AFuse9St";
BA_ "VssSig" SG_ 2566875678 KeyOn5AFuse8St "Mch.ACU.ACUFB6.KeyOn5AFuse8St";
BA_ "VssSig" SG_ 2566875678 KeyOn5AFuse7St "Mch.ACU.ACUFB6.KeyOn5AFuse7St";
BA_ "VssSig" SG_ 2566875678 KeyOn5AFuse6St "Mch.ACU.ACUFB6.KeyOn5AFuse6St";
BA_ "VssSig" SG_ 2566875678 KeyOn5AFuse5St "Mch.ACU.ACUFB6.KeyOn5AFuse5St";
BA_ "VssSig" SG_ 2566875678 KeyOn5AFuse4St "Mch.ACU.ACUFB6.KeyOn5AFuse4St";
BA_ "VssSig" SG_ 2566875678 KeyOn5AFuse3St "Mch.ACU.ACUFB6.KeyOn5AFuse3St";
BA_ "VssSig" SG_ 2566875678 KeyOn5AFuse2St "Mch.ACU.ACUFB6.KeyOn5AFuse2St";
BA_ "VssSig" SG_ 2566875678 KeyOn5AFuse1St "Mch.ACU.ACUFB6.KeyOn5AFuse1St";
BA_ "VssSig" SG_ 2566875678 BPlus30AFuse5St "Mch.ACU.ACUFB6.BPlus30AFuse5St";
BA_ "VssSig" SG_ 2566875678 BPlus30AFuse4St "Mch.ACU.ACUFB6.BPlus30AFuse4St";
BA_ "VssSig" SG_ 2566875678 BPlus30AFuse3St "Mch.ACU.ACUFB6.BPlus30AFuse3St";
BA_ "VssSig" SG_ 2566875678 BPlus30AFuse2St "Mch.ACU.ACUFB6.BPlus30AFuse2St";
BA_ "VssSig" SG_ 2566875678 BPlus30AFuse1St "Mch.ACU.ACUFB6.BPlus30AFuse1St";
BA_ "VssSig" SG_ 2566875678 BPlus20AFuse5St "Mch.ACU.ACUFB6.BPlus20AFuse5St";
BA_ "VssSig" SG_ 2566875678 BPlus20AFuse4St "Mch.ACU.ACUFB6.BPlus20AFuse4St";
BA_ "VssSig" SG_ 2566875678 BPlus20AFuse3St "Mch.ACU.ACUFB6.BPlus20AFuse3St";
BA_ "VssSig" SG_ 2566875678 BPlus20AFuse2St "Mch.ACU.ACUFB6.BPlus20AFuse2St";
BA_ "VssSig" SG_ 2566875678 BPlus20AFuse1St "Mch.ACU.ACUFB6.BPlus20AFuse1St";
BA_ "VssSig" SG_ 2566875678 BPlus5AFuse10St "Mch.ACU.ACUFB6.BPlus5AFuse10St";
BA_ "VssSig" SG_ 2566875678 BPlus5AFuse9St "Mch.ACU.ACUFB6.BPlus5AFuse9St";
BA_ "VssSig" SG_ 2566875678 BPlus5AFuse8St "Mch.ACU.ACUFB6.BPlus5AFuse8St";
BA_ "VssSig" SG_ 2566875678 BPlus5AFuse7St "Mch.ACU.ACUFB6.BPlus5AFuse7St";
BA_ "VssSig" SG_ 2566875678 BPlus5AFuse6St "Mch.ACU.ACUFB6.BPlus5AFuse6St";
BA_ "VssSig" SG_ 2566875678 BPlus5AFuse5St "Mch.ACU.ACUFB6.BPlus5AFuse5St";
BA_ "VssSig" SG_ 2566875678 BPlus5AFuse4St "Mch.ACU.ACUFB6.BPlus5AFuse4St";
BA_ "VssSig" SG_ 2566875678 BPlus5AFuse3St "Mch.ACU.ACUFB6.BPlus5AFuse3St";
BA_ "VssSig" SG_ 2566875678 BPlus5AFuse2St "Mch.ACU.ACUFB6.BPlus5AFuse2St";
BA_ "VssSig" SG_ 2566875678 BPlus5AFuse1St "Mch.ACU.ACUFB6.BPlus5AFuse1St";
BA_ "VssSig" SG_ 2566875678 IPSTotalCur "Mch.ACU.ACUFB6.IPSTotalCur";
BA_ "VssSig" SG_ 2566875678 MINIFuse2Cur "Mch.ACU.ACUFB6.MINIFuse2Cur";
BA_ "VssSig" SG_ 2566875678 MINIFuse1Cur "Mch.ACU.ACUFB6.MINIFuse1Cur";
BA_ "VssSig" SG_ 2566875678 MicroFuse5Cur "Mch.ACU.ACUFB6.MicroFuse5Cur";
BA_ "VssSig" SG_ 2566875678 MicroFuse4Cur "Mch.ACU.ACUFB6.MicroFuse4Cur";
BA_ "VssSig" SG_ 2566875678 MicroFuse3Cur "Mch.ACU.ACUFB6.MicroFuse3Cur";
BA_ "VssSig" SG_ 2566875678 MicroFuse2Cur "Mch.ACU.ACUFB6.MicroFuse2Cur";
BA_ "VssSig" SG_ 2566875678 MicroFuse1Cur "Mch.ACU.ACUFB6.MicroFuse1Cur";
BA_ "VssSig" SG_ 2566875678 KeyOnPwrCur "Mch.ACU.ACUFB6.KeyOnPwrCur";
BA_ "VssSig" SG_ 2566875678 BPlusPwrCur "Mch.ACU.ACUFB6.BPlusPwrCur";
BA_ "VssSig" SG_ 2566875815 MiniRly30AFuse2St "Mch.SMB.ACUFB6.MiniRly30AFuse2St";
BA_ "VssSig" SG_ 2566875815 MiniRly30AFuse1St "Mch.SMB.ACUFB6.MiniRly30AFuse1St";
BA_ "VssSig" SG_ 2566875815 MicroRly20AFuse5St "Mch.SMB.ACUFB6.MicroRly20AFuse5St";
BA_ "VssSig" SG_ 2566875815 MicroRly20AFuse4St "Mch.SMB.ACUFB6.MicroRly20AFuse4St";
BA_ "VssSig" SG_ 2566875815 MicroRly20AFuse3St "Mch.SMB.ACUFB6.MicroRly20AFuse3St";
BA_ "VssSig" SG_ 2566875815 MicroRly20AFuse2St "Mch.SMB.ACUFB6.MicroRly20AFuse2St";
BA_ "VssSig" SG_ 2566875815 MicroRly20AFuse1St "Mch.SMB.ACUFB6.MicroRly20AFuse1St";
BA_ "VssSig" SG_ 2566875815 KeyOn30AFuse5St "Mch.SMB.ACUFB6.KeyOn30AFuse5St";
BA_ "VssSig" SG_ 2566875815 KeyOn30AFuse4St "Mch.SMB.ACUFB6.KeyOn30AFuse4St";
BA_ "VssSig" SG_ 2566875815 KeyOn30AFuse3St "Mch.SMB.ACUFB6.KeyOn30AFuse3St";
BA_ "VssSig" SG_ 2566875815 KeyOn30AFuse2St "Mch.SMB.ACUFB6.KeyOn30AFuse2St";
BA_ "VssSig" SG_ 2566875815 KeyOn30AFuse1St "Mch.SMB.ACUFB6.KeyOn30AFuse1St";
BA_ "VssSig" SG_ 2566875815 KeyOn20AFuse10St "Mch.SMB.ACUFB6.KeyOn20AFuse10St";
BA_ "VssSig" SG_ 2566875815 KeyOn20AFuse9St "Mch.SMB.ACUFB6.KeyOn20AFuse9St";
BA_ "VssSig" SG_ 2566875815 KeyOn20AFuse8St "Mch.SMB.ACUFB6.KeyOn20AFuse8St";
BA_ "VssSig" SG_ 2566875815 KeyOn20AFuse7St "Mch.SMB.ACUFB6.KeyOn20AFuse7St";
BA_ "VssSig" SG_ 2566875815 KeyOn20AFuse6St "Mch.SMB.ACUFB6.KeyOn20AFuse6St";
BA_ "VssSig" SG_ 2566875815 KeyOn20AFuse5St "Mch.SMB.ACUFB6.KeyOn20AFuse5St";
BA_ "VssSig" SG_ 2566875815 KeyOn20AFuse4St "Mch.SMB.ACUFB6.KeyOn20AFuse4St";
BA_ "VssSig" SG_ 2566875815 KeyOn20AFuse3St "Mch.SMB.ACUFB6.KeyOn20AFuse3St";
BA_ "VssSig" SG_ 2566875815 KeyOn20AFuse2St "Mch.SMB.ACUFB6.KeyOn20AFuse2St";
BA_ "VssSig" SG_ 2566875815 KeyOn20AFuse1St "Mch.SMB.ACUFB6.KeyOn20AFuse1St";
BA_ "VssSig" SG_ 2566875815 KeyOn10AFuse5St "Mch.SMB.ACUFB6.KeyOn10AFuse5St";
BA_ "VssSig" SG_ 2566875815 KeyOn10AFuse4St "Mch.SMB.ACUFB6.KeyOn10AFuse4St";
BA_ "VssSig" SG_ 2566875815 KeyOn10AFuse3St "Mch.SMB.ACUFB6.KeyOn10AFuse3St";
BA_ "VssSig" SG_ 2566875815 KeyOn10AFuse2St "Mch.SMB.ACUFB6.KeyOn10AFuse2St";
BA_ "VssSig" SG_ 2566875815 KeyOn10AFuse1St "Mch.SMB.ACUFB6.KeyOn10AFuse1St";
BA_ "VssSig" SG_ 2566875815 KeyOn5AFuse15St "Mch.SMB.ACUFB6.KeyOn5AFuse15St";
BA_ "VssSig" SG_ 2566875815 KeyOn5AFuse14St "Mch.SMB.ACUFB6.KeyOn5AFuse14St";
BA_ "VssSig" SG_ 2566875815 KeyOn5AFuse13St "Mch.SMB.ACUFB6.KeyOn5AFuse13St";
BA_ "VssSig" SG_ 2566875815 KeyOn5AFuse12St "Mch.SMB.ACUFB6.KeyOn5AFuse12St";
BA_ "VssSig" SG_ 2566875815 KeyOn5AFuse11St "Mch.SMB.ACUFB6.KeyOn5AFuse11St";
BA_ "VssSig" SG_ 2566875815 KeyOn5AFuse10St "Mch.SMB.ACUFB6.KeyOn5AFuse10St";
BA_ "VssSig" SG_ 2566875815 KeyOn5AFuse9St "Mch.SMB.ACUFB6.KeyOn5AFuse9St";
BA_ "VssSig" SG_ 2566875815 KeyOn5AFuse8St "Mch.SMB.ACUFB6.KeyOn5AFuse8St";
BA_ "VssSig" SG_ 2566875815 KeyOn5AFuse7St "Mch.SMB.ACUFB6.KeyOn5AFuse7St";
BA_ "VssSig" SG_ 2566875815 KeyOn5AFuse6St "Mch.SMB.ACUFB6.KeyOn5AFuse6St";
BA_ "VssSig" SG_ 2566875815 KeyOn5AFuse5St "Mch.SMB.ACUFB6.KeyOn5AFuse5St";
BA_ "VssSig" SG_ 2566875815 KeyOn5AFuse4St "Mch.SMB.ACUFB6.KeyOn5AFuse4St";
BA_ "VssSig" SG_ 2566875815 KeyOn5AFuse3St "Mch.SMB.ACUFB6.KeyOn5AFuse3St";
BA_ "VssSig" SG_ 2566875815 KeyOn5AFuse2St "Mch.SMB.ACUFB6.KeyOn5AFuse2St";
BA_ "VssSig" SG_ 2566875815 KeyOn5AFuse1St "Mch.SMB.ACUFB6.KeyOn5AFuse1St";
BA_ "VssSig" SG_ 2566875815 BPlus30AFuse5St "Mch.SMB.ACUFB6.BPlus30AFuse5St";
BA_ "VssSig" SG_ 2566875815 BPlus30AFuse4St "Mch.SMB.ACUFB6.BPlus30AFuse4St";
BA_ "VssSig" SG_ 2566875815 BPlus30AFuse3St "Mch.SMB.ACUFB6.BPlus30AFuse3St";
BA_ "VssSig" SG_ 2566875815 BPlus30AFuse2St "Mch.SMB.ACUFB6.BPlus30AFuse2St";
BA_ "VssSig" SG_ 2566875815 BPlus30AFuse1St "Mch.SMB.ACUFB6.BPlus30AFuse1St";
BA_ "VssSig" SG_ 2566875815 BPlus20AFuse5St "Mch.SMB.ACUFB6.BPlus20AFuse5St";
BA_ "VssSig" SG_ 2566875815 BPlus20AFuse4St "Mch.SMB.ACUFB6.BPlus20AFuse4St";
BA_ "VssSig" SG_ 2566875815 BPlus20AFuse3St "Mch.SMB.ACUFB6.BPlus20AFuse3St";
BA_ "VssSig" SG_ 2566875815 BPlus20AFuse2St "Mch.SMB.ACUFB6.BPlus20AFuse2St";
BA_ "VssSig" SG_ 2566875815 BPlus20AFuse1St "Mch.SMB.ACUFB6.BPlus20AFuse1St";
BA_ "VssSig" SG_ 2566875815 BPlus5AFuse10St "Mch.SMB.ACUFB6.BPlus5AFuse10St";
BA_ "VssSig" SG_ 2566875815 BPlus5AFuse9St "Mch.SMB.ACUFB6.BPlus5AFuse9St";
BA_ "VssSig" SG_ 2566875815 BPlus5AFuse8St "Mch.SMB.ACUFB6.BPlus5AFuse8St";
BA_ "VssSig" SG_ 2566875815 BPlus5AFuse7St "Mch.SMB.ACUFB6.BPlus5AFuse7St";
BA_ "VssSig" SG_ 2566875815 BPlus5AFuse6St "Mch.SMB.ACUFB6.BPlus5AFuse6St";
BA_ "VssSig" SG_ 2566875815 BPlus5AFuse5St "Mch.SMB.ACUFB6.BPlus5AFuse5St";
BA_ "VssSig" SG_ 2566875815 BPlus5AFuse4St "Mch.SMB.ACUFB6.BPlus5AFuse4St";
BA_ "VssSig" SG_ 2566875815 BPlus5AFuse3St "Mch.SMB.ACUFB6.BPlus5AFuse3St";
BA_ "VssSig" SG_ 2566875815 BPlus5AFuse2St "Mch.SMB.ACUFB6.BPlus5AFuse2St";
BA_ "VssSig" SG_ 2566875815 BPlus5AFuse1St "Mch.SMB.ACUFB6.BPlus5AFuse1St";
BA_ "VssSig" SG_ 2566875815 IPSTotalCur "Mch.SMB.ACUFB6.IPSTotalCur";
BA_ "VssSig" SG_ 2566875815 MINIFuse2Cur "Mch.SMB.ACUFB6.MINIFuse2Cur";
BA_ "VssSig" SG_ 2566875815 MINIFuse1Cur "Mch.SMB.ACUFB6.MINIFuse1Cur";
BA_ "VssSig" SG_ 2566875815 MicroFuse5Cur "Mch.SMB.ACUFB6.MicroFuse5Cur";
BA_ "VssSig" SG_ 2566875815 MicroFuse4Cur "Mch.SMB.ACUFB6.MicroFuse4Cur";
BA_ "VssSig" SG_ 2566875815 MicroFuse3Cur "Mch.SMB.ACUFB6.MicroFuse3Cur";
BA_ "VssSig" SG_ 2566875815 MicroFuse2Cur "Mch.SMB.ACUFB6.MicroFuse2Cur";
BA_ "VssSig" SG_ 2566875815 MicroFuse1Cur "Mch.SMB.ACUFB6.MicroFuse1Cur";
BA_ "VssSig" SG_ 2566875815 KeyOnPwrCur "Mch.SMB.ACUFB6.KeyOnPwrCur";
BA_ "VssSig" SG_ 2566875815 BPlusPwrCur "Mch.SMB.ACUFB6.BPlusPwrCur";
BA_ "VssSig" SG_ 2566875929 AcpSsPrs "Mch.ACCU.ACRM.AcpSsPrs";
BA_ "VssSig" SG_ 2566875929 CurAmbTmpCelsRealTm "Mch.ACCU.ACRM.CurAmbTmpCelsRealTm";
BA_ "VssSig" SG_ 2566875929 TmpSt "Mch.ACCU.ACRM.TmpSt";
BA_ "VssSig" SG_ 2566875929 CurBlowerSpd "Mch.ACCU.ACRM.CurBlowerSpd";
BA_ "VssSig" SG_ 2566875929 CurAmbTmpCelsFilt "Mch.ACCU.ACRM.CurAmbTmpCelsFilt";
BA_ "VssSig" SG_ 2566875929 VhcStSybACOffInd "Mch.ACCU.ACRM.VhcStSybACOffInd";
BA_ "VssSig" SG_ 2566875929 CurTmpSet "Mch.ACCU.ACRM.CurTmpSet";
BA_ "VssSig" SG_ 2566875929 CpsSt "Mch.ACCU.ACRM.CpsSt";
BA_ "VssSig" SG_ 2566875929 TmpSetValBelowSt "Mch.ACCU.ACRM.TmpSetValBelowSt";
BA_ "VssSig" SG_ 2566875929 TmpSetValOverSt "Mch.ACCU.ACRM.TmpSetValOverSt";
BA_ "VssSig" SG_ 2566875929 HvacPwrSt "Mch.ACCU.ACRM.HvacPwrSt";
BA_ "VssSig" SG_ 2566875929 WindDirDefIndSt "Mch.ACCU.ACRM.WindDirDefIndSt";
BA_ "VssSig" SG_ 2566875929 WindDirFloorIndSt "Mch.ACCU.ACRM.WindDirFloorIndSt";
BA_ "VssSig" SG_ 2566875929 WindDirRrIndSt "Mch.ACCU.ACRM.WindDirRrIndSt";
BA_ "VssSig" SG_ 2566875929 WindDirFrIndSt "Mch.ACCU.ACRM.WindDirFrIndSt";
BA_ "VssSig" SG_ 2566875929 DefMdSt "Mch.ACCU.ACRM.DefMdSt";
BA_ "VssSig" SG_ 2566875929 OutInMdSel "Mch.ACCU.ACRM.OutInMdSel";
BA_ "VssSig" SG_ 2566875929 AcMdSt "Mch.ACCU.ACRM.AcMdSt";
BA_ "VssSig" SG_ 2566875929 MnAutoMdSt "Mch.ACCU.ACRM.MnAutoMdSt";
BA_ "VssSig" SG_ 2566876961 LowOutReq8 "Mch.MCU.ACUCTR2.LowOutReq8";
BA_ "VssSig" SG_ 2566876961 LowOutReq7 "Mch.MCU.ACUCTR2.LowOutReq7";
BA_ "VssSig" SG_ 2566876961 LowOutReq6 "Mch.MCU.ACUCTR2.LowOutReq6";
BA_ "VssSig" SG_ 2566876961 LowOutReq5 "Mch.MCU.ACUCTR2.LowOutReq5";
BA_ "VssSig" SG_ 2566876961 LowOutReq4 "Mch.MCU.ACUCTR2.LowOutReq4";
BA_ "VssSig" SG_ 2566876961 LowOutReq3 "Mch.MCU.ACUCTR2.LowOutReq3";
BA_ "VssSig" SG_ 2566876961 LowOutReq2 "Mch.MCU.ACUCTR2.LowOutReq2";
BA_ "VssSig" SG_ 2566876961 LowOutReq1 "Mch.MCU.ACUCTR2.LowOutReq1";
BA_ "VssSig" SG_ 2566876961 OutReq15 "Mch.MCU.ACUCTR2.OutReq15";
BA_ "VssSig" SG_ 2566876961 OutReq14 "Mch.MCU.ACUCTR2.OutReq14";
BA_ "VssSig" SG_ 2566876961 OutReq13 "Mch.MCU.ACUCTR2.OutReq13";
BA_ "VssSig" SG_ 2566876961 OutReq12 "Mch.MCU.ACUCTR2.OutReq12";
BA_ "VssSig" SG_ 2566876961 OutReq11 "Mch.MCU.ACUCTR2.OutReq11";
BA_ "VssSig" SG_ 2566876961 OutReq10 "Mch.MCU.ACUCTR2.OutReq10";
BA_ "VssSig" SG_ 2566876961 OutReq9 "Mch.MCU.ACUCTR2.OutReq9";
BA_ "VssSig" SG_ 2566876961 OutReq8 "Mch.MCU.ACUCTR2.OutReq8";
BA_ "VssSig" SG_ 2566876961 OutReq7 "Mch.MCU.ACUCTR2.OutReq7";
BA_ "VssSig" SG_ 2566876961 OutReq6 "Mch.MCU.ACUCTR2.OutReq6";
BA_ "VssSig" SG_ 2566876961 OutReq5 "Mch.MCU.ACUCTR2.OutReq5";
BA_ "VssSig" SG_ 2566876961 OutReq4 "Mch.MCU.ACUCTR2.OutReq4";
BA_ "VssSig" SG_ 2566876961 OutReq3 "Mch.MCU.ACUCTR2.OutReq3";
BA_ "VssSig" SG_ 2566876961 OutReq2 "Mch.MCU.ACUCTR2.OutReq2";
BA_ "VssSig" SG_ 2566876961 OutReq1 "Mch.MCU.ACUCTR2.OutReq1";
BA_ "VssSig" SG_ 2566877770 Offset "Mch.TGU.TMSGPSI.Offset";
BA_ "VssSig" SG_ 2566877770 St "Mch.TGU.TMSGPSI.St";
BA_ "VssSig" SG_ 2566877770 GpsSatNo "Mch.TGU.TMSGPSI.GpsSatNo";
BA_ "VssSig" SG_ 2566877770 Spd "Mch.TGU.TMSGPSI.Spd";
BA_ "VssSig" SG_ 2566877770 Z "Mch.TGU.TMSGPSI.Z";
BA_ "VssSig" SG_ 2566877770 Y "Mch.TGU.TMSGPSI.Y";
BA_ "VssSig" SG_ 2566877770 X "Mch.TGU.TMSGPSI.X";
BA_ "VssSig" SG_ 2566878794 WifiAntSt "Mch.TGU.TSEC.WifiAntSt";
BA_ "VssSig" SG_ 2566878794 SatAntSt "Mch.TGU.TSEC.SatAntSt";
BA_ "VssSig" SG_ 2566878794 CellAntSt "Mch.TGU.TSEC.CellAntSt";
BA_ "VssSig" SG_ 2566878794 GpsAntSt "Mch.TGU.TSEC.GpsAntSt";
BA_ "VssSig" SG_ 2566878794 ScrtyCmd "Mch.TGU.TSEC.ScrtyCmd";
BA_ "VssSig" SG_ 2566879272 Sha1Hash "Mch.GP.TMSTP.Sha1Hash";
BA_ "VssSig" SG_ 2566879306 Sha1Hash "Mch.TGU.TMSTP.Sha1Hash";
BA_ "VssSig" SG_ 2566879562 Cd "Mch.TGU.TMSLURT.Cd";
BA_ "VssSig" SG_ 2566879818 Dkey "Mch.TGU.DKLI.Dkey";
BA_ "VssSig" SG_ 2566879818 KeyType "Mch.TGU.DKLI.KeyType";
BA_ "VssSig" SG_ 2566879818 LogIn "Mch.TGU.DKLI.LogIn";
BA_ "VssSig" SG_ 2566880074 DkeyList "Mch.TGU.DKLD.DkeyList";
BA_ "VssSig" SG_ 2566880074 Cnt "Mch.TGU.DKLD.Cnt";
BA_ "VssSig" SG_ 2566880330 DigitalKey "Mch.TGU.DKSEL.DigitalKey";
BA_ "VssSig" SG_ 2566880330 SelType "Mch.TGU.DKSEL.SelType";
BA_ "VssSig" SG_ 2566880842 TmsPmntUnlockCd "Mch.TGU.TMSPUC.TmsPmntUnlockCd";
BA_ "VssSig" SG_ 2566881064 TmsStInfo2 "Mch.GP.TMSPP.TmsStInfo2";
BA_ "VssSig" SG_ 2566881064 TmsStInfo1 "Mch.GP.TMSPP.TmsStInfo1";
BA_ "VssSig" SG_ 2566881064 TmsPmntPw "Mch.GP.TMSPP.TmsPmntPw";
BA_ "VssSig" SG_ 2566881098 TmsStInfo2 "Mch.TGU.TMSPP.TmsStInfo2";
BA_ "VssSig" SG_ 2566881098 TmsStInfo1 "Mch.TGU.TMSPP.TmsStInfo1";
BA_ "VssSig" SG_ 2566881098 TmsPmntPw "Mch.TGU.TMSPP.TmsPmntPw";
BA_ "VssSig" SG_ 2566883328 EmsObdIndFail "Mch.ECU.SCR2.EmsObdIndFail";
BA_ "VssSig" SG_ 2566883328 UreaLvAlm "Mch.ECU.SCR2.UreaLvAlm";
BA_ "VssSig" SG_ 2566883328 Scr2RegInfo "Mch.ECU.SCR2.Scr2RegInfo";
BA_ "VssSig" SG_ 2566883328 EmsObdIndSt "Mch.ECU.SCR2.EmsObdIndSt";
BA_ "VssSig" SG_ 2566883328 UreaLvBzSt "Mch.ECU.SCR2.UreaLvBzSt";
BA_ "VssSig" SG_ 2566883873 AltVlt "Mch.MCU.AASI.AltVlt";
BA_ "VssSig" SG_ 2566883873 Rr2BrkSsPrs "Mch.MCU.AASI.Rr2BrkSsPrs";
BA_ "VssSig" SG_ 2566883873 BoomCylRodSsPrs "Mch.MCU.AASI.BoomCylRodSsPrs";
BA_ "VssSig" SG_ 2566883873 BoomCylHeadSsPrs "Mch.MCU.AASI.BoomCylHeadSsPrs";
BA_ "VssSig" SG_ 2566883873 CtrPinAngSs1Vlt "Mch.MCU.AASI.CtrPinAngSs1Vlt";
BA_ "VssSig" SG_ 2566883873 AccPdlSs2Vlt "Mch.MCU.AASI.AccPdlSs2Vlt";
BA_ "VssSig" SG_ 2566883873 DumpBedAngSs2Vlt "Mch.MCU.AASI.DumpBedAngSs2Vlt";
BA_ "VssSig" SG_ 2566883873 DumpBedAngSs1Vlt "Mch.MCU.AASI.DumpBedAngSs1Vlt";
BA_ "VssSig" SG_ 2566883873 BrkInchPdlSs1Vlt "Mch.MCU.AASI.BrkInchPdlSs1Vlt";
BA_ "VssSig" SG_ 2566883873 TipJoySs1Vlt "Mch.MCU.AASI.TipJoySs1Vlt";
BA_ "VssSig" SG_ 2566883873 RhCylSsPrs "Mch.MCU.AASI.RhCylSsPrs";
BA_ "VssSig" SG_ 2566883873 EmgStrSsPrs "Mch.MCU.AASI.EmgStrSsPrs";
BA_ "VssSig" SG_ 2566883873 AxleOilSsTmp "Mch.MCU.AASI.AxleOilSsTmp";
BA_ "VssSig" SG_ 2566883873 FuelSsLv "Mch.MCU.AASI.FuelSsLv";
BA_ "VssSig" SG_ 2566883873 Rr1BrkSsPrs "Mch.MCU.AASI.Rr1BrkSsPrs";
BA_ "VssSig" SG_ 2566883873 FrBrkSsPrs "Mch.MCU.AASI.FrBrkSsPrs";
BA_ "VssSig" SG_ 2566883873 AccPdlSs1Vlt "Mch.MCU.AASI.AccPdlSs1Vlt";
BA_ "VssSig" SG_ 2566883873 CtrPinAngSs2Vlt "Mch.MCU.AASI.CtrPinAngSs2Vlt";
BA_ "VssSig" SG_ 2566883873 TmsSecVlt "Mch.MCU.AASI.TmsSecVlt";
BA_ "VssSig" SG_ 2566883873 LhCylSsPrs "Mch.MCU.AASI.LhCylSsPrs";
BA_ "VssSig" SG_ 2566883873 Acc3SsPrs "Mch.MCU.AASI.Acc3SsPrs";
BA_ "VssSig" SG_ 2566883873 BrkInchPdlSs2Vlt "Mch.MCU.AASI.BrkInchPdlSs2Vlt";
BA_ "VssSig" SG_ 2566883873 CacFanSsPrs "Mch.MCU.AASI.CacFanSsPrs";
BA_ "VssSig" SG_ 2566883873 Acc2SsPrs "Mch.MCU.AASI.Acc2SsPrs";
BA_ "VssSig" SG_ 2566883873 TipJoySs2Vlt "Mch.MCU.AASI.TipJoySs2Vlt";
BA_ "VssSig" SG_ 2566883873 TocFanSsPrs "Mch.MCU.AASI.TocFanSsPrs";
BA_ "VssSig" SG_ 2566883873 Acc1SsPrs "Mch.MCU.AASI.Acc1SsPrs";
BA_ "VssSig" SG_ 2566883873 PrkBrkSsPrs "Mch.MCU.AASI.PrkBrkSsPrs";
BA_ "VssSig" SG_ 2566883873 MainSsPrs "Mch.MCU.AASI.MainSsPrs";
BA_ "VssSig" SG_ 2566883873 WifSsVlt "Mch.MCU.AASI.WifSsVlt";
BA_ "VssSig" SG_ 2566883873 HydOilSsTmp "Mch.MCU.AASI.HydOilSsTmp";
BA_ "VssSig" SG_ 2566884129 FanDrvTocEvc "Mch.MCU.AAAI.FanDrvTocEvc";
BA_ "VssSig" SG_ 2566884129 eFan2DutyRatio "Mch.MCU.AAAI.eFan2DutyRatio";
BA_ "VssSig" SG_ 2566884129 eFan3DutyRatio "Mch.MCU.AAAI.eFan3DutyRatio";
BA_ "VssSig" SG_ 2566884129 eBrkEvc "Mch.MCU.AAAI.eBrkEvc";
BA_ "VssSig" SG_ 2566884129 eFan1DutyRatio "Mch.MCU.AAAI.eFan1DutyRatio";
BA_ "VssSig" SG_ 2566884129 FanDrvRadCacEvc "Mch.MCU.AAAI.FanDrvRadCacEvc";
BA_ "VssSig" SG_ 2566884129 BodyDnEvc "Mch.MCU.AAAI.BodyDnEvc";
BA_ "VssSig" SG_ 2566884129 BodyUpEvc "Mch.MCU.AAAI.BodyUpEvc";
BA_ "VssSig" SG_ 2566884385 StartCrkSw "Mch.MCU.ADSI.StartCrkSw";
BA_ "VssSig" SG_ 2566884385 GrSelSw "Mch.MCU.ADSI.GrSelSw";
BA_ "VssSig" SG_ 2566884385 GrSelNtrlSw "Mch.MCU.ADSI.GrSelNtrlSw";
BA_ "VssSig" SG_ 2566884385 PrkSw "Mch.MCU.ADSI.PrkSw";
BA_ "VssSig" SG_ 2566884385 GrSelRvsSw "Mch.MCU.ADSI.GrSelRvsSw";
BA_ "VssSig" SG_ 2566884385 GrSelShftDnSw "Mch.MCU.ADSI.GrSelShftDnSw";
BA_ "VssSig" SG_ 2566884385 GrSelShftUpSw "Mch.MCU.ADSI.GrSelShftUpSw";
BA_ "VssSig" SG_ 2566884385 GrSelFwdSw "Mch.MCU.ADSI.GrSelFwdSw";
BA_ "VssSig" SG_ 2566884385 DustIndSw "Mch.MCU.ADSI.DustIndSw";
BA_ "VssSig" SG_ 2566884385 StartAccSw "Mch.MCU.ADSI.StartAccSw";
BA_ "VssSig" SG_ 2566884385 AtsForceRgnSw "Mch.MCU.ADSI.AtsForceRgnSw";
BA_ "VssSig" SG_ 2566884385 AtsRgnIhbsw "Mch.MCU.ADSI.AtsRgnIhbsw";
BA_ "VssSig" SG_ 2566884385 eFan3ErrSt "Mch.MCU.ADSI.eFan3ErrSt";
BA_ "VssSig" SG_ 2566884385 KeyBrSw "Mch.MCU.ADSI.KeyBrSw";
BA_ "VssSig" SG_ 2566884385 TipJoySw "Mch.MCU.ADSI.TipJoySw";
BA_ "VssSig" SG_ 2566884385 AgsSw "Mch.MCU.ADSI.AgsSw";
BA_ "VssSig" SG_ 2566884385 eFan2ErrSt "Mch.MCU.ADSI.eFan2ErrSt";
BA_ "VssSig" SG_ 2566884385 eFan1ErrSt "Mch.MCU.ADSI.eFan1ErrSt";
BA_ "VssSig" SG_ 2566884385 SeatBeltSt "Mch.MCU.ADSI.SeatBeltSt";
BA_ "VssSig" SG_ 2566884385 FrWiperStpSw "Mch.MCU.ADSI.FrWiperStpSw";
BA_ "VssSig" SG_ 2566884641 SusRhDn "Mch.MCU.ADAI.SusRhDn";
BA_ "VssSig" SG_ 2566884641 TocRvs "Mch.MCU.ADAI.TocRvs";
BA_ "VssSig" SG_ 2566884641 TurnSigRhRly "Mch.MCU.ADAI.TurnSigRhRly";
BA_ "VssSig" SG_ 2566884641 TurnSigLhRly "Mch.MCU.ADAI.TurnSigLhRly";
BA_ "VssSig" SG_ 2566884641 SusRhUp "Mch.MCU.ADAI.SusRhUp";
BA_ "VssSig" SG_ 2566884641 EgRunOutSig "Mch.MCU.ADAI.EgRunOutSig";
BA_ "VssSig" SG_ 2566884641 SusLhDn "Mch.MCU.ADAI.SusLhDn";
BA_ "VssSig" SG_ 2566884641 UreaSuperChgWrnSig "Mch.MCU.ADAI.UreaSuperChgWrnSig";
BA_ "VssSig" SG_ 2566884641 FanStpSv "Mch.MCU.ADAI.FanStpSv";
BA_ "VssSig" SG_ 2566884641 Dhl3Sig "Mch.MCU.ADAI.Dhl3Sig";
BA_ "VssSig" SG_ 2566884641 Dhl2Sig "Mch.MCU.ADAI.Dhl2Sig";
BA_ "VssSig" SG_ 2566884641 SusLhUp "Mch.MCU.ADAI.SusLhUp";
BA_ "VssSig" SG_ 2566884641 PrkBrkRlsSv "Mch.MCU.ADAI.PrkBrkRlsSv";
BA_ "VssSig" SG_ 2566884641 AxleOilCoolSv "Mch.MCU.ADAI.AxleOilCoolSv";
BA_ "VssSig" SG_ 2566884641 TocUnloading "Mch.MCU.ADAI.TocUnloading";
BA_ "VssSig" SG_ 2566884641 AccRly "Mch.MCU.ADAI.AccRly";
BA_ "VssSig" SG_ 2566884641 RrWinHtRly "Mch.MCU.ADAI.RrWinHtRly";
BA_ "VssSig" SG_ 2566884641 LiftArmFlt "Mch.MCU.ADAI.LiftArmFlt";
BA_ "VssSig" SG_ 2566884641 AutoShutOffRly "Mch.MCU.ADAI.AutoShutOffRly";
BA_ "VssSig" SG_ 2566884641 BrkChgSv "Mch.MCU.ADAI.BrkChgSv";
BA_ "VssSig" SG_ 2566884641 Dhl1Sig "Mch.MCU.ADAI.Dhl1Sig";
BA_ "VssSig" SG_ 2566884897 RrRhTirePrs "Mch.MCU.TIG1.RrRhTirePrs";
BA_ "VssSig" SG_ 2566884897 RrLhTirePrs "Mch.MCU.TIG1.RrLhTirePrs";
BA_ "VssSig" SG_ 2566884897 CtrRhTirePrs "Mch.MCU.TIG1.CtrRhTirePrs";
BA_ "VssSig" SG_ 2566884897 CtrLhTirePrs "Mch.MCU.TIG1.CtrLhTirePrs";
BA_ "VssSig" SG_ 2566884897 FronRhTirePrs "Mch.MCU.TIG1.FronRhTirePrs";
BA_ "VssSig" SG_ 2566884897 FrLhTirePrs "Mch.MCU.TIG1.FrLhTirePrs";
BA_ "VssSig" SG_ 2566885153 RrRhTireTmp "Mch.MCU.TIG2.RrRhTireTmp";
BA_ "VssSig" SG_ 2566885153 RrLhTireTmp "Mch.MCU.TIG2.RrLhTireTmp";
BA_ "VssSig" SG_ 2566885153 CtrRhTireTmp "Mch.MCU.TIG2.CtrRhTireTmp";
BA_ "VssSig" SG_ 2566885153 CtrLhTireTmp "Mch.MCU.TIG2.CtrLhTireTmp";
BA_ "VssSig" SG_ 2566885153 FronRhTireTmp "Mch.MCU.TIG2.FronRhTireTmp";
BA_ "VssSig" SG_ 2566885153 FrLhTireTmp "Mch.MCU.TIG2.FrLhTireTmp";
BA_ "VssSig" SG_ 2566885409 PartNo "Mch.MCU.QRCI.PartNo";
BA_ "VssSig" SG_ 2566885409 SerialNo "Mch.MCU.QRCI.SerialNo";
BA_ "VssSig" SG_ 2566885409 MnftCode "Mch.MCU.QRCI.MnftCode";
BA_ "VssSig" SG_ 2566885409 ComCode "Mch.MCU.QRCI.ComCode";
BA_ "VssSig" SG_ 2566885409 Year "Mch.MCU.QRCI.Year";
BA_ "VssSig" SG_ 2566885409 Day "Mch.MCU.QRCI.Day";
BA_ "VssSig" SG_ 2566885409 Month "Mch.MCU.QRCI.Month";
BA_ "VssSig" SG_ 2566885409 VcuSwVer "Mch.MCU.QRCI.VcuSwVer";
BA_ "VssSig" SG_ 2566885665 TotAvgReliefOprPct "Mch.MCU.ECORI.TotAvgReliefOprPct";
BA_ "VssSig" SG_ 2566885665 TotAvgLwIdleOprPct "Mch.MCU.ECORI.TotAvgLwIdleOprPct";
BA_ "VssSig" SG_ 2566885665 TotAvgHhIdleOprPct "Mch.MCU.ECORI.TotAvgHhIdleOprPct";
BA_ "VssSig" SG_ 2566885665 Day7ReliefOprPct "Mch.MCU.ECORI.Day7ReliefOprPct";
BA_ "VssSig" SG_ 2566885665 Day7LwIdleOprPct "Mch.MCU.ECORI.Day7LwIdleOprPct";
BA_ "VssSig" SG_ 2566885665 Day7HhIdleOprPct "Mch.MCU.ECORI.Day7HhIdleOprPct";
BA_ "VssSig" SG_ 2566885665 Day6ReliefOprPct "Mch.MCU.ECORI.Day6ReliefOprPct";
BA_ "VssSig" SG_ 2566885665 Day6LwIdleOprPct "Mch.MCU.ECORI.Day6LwIdleOprPct";
BA_ "VssSig" SG_ 2566885665 Day6HhIdleOprPct "Mch.MCU.ECORI.Day6HhIdleOprPct";
BA_ "VssSig" SG_ 2566885665 Day5ReliefOprPct "Mch.MCU.ECORI.Day5ReliefOprPct";
BA_ "VssSig" SG_ 2566885665 Day5LwIdleOprPct "Mch.MCU.ECORI.Day5LwIdleOprPct";
BA_ "VssSig" SG_ 2566885665 Day5HhIdleOprPct "Mch.MCU.ECORI.Day5HhIdleOprPct";
BA_ "VssSig" SG_ 2566885665 Day4ReliefOprPct "Mch.MCU.ECORI.Day4ReliefOprPct";
BA_ "VssSig" SG_ 2566885665 Day4LwIdleOprPct "Mch.MCU.ECORI.Day4LwIdleOprPct";
BA_ "VssSig" SG_ 2566885665 Day4HhIdleOprPct "Mch.MCU.ECORI.Day4HhIdleOprPct";
BA_ "VssSig" SG_ 2566885665 Day3ReliefOprPct "Mch.MCU.ECORI.Day3ReliefOprPct";
BA_ "VssSig" SG_ 2566885665 Day3LwIdleOprPct "Mch.MCU.ECORI.Day3LwIdleOprPct";
BA_ "VssSig" SG_ 2566885665 Day3HhIdleOprPct "Mch.MCU.ECORI.Day3HhIdleOprPct";
BA_ "VssSig" SG_ 2566885665 Day2ReliefOprPct "Mch.MCU.ECORI.Day2ReliefOprPct";
BA_ "VssSig" SG_ 2566885665 Day2LwIdleOprPct "Mch.MCU.ECORI.Day2LwIdleOprPct";
BA_ "VssSig" SG_ 2566885665 Day2HhIdleOprPct "Mch.MCU.ECORI.Day2HhIdleOprPct";
BA_ "VssSig" SG_ 2566885665 Day1ReliefOprPct "Mch.MCU.ECORI.Day1ReliefOprPct";
BA_ "VssSig" SG_ 2566885665 Day1LwIdleOprPct "Mch.MCU.ECORI.Day1LwIdleOprPct";
BA_ "VssSig" SG_ 2566885665 Day1HhIdleOprPct "Mch.MCU.ECORI.Day1HhIdleOprPct";
BA_ "VssSig" SG_ 2566885665 NowReliefOprLv "Mch.MCU.ECORI.NowReliefOprLv";
BA_ "VssSig" SG_ 2566885665 NowLwIdleOprLv "Mch.MCU.ECORI.NowLwIdleOprLv";
BA_ "VssSig" SG_ 2566885665 NowHhIdleOprLv "Mch.MCU.ECORI.NowHhIdleOprLv";
BA_ "VssSig" SG_ 2566885665 NowReliefOprPct "Mch.MCU.ECORI.NowReliefOprPct";
BA_ "VssSig" SG_ 2566885665 NowLwIdleOprPct "Mch.MCU.ECORI.NowLwIdleOprPct";
BA_ "VssSig" SG_ 2566885665 NowHhIdleOprPct "Mch.MCU.ECORI.NowHhIdleOprPct";
BA_ "VssSig" SG_ 2566886952 RrVwPriMd "Mch.GP.AVMVM.RrVwPriMd";
BA_ "VssSig" SG_ 2566886952 VwMd "Mch.GP.AVMVM.VwMd";
BA_ "VssSig" SG_ 2566887223 RrVwPriMd "Mch.AVM.AVMSI.RrVwPriMd";
BA_ "VssSig" SG_ 2566887223 AvmWrnGud "Mch.AVM.AVMSI.AvmWrnGud";
BA_ "VssSig" SG_ 2566887223 AvmSt "Mch.AVM.AVMSI.AvmSt";
BA_ "VssSig" SG_ 2566887223 AvmUltraBz "Mch.AVM.AVMSI.AvmUltraBz";
BA_ "VssSig" SG_ 2566887223 AvmTonSize "Mch.AVM.AVMSI.AvmTonSize";
BA_ "VssSig" SG_ 2566887223 AvmDisplayMsg "Mch.AVM.AVMSI.AvmDisplayMsg";
BA_ "VssSig" SG_ 2566887223 AvmOutType "Mch.AVM.AVMSI.AvmOutType";
BA_ "VssSig" SG_ 2566887223 AvmVw "Mch.AVM.AVMSI.AvmVw";
BA_ "VssSig" SG_ 2566887223 AvmLanguagePack "Mch.AVM.AVMSI.AvmLanguagePack";
BA_ "VssSig" SG_ 2566887479 UltsSigL6 "Mch.AVM.AVMUS.UltsSigL6";
BA_ "VssSig" SG_ 2566887479 UltsSigR6 "Mch.AVM.AVMUS.UltsSigR6";
BA_ "VssSig" SG_ 2566887479 UltsSigL5 "Mch.AVM.AVMUS.UltsSigL5";
BA_ "VssSig" SG_ 2566887479 UltsSigR5 "Mch.AVM.AVMUS.UltsSigR5";
BA_ "VssSig" SG_ 2566887479 UltsSigL4 "Mch.AVM.AVMUS.UltsSigL4";
BA_ "VssSig" SG_ 2566887479 UltsSigR4 "Mch.AVM.AVMUS.UltsSigR4";
BA_ "VssSig" SG_ 2566887479 UltsSigL3 "Mch.AVM.AVMUS.UltsSigL3";
BA_ "VssSig" SG_ 2566887479 UltsSigR3 "Mch.AVM.AVMUS.UltsSigR3";
BA_ "VssSig" SG_ 2566887479 UltsSigL2 "Mch.AVM.AVMUS.UltsSigL2";
BA_ "VssSig" SG_ 2566887479 UltsSigR2 "Mch.AVM.AVMUS.UltsSigR2";
BA_ "VssSig" SG_ 2566887479 UltsSigL1 "Mch.AVM.AVMUS.UltsSigL1";
BA_ "VssSig" SG_ 2566887479 UltsSigR1 "Mch.AVM.AVMUS.UltsSigR1";
BA_ "VssSig" SG_ 2566887720 CamPrmtCorCompleteSt "Mch.GP.AVMRM.CamPrmtCorCompleteSt";
BA_ "VssSig" SG_ 2566887720 CamPrmtVerMsb "Mch.GP.AVMRM.CamPrmtVerMsb";
BA_ "VssSig" SG_ 2566887720 CamPrmtVerLsb "Mch.GP.AVMRM.CamPrmtVerLsb";
BA_ "VssSig" SG_ 2566887720 Language "Mch.GP.AVMRM.Language";
BA_ "VssSig" SG_ 2566887720 ToleranceCorMenuentryCmd "Mch.GP.AVMRM.ToleranceCorMenuentryCmd";
BA_ "VssSig" SG_ 2566887720 WrnGudSetCmd "Mch.GP.AVMRM.WrnGudSetCmd";
BA_ "VssSig" SG_ 2566887720 UltsSs08Cmd "Mch.GP.AVMRM.UltsSs08Cmd";
BA_ "VssSig" SG_ 2566887720 UltsSs07Cmd "Mch.GP.AVMRM.UltsSs07Cmd";
BA_ "VssSig" SG_ 2566887720 UltsSs06Cmd "Mch.GP.AVMRM.UltsSs06Cmd";
BA_ "VssSig" SG_ 2566887720 UltsSs05Cmd "Mch.GP.AVMRM.UltsSs05Cmd";
BA_ "VssSig" SG_ 2566887720 UltsSs04Cmd "Mch.GP.AVMRM.UltsSs04Cmd";
BA_ "VssSig" SG_ 2566887720 UltsSs03Cmd "Mch.GP.AVMRM.UltsSs03Cmd";
BA_ "VssSig" SG_ 2566887720 UltsSs02Cmd "Mch.GP.AVMRM.UltsSs02Cmd";
BA_ "VssSig" SG_ 2566887720 UltsSs01Cmd "Mch.GP.AVMRM.UltsSs01Cmd";
BA_ "VssSig" SG_ 2566887720 UltsSs12Cmd "Mch.GP.AVMRM.UltsSs12Cmd";
BA_ "VssSig" SG_ 2566887720 UltsSs11Cmd "Mch.GP.AVMRM.UltsSs11Cmd";
BA_ "VssSig" SG_ 2566887720 UltsSs10Cmd "Mch.GP.AVMRM.UltsSs10Cmd";
BA_ "VssSig" SG_ 2566887720 UltsSs09Cmd "Mch.GP.AVMRM.UltsSs09Cmd";
BA_ "VssSig" SG_ 2566887720 SetApplicationCmd "Mch.GP.AVMRM.SetApplicationCmd";
BA_ "VssSig" SG_ 2566887720 ToleranceCorCmd "Mch.GP.AVMRM.ToleranceCorCmd";
BA_ "VssSig" SG_ 2566887720 FactoryReCmd "Mch.GP.AVMRM.FactoryReCmd";
BA_ "VssSig" SG_ 2566887720 UltsSsOpt "Mch.GP.AVMRM.UltsSsOpt";
BA_ "VssSig" SG_ 2566887720 UltsBuzzerStopSig "Mch.GP.AVMRM.UltsBuzzerStopSig";
BA_ "VssSig" SG_ 2566887720 BoomCamOpt "Mch.GP.AVMRM.BoomCamOpt";
BA_ "VssSig" SG_ 2566887720 UltsBzOffSig "Mch.GP.AVMRM.UltsBzOffSig";
BA_ "VssSig" SG_ 2566887720 UltsRecognitionDistanceSet "Mch.GP.AVMRM.UltsRecognitionDistanceSet";
BA_ "VssSig" SG_ 2566887720 VhcType2 "Mch.GP.AVMRM.VhcType2";
BA_ "VssSig" SG_ 2566887720 VhcType1 "Mch.GP.AVMRM.VhcType1";
BA_ "VssSig" SG_ 2566887720 TonsOftheTensDigit "Mch.GP.AVMRM.TonsOftheTensDigit";
BA_ "VssSig" SG_ 2566887720 TonsOftheUnitsDigit "Mch.GP.AVMRM.TonsOftheUnitsDigit";
BA_ "VssSig" SG_ 2566887720 FactoryType "Mch.GP.AVMRM.FactoryType";
BA_ "VssSig" SG_ 2566887720 VwMd "Mch.GP.AVMRM.VwMd";
BA_ "VssSig" SG_ 2566887991 CamPrmtCorCompleteSt "Mch.AVM.AVMSM.CamPrmtCorCompleteSt";
BA_ "VssSig" SG_ 2566887991 CamPrmtVerMsb "Mch.AVM.AVMSM.CamPrmtVerMsb";
BA_ "VssSig" SG_ 2566887991 CamPrmtVerLsb "Mch.AVM.AVMSM.CamPrmtVerLsb";
BA_ "VssSig" SG_ 2566887991 Language "Mch.AVM.AVMSM.Language";
BA_ "VssSig" SG_ 2566887991 ToleranceCorMenuentryCmd "Mch.AVM.AVMSM.ToleranceCorMenuentryCmd";
BA_ "VssSig" SG_ 2566887991 WrnGudSetCmd "Mch.AVM.AVMSM.WrnGudSetCmd";
BA_ "VssSig" SG_ 2566887991 UltsSs08Cmd "Mch.AVM.AVMSM.UltsSs08Cmd";
BA_ "VssSig" SG_ 2566887991 UltsSs07Cmd "Mch.AVM.AVMSM.UltsSs07Cmd";
BA_ "VssSig" SG_ 2566887991 UltsSs06Cmd "Mch.AVM.AVMSM.UltsSs06Cmd";
BA_ "VssSig" SG_ 2566887991 UltsSs05Cmd "Mch.AVM.AVMSM.UltsSs05Cmd";
BA_ "VssSig" SG_ 2566887991 UltsSs04Cmd "Mch.AVM.AVMSM.UltsSs04Cmd";
BA_ "VssSig" SG_ 2566887991 UltsSs03Cmd "Mch.AVM.AVMSM.UltsSs03Cmd";
BA_ "VssSig" SG_ 2566887991 UltsSs02Cmd "Mch.AVM.AVMSM.UltsSs02Cmd";
BA_ "VssSig" SG_ 2566887991 UltsSs01Cmd "Mch.AVM.AVMSM.UltsSs01Cmd";
BA_ "VssSig" SG_ 2566887991 UltsSs12Cmd "Mch.AVM.AVMSM.UltsSs12Cmd";
BA_ "VssSig" SG_ 2566887991 UltsSs11Cmd "Mch.AVM.AVMSM.UltsSs11Cmd";
BA_ "VssSig" SG_ 2566887991 UltsSs10Cmd "Mch.AVM.AVMSM.UltsSs10Cmd";
BA_ "VssSig" SG_ 2566887991 UltsSs09Cmd "Mch.AVM.AVMSM.UltsSs09Cmd";
BA_ "VssSig" SG_ 2566887991 SetAppCmd "Mch.AVM.AVMSM.SetAppCmd";
BA_ "VssSig" SG_ 2566887991 ToleranceCorCmd "Mch.AVM.AVMSM.ToleranceCorCmd";
BA_ "VssSig" SG_ 2566887991 FactoryResetCmd "Mch.AVM.AVMSM.FactoryResetCmd";
BA_ "VssSig" SG_ 2566887991 UltsSsOpt "Mch.AVM.AVMSM.UltsSsOpt";
BA_ "VssSig" SG_ 2566887991 UltsBzStopSig "Mch.AVM.AVMSM.UltsBzStopSig";
BA_ "VssSig" SG_ 2566887991 BoomCamOpt "Mch.AVM.AVMSM.BoomCamOpt";
BA_ "VssSig" SG_ 2566887991 UltsBzOffSig "Mch.AVM.AVMSM.UltsBzOffSig";
BA_ "VssSig" SG_ 2566887991 UltsRecognitionDistanceSet "Mch.AVM.AVMSM.UltsRecognitionDistanceSet";
BA_ "VssSig" SG_ 2566887991 VhcType2 "Mch.AVM.AVMSM.VhcType2";
BA_ "VssSig" SG_ 2566887991 VhcType1 "Mch.AVM.AVMSM.VhcType1";
BA_ "VssSig" SG_ 2566887991 TonsOftheTensDigit "Mch.AVM.AVMSM.TonsOftheTensDigit";
BA_ "VssSig" SG_ 2566887991 TonsOftheUnitsDigit "Mch.AVM.AVMSM.TonsOftheUnitsDigit";
BA_ "VssSig" SG_ 2566887991 FactoryType "Mch.AVM.AVMSM.FactoryType";
BA_ "VssSig" SG_ 2566887991 VwMd "Mch.AVM.AVMSM.VwMd";
BA_ "VssSig" SG_ 2566888503 AvmCamPrmt4 "Mch.AVM.AVMCP.AvmCamPrmt4";
BA_ "VssSig" SG_ 2566888503 AvmCamPrmt3 "Mch.AVM.AVMCP.AvmCamPrmt3";
BA_ "VssSig" SG_ 2566888503 AvmCamPrmt2 "Mch.AVM.AVMCP.AvmCamPrmt2";
BA_ "VssSig" SG_ 2566888503 AvmCamPrmt1 "Mch.AVM.AVMCP.AvmCamPrmt1";
BA_ "VssSig" SG_ 2566888759 AvmVerYear "Mch.AVM.AVMVER.AvmVerYear";
BA_ "VssSig" SG_ 2566888759 AvmVerMonth "Mch.AVM.AVMVER.AvmVerMonth";
BA_ "VssSig" SG_ 2566888759 AvmVerDate "Mch.AVM.AVMVER.AvmVerDate";
BA_ "VssSig" SG_ 2566888759 AvmVer "Mch.AVM.AVMVER.AvmVer";
BA_ "VssSig" SG_ 2566889512 EvMdCmd "Mch.GP.GPCMD.EvMdCmd";
BA_ "VssSig" SG_ 2566889512 ObjectSsChmsl "Mch.GP.GPCMD.ObjectSsChmsl";
BA_ "VssSig" SG_ 2566889512 KeylessCrankEnbSt "Mch.GP.GPCMD.KeylessCrankEnbSt";
BA_ "VssSig" SG_ 2566889512 DaacmdSt "Mch.GP.GPCMD.DaacmdSt";
BA_ "VssSig" SG_ 2566889512 QuickCoolMdSt "Mch.GP.GPCMD.QuickCoolMdSt";
BA_ "VssSig" SG_ 2566889512 DzAstMdSt "Mch.GP.GPCMD.DzAstMdSt";
BA_ "VssSig" SG_ 2566889512 KeyPadPri "Mch.GP.GPCMD.KeyPadPri";
BA_ "VssSig" SG_ 2566889512 RpmCmdbyJD "Mch.GP.GPCMD.RpmCmdbyJD";
BA_ "VssSig" SG_ 2566889512 TractionMdSt "Mch.GP.GPCMD.TractionMdSt";
BA_ "VssSig" SG_ 2566889512 ExternalSoundCmd "Mch.GP.GPCMD.ExternalSoundCmd";
BA_ "VssSig" SG_ 2566889512 EgLckSt "Mch.GP.GPCMD.EgLckSt";
BA_ "VssSig" SG_ 2566889512 JduseStforRpm "Mch.GP.GPCMD.JduseStforRpm";
BA_ "VssSig" SG_ 2566889512 AutoIdleMdSt "Mch.GP.GPCMD.AutoIdleMdSt";
BA_ "VssSig" SG_ 2566889512 WrkMdSt "Mch.GP.GPCMD.WrkMdSt";
BA_ "VssSig" SG_ 2566889512 PwrMdSt "Mch.GP.GPCMD.PwrMdSt";
BA_ "VssSig" SG_ 2566889768 LocalHrOfs "Mch.GP.GPTD.LocalHrOfs";
BA_ "VssSig" SG_ 2566889768 LocalMinOfs "Mch.GP.GPTD.LocalMinOfs";
BA_ "VssSig" SG_ 2566889768 Year "Mch.GP.GPTD.Year";
BA_ "VssSig" SG_ 2566889768 Day "Mch.GP.GPTD.Day";
BA_ "VssSig" SG_ 2566889768 Mon "Mch.GP.GPTD.Mon";
BA_ "VssSig" SG_ 2566889768 Hrs "Mch.GP.GPTD.Hrs";
BA_ "VssSig" SG_ 2566889768 Mins "Mch.GP.GPTD.Mins";
BA_ "VssSig" SG_ 2566889768 Secs "Mch.GP.GPTD.Secs";
BA_ "VssSig" SG_ 2566890024 AvmSwVer "Mch.GP.SVGP.AvmSwVer";
BA_ "VssSig" SG_ 2566890024 AvmSwVerYear "Mch.GP.SVGP.AvmSwVerYear";
BA_ "VssSig" SG_ 2566890024 AvmSwVerDay "Mch.GP.SVGP.AvmSwVerDay";
BA_ "VssSig" SG_ 2566890024 AvmSwVerMon "Mch.GP.SVGP.AvmSwVerMon";
BA_ "VssSig" SG_ 2566890024 GpOsSwVer "Mch.GP.SVGP.GpOsSwVer";
BA_ "VssSig" SG_ 2566890024 GpOsSwVerYear "Mch.GP.SVGP.GpOsSwVerYear";
BA_ "VssSig" SG_ 2566890024 GpOsSwVerDay "Mch.GP.SVGP.GpOsSwVerDay";
BA_ "VssSig" SG_ 2566890024 GpOsSwVerMon "Mch.GP.SVGP.GpOsSwVerMon";
BA_ "VssSig" SG_ 2566890024 GpAppSwVer "Mch.GP.SVGP.GpAppSwVer";
BA_ "VssSig" SG_ 2566890024 GpAppSwVerYear "Mch.GP.SVGP.GpAppSwVerYear";
BA_ "VssSig" SG_ 2566890024 GpAppSwVerDay "Mch.GP.SVGP.GpAppSwVerDay";
BA_ "VssSig" SG_ 2566890024 GpAppSwVerMon "Mch.GP.SVGP.GpAppSwVerMon";
BA_ "VssSig" SG_ 2566890280 AttSetFlowVal "Mch.GP.ATTFC.AttSetFlowVal";
BA_ "VssSig" SG_ 2566890280 AttSetSaveFlag "Mch.GP.ATTFC.AttSetSaveFlag";
BA_ "VssSig" SG_ 2566890280 AttNo "Mch.GP.ATTFC.AttNo";
BA_ "VssSig" SG_ 2566890280 AttType "Mch.GP.ATTFC.AttType";
BA_ "VssSig" SG_ 2566890536 MgSoundGudStep "Mch.GP.MG2DBC.MgSoundGudStep";
BA_ "VssSig" SG_ 2566890536 AlmSt "Mch.GP.MG2DBC.AlmSt";
BA_ "VssSig" SG_ 2566890561 MgSoundGudStep "Mch.GW.MG2DBC.MgSoundGudStep";
BA_ "VssSig" SG_ 2566890561 AlmSt "Mch.GW.MG2DBC.AlmSt";
BA_ "VssSig" SG_ 2566890792 MsgChecksum "Mch.GP.GPCCS.MsgChecksum";
BA_ "VssSig" SG_ 2566890792 MsgCounter "Mch.GP.GPCCS.MsgCounter";
BA_ "VssSig" SG_ 2566890792 OptSetJoyPatternChange "Mch.GP.GPCCS.OptSetJoyPatternChange";
BA_ "VssSig" SG_ 2566892072 ReqCallIndex "Mch.GP.DCAP.ReqCallIndex";
BA_ "VssSig" SG_ 2566892072 PairingRequest "Mch.GP.DCAP.PairingRequest";
BA_ "VssSig" SG_ 2566892072 HangUpBtn "Mch.GP.DCAP.HangUpBtn";
BA_ "VssSig" SG_ 2566892072 DabSel "Mch.GP.DCAP.DabSel";
BA_ "VssSig" SG_ 2566892072 MdSel "Mch.GP.DCAP.MdSel";
BA_ "VssSig" SG_ 2566892072 AudioVolDownSel "Mch.GP.DCAP.AudioVolDownSel";
BA_ "VssSig" SG_ 2566892072 AudioVolUpSel "Mch.GP.DCAP.AudioVolUpSel";
BA_ "VssSig" SG_ 2566892072 BandSel "Mch.GP.DCAP.BandSel";
BA_ "VssSig" SG_ 2566892072 TalkBtn "Mch.GP.DCAP.TalkBtn";
BA_ "VssSig" SG_ 2566892072 AudioTuneDownSel "Mch.GP.DCAP.AudioTuneDownSel";
BA_ "VssSig" SG_ 2566892072 AudioCallListPopupSt "Mch.GP.DCAP.AudioCallListPopupSt";
BA_ "VssSig" SG_ 2566892072 AudioMenuSel "Mch.GP.DCAP.AudioMenuSel";
BA_ "VssSig" SG_ 2566892072 AudioPowerSel "Mch.GP.DCAP.AudioPowerSel";
BA_ "VssSig" SG_ 2566892072 AudioP5Sel "Mch.GP.DCAP.AudioP5Sel";
BA_ "VssSig" SG_ 2566892072 AudioP6Sel "Mch.GP.DCAP.AudioP6Sel";
BA_ "VssSig" SG_ 2566892072 AudioTuneSel "Mch.GP.DCAP.AudioTuneSel";
BA_ "VssSig" SG_ 2566892072 AudioTuneUpSel "Mch.GP.DCAP.AudioTuneUpSel";
BA_ "VssSig" SG_ 2566892072 AudioP1Sel "Mch.GP.DCAP.AudioP1Sel";
BA_ "VssSig" SG_ 2566892072 AudioP2Sel "Mch.GP.DCAP.AudioP2Sel";
BA_ "VssSig" SG_ 2566892072 AudioP3Sel "Mch.GP.DCAP.AudioP3Sel";
BA_ "VssSig" SG_ 2566892072 AudioP4Sel "Mch.GP.DCAP.AudioP4Sel";
BA_ "VssSig" SG_ 2566892072 AudioAmSel "Mch.GP.DCAP.AudioAmSel";
BA_ "VssSig" SG_ 2566892072 AudioFmSel "Mch.GP.DCAP.AudioFmSel";
BA_ "VssSig" SG_ 2566892072 AudioUsbSel "Mch.GP.DCAP.AudioUsbSel";
BA_ "VssSig" SG_ 2566892072 AudioAuxSel "Mch.GP.DCAP.AudioAuxSel";
VAL_ 2566867489 HpApMd 0 "Off" 1 "On" 2 "Error" 3 "N/A" ;
VAL_ 2566867489 GrLmt 0 "Off" 1 "On" 2 "Error" 3 "N/A" ;
VAL_ 2566867489 BodyAng 0 "Off" 1 "On" 2 "Error" 3 "N/A" ;
VAL_ 2566867489 WghSt 0 "Off" 1 "On" 2 "Error" 3 "N/A" ;
VAL_ 2566867489 PilotCutOffSt 0 "Unlock " 1 "Manual Lock " 2 "Auto Lock" 3 "Not Available" ;
VAL_ 2566867489 BodySt 0 "Off" 1 "Hold" 2 "Float" 3 "Not Defined" ;
VAL_ 2566867489 VhcStGndSaw 0 "Off" 1 "On" 2 "Error" 3 "N/A" ;
VAL_ 2566867489 VhcStIntAxleLck 0 "Off" 1 "On" 2 "Error" 3 "N/A" ;
VAL_ 2566867489 TrlHhFlowMd 0 "Off" 1 "On" 2 "Error" 3 "N/A" ;
VAL_ 2566867489 ExcAutoBrkAntiFire 0 "Off" 1 "On" 2 "Error" 3 "N/A" ;
VAL_ 2566867489 TrlIntLckOvrd 0 "Off" 1 "On" 2 "Error" 3 "N/A" ;
VAL_ 2566867489 TrlCtrlFlow 0 "Off" 1 "On" 2 "Error" 3 "N/A" ;
VAL_ 2566867489 TrlSelfLv 0 "Off" 1 "On" 2 "Error" 3 "N/A" ;
VAL_ 2566867489 TrlHhFlow 0 "Off" 1 "On" 2 "Error" 3 "N/A" ;
VAL_ 2566867745 EcoGgSt 0 "Green" 1 "Yellow" 2 "Red" 3 "White" ;
VAL_ 2566868257 AutoCalbMd 0 "Manual" 1 "Auto" 2 "Error" 3 "N/A" ;
VAL_ 2566868257 CalbReq 0 "False" 1 "True" 2 "Error" 3 "N/A" ;
VAL_ 2566868257 VhcStTpsCalb 0 "None" 1 "In Progress" 2 "Complete" 3 "N/A" ;
VAL_ 2566868257 VhcStEgCtrlDialMax 0 "Off" 1 "On" 2 "Error" 3 "N/A" ;
VAL_ 2566873377 LowOutReq8 0 "Off" 1 "On" 2 "Error Indicator" 3 "Not Available" ;
VAL_ 2566873377 LowOutReq7 0 "Off" 1 "On" 2 "Error Indicator" 3 "Not Available" ;
VAL_ 2566873377 LowOutReq6 0 "Off" 1 "On" 2 "Error Indicator" 3 "Not Available" ;
VAL_ 2566873377 LowOutReq5 0 "Off" 1 "On" 2 "Error Indicator" 3 "Not Available" ;
VAL_ 2566873377 LowOutReq4 0 "Off" 1 "On" 2 "Error Indicator" 3 "Not Available" ;
VAL_ 2566873377 LowOutReq3 0 "Off" 1 "On" 2 "Error Indicator" 3 "Not Available" ;
VAL_ 2566873377 LowOutReq2 0 "Off" 1 "On" 2 "Error Indicator" 3 "Not Available" ;
VAL_ 2566873377 LowOutReq1 0 "Off" 1 "On" 2 "Error Indicator" 3 "Not Available" ;
VAL_ 2566873377 OutReq15 0 "Off" 1 "On" 2 "Error Indicator" 3 "Not Available" ;
VAL_ 2566873377 OutReq14 0 "Off" 1 "On" 2 "Error Indicator" 3 "Not Available" ;
VAL_ 2566873377 OutReq13 0 "Off" 1 "On" 2 "Error Indicator" 3 "Not Available" ;
VAL_ 2566873377 OutReq12 0 "Off" 1 "On" 2 "Error Indicator" 3 "Not Available" ;
VAL_ 2566873377 OutReq11 0 "Off" 1 "On" 2 "Error Indicator" 3 "Not Available" ;
VAL_ 2566873377 OutReq10 0 "Off" 1 "On" 2 "Error Indicator" 3 "Not Available" ;
VAL_ 2566873377 OutReq9 0 "Off" 1 "On" 2 "Error Indicator" 3 "Not Available" ;
VAL_ 2566873377 OutReq8 0 "Off" 1 "On" 2 "Error Indicator" 3 "Not Available" ;
VAL_ 2566873377 OutReq7 0 "Off" 1 "On" 2 "Error Indicator" 3 "Not Available" ;
VAL_ 2566873377 OutReq6 0 "Off" 1 "On" 2 "Error Indicator" 3 "Not Available" ;
VAL_ 2566873377 OutReq5 0 "Off" 1 "On" 2 "Error Indicator" 3 "Not Available" ;
VAL_ 2566873377 OutReq4 0 "Off" 1 "On" 2 "Error Indicator" 3 "Not Available" ;
VAL_ 2566873377 OutReq3 0 "Off" 1 "On" 2 "Error Indicator" 3 "Not Available" ;
VAL_ 2566873377 OutReq2 0 "Off" 1 "On" 2 "Error Indicator" 3 "Not Available" ;
VAL_ 2566873377 OutReq1 0 "Off" 1 "On" 2 "Error Indicator" 3 "Not Available" ;
VAL_ 2566873886 ErrorFlag 0 "None" 1 "Error indicator" ;
VAL_ 2566873886 VltIn2 0 "Error indicator" 1 "Not Available" ;
VAL_ 2566873886 VltIn1 0 "Error indicator" 1 "Not Available" ;
VAL_ 2566873886 OutFdbkCur13 0 "Error indicator" 1 "Not Available" ;
VAL_ 2566873886 OutFdbkCur12 0 "Error indicator" 1 "Not Available" ;
VAL_ 2566873886 OutFdbkCur11 0 "Error indicator" 1 "Not Available" ;
VAL_ 2566873886 OutFdbkCur10 0 "Error indicator" 1 "Not Available" ;
VAL_ 2566873886 OutFdbkCur9 0 "Error indicator" 1 "Not Available" ;
VAL_ 2566874654 OutFdbkActvLowCur8 0 "Normal" 1 "Open" 2 "Short" ;
VAL_ 2566874654 OutFdbkActvLowCur7 0 "Normal" 1 "Open" 2 "Short" ;
VAL_ 2566874654 OutFdbkActvLowCur6 0 "Normal" 1 "Open" 2 "Short" ;
VAL_ 2566874654 OutFdbkActvLowCur5 0 "Normal" 1 "Open" 2 "Short" ;
VAL_ 2566874654 OutFdbkActvLowCur4 0 "Normal" 1 "Open" 2 "Short" ;
VAL_ 2566874654 OutFdbkActvLowCur3 0 "Normal" 1 "Open" 2 "Short" ;
VAL_ 2566874654 OutFdbkActvLowCur2 0 "Normal" 1 "Open" 2 "Short" ;
VAL_ 2566874654 OutFdbkActvLowCur1 0 "Normal" 1 "Open" 2 "Short" ;
VAL_ 2566874654 OutFdbkActvHighCur15 0 "Normal" 1 "Open" 2 "Short" ;
VAL_ 2566874654 OutFdbkActvHighCur14 0 "Normal" 1 "Open" 2 "Short" ;
VAL_ 2566874654 OutFdbkActvHighCur13 0 "Normal" 1 "Open" 2 "Short" ;
VAL_ 2566874654 OutFdbkActvHighCur12 0 "Normal" 1 "Open" 2 "Short" ;
VAL_ 2566874654 OutFdbkActvHighCur11 0 "Normal" 1 "Open" 2 "Short" ;
VAL_ 2566874654 OutFdbkActvHighCur10 0 "Normal" 1 "Open" 2 "Short" ;
VAL_ 2566874654 OutFdbkActvHighCur9 0 "Normal" 1 "Open" 2 "Short" ;
VAL_ 2566874654 OutFdbkActvHighCur8 0 "Normal" 1 "Open" 2 "Short" ;
VAL_ 2566874654 OutFdbkActvHighCur7 0 "Normal" 1 "Open" 2 "Short" ;
VAL_ 2566874654 OutFdbkActvHighCur6 0 "Normal" 1 "Open" 2 "Short" ;
VAL_ 2566874654 OutFdbkActvHighCur5 0 "Normal" 1 "Open" 2 "Short" ;
VAL_ 2566874654 OutFdbkActvHighCur4 0 "Normal" 1 "Open" 2 "Short" ;
VAL_ 2566874654 OutFdbkActvHighCur3 0 "Error indicator" 1 "Not Available" ;
VAL_ 2566874654 OutFdbkActvHighCur2 0 "Error indicator" 1 "Not Available" ;
VAL_ 2566874654 OutFdbkActvHighCur1 0 "Error indicator" 1 "Not Available" ;
VAL_ 2566874910 InVlt12 0 "Normal" 1 "Open" 2 "Short" ;
VAL_ 2566874910 InVlt11 0 "Normal" 1 "Open" 2 "Short" ;
VAL_ 2566874910 InVlt10 0 "Normal" 1 "Open" 2 "Short" ;
VAL_ 2566874910 InVlt9 0 "Normal" 1 "Open" 2 "Short" ;
VAL_ 2566874910 InVlt8 0 "Normal" 1 "Open" 2 "Short" ;
VAL_ 2566874910 InVlt7 0 "Normal" 1 "Open" 2 "Short" ;
VAL_ 2566874910 InVlt6 0 "Normal" 1 "Open" 2 "Short" ;
VAL_ 2566874910 InVlt5 0 "Normal" 1 "Open" 2 "Short" ;
VAL_ 2566874910 InVlt4 0 "Normal" 1 "Open" 2 "Short" ;
VAL_ 2566874910 InVlt3 0 "Error indicator" 1 "Not Available" ;
VAL_ 2566874910 InVlt2 0 "Error indicator" 1 "Not Available" ;
VAL_ 2566874910 InVlt1 0 "Error indicator" 1 "Not Available" ;
VAL_ 2566875422 OutFdbkCur12 0 "Error indicator" 1 "Not Available" ;
VAL_ 2566875422 OutFdbkCur11 0 "Error indicator" 1 "Not Available" ;
VAL_ 2566875422 OutFdbkCur10 0 "Error indicator" 1 "Not Available" ;
VAL_ 2566875422 OutFdbkCur9 0 "Error indicator" 1 "Not Available" ;
VAL_ 2566875559 OutFdbkCur12 0 "Error indicator" 1 "Not Available" ;
VAL_ 2566875559 OutFdbkCur11 0 "Error indicator" 1 "Not Available" ;
VAL_ 2566875559 OutFdbkCur10 0 "Error indicator" 1 "Not Available" ;
VAL_ 2566875559 OutFdbkCur9 0 "Error indicator" 1 "Not Available" ;
VAL_ 2566875678 MiniRly30AFuse2St 0 "False" 1 "True" 2 "Error" 3 "N/A" ;
VAL_ 2566875678 MiniRly30AFuse1St 0 "False" 1 "True" 2 "Error" 3 "N/A" ;
VAL_ 2566875678 MicroRly20AFuse5St 0 "False" 1 "True" 2 "Error" 3 "N/A" ;
VAL_ 2566875678 MicroRly20AFuse4St 0 "False" 1 "True" 2 "Error" 3 "N/A" ;
VAL_ 2566875678 MicroRly20AFuse3St 0 "False" 1 "True" 2 "Error" 3 "N/A" ;
VAL_ 2566875678 MicroRly20AFuse2St 0 "False" 1 "True" 2 "Error" 3 "N/A" ;
VAL_ 2566875678 MicroRly20AFuse1St 0 "False" 1 "True" 2 "Error" 3 "N/A" ;
VAL_ 2566875678 KeyOn30AFuse5St 0 "False" 1 "True" 2 "Error" 3 "N/A" ;
VAL_ 2566875678 KeyOn30AFuse4St 0 "False" 1 "True" 2 "Error" 3 "N/A" ;
VAL_ 2566875678 KeyOn30AFuse3St 0 "False" 1 "True" 2 "Error" 3 "N/A" ;
VAL_ 2566875678 KeyOn30AFuse2St 0 "False" 1 "True" 2 "Error" 3 "N/A" ;
VAL_ 2566875678 KeyOn30AFuse1St 0 "False" 1 "True" 2 "Error" 3 "N/A" ;
VAL_ 2566875678 KeyOn20AFuse10St 0 "False" 1 "True" 2 "Error" 3 "N/A" ;
VAL_ 2566875678 KeyOn20AFuse9St 0 "False" 1 "True" 2 "Error" 3 "N/A" ;
VAL_ 2566875678 KeyOn20AFuse8St 0 "False" 1 "True" 2 "Error" 3 "N/A" ;
VAL_ 2566875678 KeyOn20AFuse7St 0 "False" 1 "True" 2 "Error" 3 "N/A" ;
VAL_ 2566875678 KeyOn20AFuse6St 0 "False" 1 "True" 2 "Error" 3 "N/A" ;
VAL_ 2566875678 KeyOn20AFuse5St 0 "False" 1 "True" 2 "Error" 3 "N/A" ;
VAL_ 2566875678 KeyOn20AFuse4St 0 "False" 1 "True" 2 "Error" 3 "N/A" ;
VAL_ 2566875678 KeyOn20AFuse3St 0 "False" 1 "True" 2 "Error" 3 "N/A" ;
VAL_ 2566875678 KeyOn20AFuse2St 0 "False" 1 "True" 2 "Error" 3 "N/A" ;
VAL_ 2566875678 KeyOn20AFuse1St 0 "False" 1 "True" 2 "Error" 3 "N/A" ;
VAL_ 2566875678 KeyOn10AFuse5St 0 "False" 1 "True" 2 "Error" 3 "N/A" ;
VAL_ 2566875678 KeyOn10AFuse4St 0 "False" 1 "True" 2 "Error" 3 "N/A" ;
VAL_ 2566875678 KeyOn10AFuse3St 0 "False" 1 "True" 2 "Error" 3 "N/A" ;
VAL_ 2566875678 KeyOn10AFuse2St 0 "False" 1 "True" 2 "Error" 3 "N/A" ;
VAL_ 2566875678 KeyOn10AFuse1St 0 "False" 1 "True" 2 "Error" 3 "N/A" ;
VAL_ 2566875678 KeyOn5AFuse15St 0 "False" 1 "True" 2 "Error" 3 "N/A" ;
VAL_ 2566875678 KeyOn5AFuse14St 0 "False" 1 "True" 2 "Error" 3 "N/A" ;
VAL_ 2566875678 KeyOn5AFuse13St 0 "False" 1 "True" 2 "Error" 3 "N/A" ;
VAL_ 2566875678 KeyOn5AFuse12St 0 "False" 1 "True" 2 "Error" 3 "N/A" ;
VAL_ 2566875678 KeyOn5AFuse11St 0 "False" 1 "True" 2 "Error" 3 "N/A" ;
VAL_ 2566875678 KeyOn5AFuse10St 0 "False" 1 "True" 2 "Error" 3 "N/A" ;
VAL_ 2566875678 KeyOn5AFuse9St 0 "False" 1 "True" 2 "Error" 3 "N/A" ;
VAL_ 2566875678 KeyOn5AFuse8St 0 "False" 1 "True" 2 "Error" 3 "N/A" ;
VAL_ 2566875678 KeyOn5AFuse7St 0 "False" 1 "True" 2 "Error" 3 "N/A" ;
VAL_ 2566875678 KeyOn5AFuse6St 0 "False" 1 "True" 2 "Error" 3 "N/A" ;
VAL_ 2566875678 KeyOn5AFuse5St 0 "False" 1 "True" 2 "Error" 3 "N/A" ;
VAL_ 2566875678 KeyOn5AFuse4St 0 "False" 1 "True" 2 "Error" 3 "N/A" ;
VAL_ 2566875678 KeyOn5AFuse3St 0 "False" 1 "True" 2 "Error" 3 "N/A" ;
VAL_ 2566875678 KeyOn5AFuse2St 0 "False" 1 "True" 2 "Error" 3 "N/A" ;
VAL_ 2566875678 KeyOn5AFuse1St 0 "False" 1 "True" 2 "Error" 3 "N/A" ;
VAL_ 2566875678 BPlus30AFuse5St 0 "False" 1 "True" 2 "Error" 3 "N/A" ;
VAL_ 2566875678 BPlus30AFuse4St 0 "False" 1 "True" 2 "Error" 3 "N/A" ;
VAL_ 2566875678 BPlus30AFuse3St 0 "False" 1 "True" 2 "Error" 3 "N/A" ;
VAL_ 2566875678 BPlus30AFuse2St 0 "False" 1 "True" 2 "Error" 3 "N/A" ;
VAL_ 2566875678 BPlus30AFuse1St 0 "False" 1 "True" 2 "Error" 3 "N/A" ;
VAL_ 2566875678 BPlus20AFuse5St 0 "False" 1 "True" 2 "Error" 3 "N/A" ;
VAL_ 2566875678 BPlus20AFuse4St 0 "False" 1 "True" 2 "Error" 3 "N/A" ;
VAL_ 2566875678 BPlus20AFuse3St 0 "False" 1 "True" 2 "Error" 3 "N/A" ;
VAL_ 2566875678 BPlus20AFuse2St 0 "False" 1 "True" 2 "Error" 3 "N/A" ;
VAL_ 2566875678 BPlus20AFuse1St 0 "False" 1 "True" 2 "Error" 3 "N/A" ;
VAL_ 2566875678 BPlus5AFuse10St 0 "False" 1 "True" 2 "Error" 3 "N/A" ;
VAL_ 2566875678 BPlus5AFuse9St 0 "False" 1 "True" 2 "Error" 3 "N/A" ;
VAL_ 2566875678 BPlus5AFuse8St 0 "False" 1 "True" 2 "Error" 3 "N/A" ;
VAL_ 2566875678 BPlus5AFuse7St 0 "False" 1 "True" 2 "Error" 3 "N/A" ;
VAL_ 2566875678 BPlus5AFuse6St 0 "False" 1 "True" 2 "Error" 3 "N/A" ;
VAL_ 2566875678 BPlus5AFuse5St 0 "False" 1 "True" 2 "Error" 3 "N/A" ;
VAL_ 2566875678 BPlus5AFuse4St 0 "False" 1 "True" 2 "Error" 3 "N/A" ;
VAL_ 2566875678 BPlus5AFuse3St 0 "False" 1 "True" 2 "Error" 3 "N/A" ;
VAL_ 2566875678 BPlus5AFuse2St 0 "False" 1 "True" 2 "Error" 3 "N/A" ;
VAL_ 2566875678 BPlus5AFuse1St 0 "False" 1 "True" 2 "Error" 3 "N/A" ;
VAL_ 2566875815 MiniRly30AFuse2St 0 "False" 1 "True" 2 "Error" 3 "N/A" ;
VAL_ 2566875815 MiniRly30AFuse1St 0 "False" 1 "True" 2 "Error" 3 "N/A" ;
VAL_ 2566875815 MicroRly20AFuse5St 0 "False" 1 "True" 2 "Error" 3 "N/A" ;
VAL_ 2566875815 MicroRly20AFuse4St 0 "False" 1 "True" 2 "Error" 3 "N/A" ;
VAL_ 2566875815 MicroRly20AFuse3St 0 "False" 1 "True" 2 "Error" 3 "N/A" ;
VAL_ 2566875815 MicroRly20AFuse2St 0 "False" 1 "True" 2 "Error" 3 "N/A" ;
VAL_ 2566875815 MicroRly20AFuse1St 0 "False" 1 "True" 2 "Error" 3 "N/A" ;
VAL_ 2566875815 KeyOn30AFuse5St 0 "False" 1 "True" 2 "Error" 3 "N/A" ;
VAL_ 2566875815 KeyOn30AFuse4St 0 "False" 1 "True" 2 "Error" 3 "N/A" ;
VAL_ 2566875815 KeyOn30AFuse3St 0 "False" 1 "True" 2 "Error" 3 "N/A" ;
VAL_ 2566875815 KeyOn30AFuse2St 0 "False" 1 "True" 2 "Error" 3 "N/A" ;
VAL_ 2566875815 KeyOn30AFuse1St 0 "False" 1 "True" 2 "Error" 3 "N/A" ;
VAL_ 2566875815 KeyOn20AFuse10St 0 "False" 1 "True" 2 "Error" 3 "N/A" ;
VAL_ 2566875815 KeyOn20AFuse9St 0 "False" 1 "True" 2 "Error" 3 "N/A" ;
VAL_ 2566875815 KeyOn20AFuse8St 0 "False" 1 "True" 2 "Error" 3 "N/A" ;
VAL_ 2566875815 KeyOn20AFuse7St 0 "False" 1 "True" 2 "Error" 3 "N/A" ;
VAL_ 2566875815 KeyOn20AFuse6St 0 "False" 1 "True" 2 "Error" 3 "N/A" ;
VAL_ 2566875815 KeyOn20AFuse5St 0 "False" 1 "True" 2 "Error" 3 "N/A" ;
VAL_ 2566875815 KeyOn20AFuse4St 0 "False" 1 "True" 2 "Error" 3 "N/A" ;
VAL_ 2566875815 KeyOn20AFuse3St 0 "False" 1 "True" 2 "Error" 3 "N/A" ;
VAL_ 2566875815 KeyOn20AFuse2St 0 "False" 1 "True" 2 "Error" 3 "N/A" ;
VAL_ 2566875815 KeyOn20AFuse1St 0 "False" 1 "True" 2 "Error" 3 "N/A" ;
VAL_ 2566875815 KeyOn10AFuse5St 0 "False" 1 "True" 2 "Error" 3 "N/A" ;
VAL_ 2566875815 KeyOn10AFuse4St 0 "False" 1 "True" 2 "Error" 3 "N/A" ;
VAL_ 2566875815 KeyOn10AFuse3St 0 "False" 1 "True" 2 "Error" 3 "N/A" ;
VAL_ 2566875815 KeyOn10AFuse2St 0 "False" 1 "True" 2 "Error" 3 "N/A" ;
VAL_ 2566875815 KeyOn10AFuse1St 0 "False" 1 "True" 2 "Error" 3 "N/A" ;
VAL_ 2566875815 KeyOn5AFuse15St 0 "False" 1 "True" 2 "Error" 3 "N/A" ;
VAL_ 2566875815 KeyOn5AFuse14St 0 "False" 1 "True" 2 "Error" 3 "N/A" ;
VAL_ 2566875815 KeyOn5AFuse13St 0 "False" 1 "True" 2 "Error" 3 "N/A" ;
VAL_ 2566875815 KeyOn5AFuse12St 0 "False" 1 "True" 2 "Error" 3 "N/A" ;
VAL_ 2566875815 KeyOn5AFuse11St 0 "False" 1 "True" 2 "Error" 3 "N/A" ;
VAL_ 2566875815 KeyOn5AFuse10St 0 "False" 1 "True" 2 "Error" 3 "N/A" ;
VAL_ 2566875815 KeyOn5AFuse9St 0 "False" 1 "True" 2 "Error" 3 "N/A" ;
VAL_ 2566875815 KeyOn5AFuse8St 0 "False" 1 "True" 2 "Error" 3 "N/A" ;
VAL_ 2566875815 KeyOn5AFuse7St 0 "False" 1 "True" 2 "Error" 3 "N/A" ;
VAL_ 2566875815 KeyOn5AFuse6St 0 "False" 1 "True" 2 "Error" 3 "N/A" ;
VAL_ 2566875815 KeyOn5AFuse5St 0 "False" 1 "True" 2 "Error" 3 "N/A" ;
VAL_ 2566875815 KeyOn5AFuse4St 0 "False" 1 "True" 2 "Error" 3 "N/A" ;
VAL_ 2566875815 KeyOn5AFuse3St 0 "False" 1 "True" 2 "Error" 3 "N/A" ;
VAL_ 2566875815 KeyOn5AFuse2St 0 "False" 1 "True" 2 "Error" 3 "N/A" ;
VAL_ 2566875815 KeyOn5AFuse1St 0 "False" 1 "True" 2 "Error" 3 "N/A" ;
VAL_ 2566875815 BPlus30AFuse5St 0 "False" 1 "True" 2 "Error" 3 "N/A" ;
VAL_ 2566875815 BPlus30AFuse4St 0 "False" 1 "True" 2 "Error" 3 "N/A" ;
VAL_ 2566875815 BPlus30AFuse3St 0 "False" 1 "True" 2 "Error" 3 "N/A" ;
VAL_ 2566875815 BPlus30AFuse2St 0 "False" 1 "True" 2 "Error" 3 "N/A" ;
VAL_ 2566875815 BPlus30AFuse1St 0 "False" 1 "True" 2 "Error" 3 "N/A" ;
VAL_ 2566875815 BPlus20AFuse5St 0 "False" 1 "True" 2 "Error" 3 "N/A" ;
VAL_ 2566875815 BPlus20AFuse4St 0 "False" 1 "True" 2 "Error" 3 "N/A" ;
VAL_ 2566875815 BPlus20AFuse3St 0 "False" 1 "True" 2 "Error" 3 "N/A" ;
VAL_ 2566875815 BPlus20AFuse2St 0 "False" 1 "True" 2 "Error" 3 "N/A" ;
VAL_ 2566875815 BPlus20AFuse1St 0 "False" 1 "True" 2 "Error" 3 "N/A" ;
VAL_ 2566875815 BPlus5AFuse10St 0 "False" 1 "True" 2 "Error" 3 "N/A" ;
VAL_ 2566875815 BPlus5AFuse9St 0 "False" 1 "True" 2 "Error" 3 "N/A" ;
VAL_ 2566875815 BPlus5AFuse8St 0 "False" 1 "True" 2 "Error" 3 "N/A" ;
VAL_ 2566875815 BPlus5AFuse7St 0 "False" 1 "True" 2 "Error" 3 "N/A" ;
VAL_ 2566875815 BPlus5AFuse6St 0 "False" 1 "True" 2 "Error" 3 "N/A" ;
VAL_ 2566875815 BPlus5AFuse5St 0 "False" 1 "True" 2 "Error" 3 "N/A" ;
VAL_ 2566875815 BPlus5AFuse4St 0 "False" 1 "True" 2 "Error" 3 "N/A" ;
VAL_ 2566875815 BPlus5AFuse3St 0 "False" 1 "True" 2 "Error" 3 "N/A" ;
VAL_ 2566875815 BPlus5AFuse2St 0 "False" 1 "True" 2 "Error" 3 "N/A" ;
VAL_ 2566875815 BPlus5AFuse1St 0 "False" 1 "True" 2 "Error" 3 "N/A" ;
VAL_ 2566875929 VhcStSybACOffInd 0 "Off" 1 "On(No Blinking)" 2 "Blink (Normal Blink)" 3 "Blink (Slow Blink)" ;
VAL_ 2566875929 CpsSt 0 "Off" 1 "On" 2 "Error" 3 "N/A" ;
VAL_ 2566875929 TmpSetValBelowSt 0 "Disable" 1 "Enable" ;
VAL_ 2566875929 TmpSetValOverSt 0 "Disable" 1 "Enable" ;
VAL_ 2566875929 HvacPwrSt 0 "Off" 1 "On" 2 "Error" 3 "N/A" ;
VAL_ 2566875929 WindDirDefIndSt 0 "Disable" 1 "Enable" ;
VAL_ 2566875929 WindDirFloorIndSt 0 "Disable" 1 "Enable" ;
VAL_ 2566875929 WindDirRrIndSt 0 "Disable" 1 "Enable" ;
VAL_ 2566875929 WindDirFrIndSt 0 "Disable" 1 "Enable" ;
VAL_ 2566875929 DefMdSt 0 "Disable" 1 "Not Available" 2 "Enable" 3 "Reserved" ;
VAL_ 2566875929 OutInMdSel 0 "Outtake mode" 1 "Not Available" 2 "Intake mode" 3 "Reserved" ;
VAL_ 2566875929 AcMdSt 0 "Disable" 1 "Not Available" 2 "Enable" 3 "Reserved" ;
VAL_ 2566875929 MnAutoMdSt 0 "Manual" 1 "Not Available" 2 "Auto" 3 "Reserved" ;
VAL_ 2566876961 LowOutReq8 0 "Off" 1 "On" 2 "Error Indicator" 3 "Not Available" ;
VAL_ 2566876961 LowOutReq7 0 "Off" 1 "On" 2 "Error Indicator" 3 "Not Available" ;
VAL_ 2566876961 LowOutReq6 0 "Off" 1 "On" 2 "Error Indicator" 3 "Not Available" ;
VAL_ 2566876961 LowOutReq5 0 "Off" 1 "On" 2 "Error Indicator" 3 "Not Available" ;
VAL_ 2566876961 LowOutReq4 0 "Off" 1 "On" 2 "Error Indicator" 3 "Not Available" ;
VAL_ 2566876961 LowOutReq3 0 "Off" 1 "On" 2 "Error Indicator" 3 "Not Available" ;
VAL_ 2566876961 LowOutReq2 0 "Off" 1 "On" 2 "Error Indicator" 3 "Not Available" ;
VAL_ 2566876961 LowOutReq1 0 "Off" 1 "On" 2 "Error Indicator" 3 "Not Available" ;
VAL_ 2566876961 OutReq15 0 "Off" 1 "On" 2 "Error Indicator" 3 "Not Available" ;
VAL_ 2566876961 OutReq14 0 "Off" 1 "On" 2 "Error Indicator" 3 "Not Available" ;
VAL_ 2566876961 OutReq13 0 "Off" 1 "On" 2 "Error Indicator" 3 "Not Available" ;
VAL_ 2566876961 OutReq12 0 "Off" 1 "On" 2 "Error Indicator" 3 "Not Available" ;
VAL_ 2566876961 OutReq11 0 "Off" 1 "On" 2 "Error Indicator" 3 "Not Available" ;
VAL_ 2566876961 OutReq10 0 "Off" 1 "On" 2 "Error Indicator" 3 "Not Available" ;
VAL_ 2566876961 OutReq9 0 "Off" 1 "On" 2 "Error Indicator" 3 "Not Available" ;
VAL_ 2566876961 OutReq8 0 "Off" 1 "On" 2 "Error Indicator" 3 "Not Available" ;
VAL_ 2566876961 OutReq7 0 "Off" 1 "On" 2 "Error Indicator" 3 "Not Available" ;
VAL_ 2566876961 OutReq6 0 "Off" 1 "On" 2 "Error Indicator" 3 "Not Available" ;
VAL_ 2566876961 OutReq5 0 "Off" 1 "On" 2 "Error Indicator" 3 "Not Available" ;
VAL_ 2566876961 OutReq4 0 "Off" 1 "On" 2 "Error Indicator" 3 "Not Available" ;
VAL_ 2566876961 OutReq3 0 "Off" 1 "On" 2 "Error Indicator" 3 "Not Available" ;
VAL_ 2566876961 OutReq2 0 "Off" 1 "On" 2 "Error Indicator" 3 "Not Available" ;
VAL_ 2566876961 OutReq1 0 "Off" 1 "On" 2 "Error Indicator" 3 "Not Available" ;
VAL_ 2566877770 St 0 "Unknown" 1 "No Fix" 2 "2D" 3 "3D" ;
VAL_ 2566878794 GpsAntSt 0 "Normal" 1 "Removed" 2 "Shorten" 3 "N/A" ;
VAL_ 2566878794 ScrtyCmd 0 "Normal" 1 "RPM Limit" 2 "Engine Lock" 3 "Not Available" ;
VAL_ 2566879818 KeyType 0 "None" 1 "Fob" 2 "Digital Key" 3 "Keyless" 4 "Remote" ;
VAL_ 2566879818 LogIn 0 "False" 1 "True" 2 "Error" 3 "N/A" ;
VAL_ 2566880330 SelType 0 "None" 1 "Fob" 2 "Digital Key" 3 "Keyless" 4 "Remote" ;
VAL_ 2566881064 TmsStInfo2 0 "Unlock " 1 "Lock" ;
VAL_ 2566881064 TmsStInfo1 0 "Unlock " 1 "Lock" ;
VAL_ 2566881098 TmsStInfo2 0 "Unlock " 1 "Lock" ;
VAL_ 2566881098 TmsStInfo1 0 "Unlock " 1 "Lock" ;
VAL_ 2566883328 UreaLvBzSt 0 "Off" 1 "On" 2 "Error" 3 "N/A" ;
VAL_ 2566884385 StartCrkSw 0 "Off" 1 "On" 2 "Error" 3 "N/A" ;
VAL_ 2566884385 GrSelSw 0 "Off" 1 "On" 2 "Error" 3 "N/A" ;
VAL_ 2566884385 GrSelNtrlSw 0 "Off" 1 "On" 2 "Error" 3 "N/A" ;
VAL_ 2566884385 PrkSw 0 "Off" 1 "On" 2 "Error" 3 "N/A" ;
VAL_ 2566884385 GrSelRvsSw 0 "Off" 1 "On" 2 "Error" 3 "N/A" ;
VAL_ 2566884385 GrSelShftDnSw 0 "Off" 1 "On" 2 "Error" 3 "N/A" ;
VAL_ 2566884385 GrSelShftUpSw 0 "Off" 1 "On" 2 "Error" 3 "N/A" ;
VAL_ 2566884385 GrSelFwdSw 0 "Off" 1 "On" 2 "Error" 3 "N/A" ;
VAL_ 2566884385 DustIndSw 0 "Off" 1 "On" 2 "Error" 3 "N/A" ;
VAL_ 2566884385 StartAccSw 0 "Off" 1 "On" 2 "Error" 3 "N/A" ;
VAL_ 2566884385 AtsForceRgnSw 0 "Off" 1 "On" 2 "Error" 3 "N/A" ;
VAL_ 2566884385 AtsRgnIhbsw 0 "Off" 1 "On" 2 "Error" 3 "N/A" ;
VAL_ 2566884385 eFan3ErrSt 0 "Off" 1 "On" 2 "Error" 3 "N/A" ;
VAL_ 2566884385 KeyBrSw 0 "Off" 1 "On" 2 "Error" 3 "N/A" ;
VAL_ 2566884385 TipJoySw 0 "Off" 1 "On" 2 "Error" 3 "N/A" ;
VAL_ 2566884385 AgsSw 0 "Off" 1 "On" 2 "Error" 3 "N/A" ;
VAL_ 2566884385 eFan2ErrSt 0 "Off" 1 "On" 2 "Error" 3 "N/A" ;
VAL_ 2566884385 eFan1ErrSt 0 "Off" 1 "On" 2 "Error" 3 "N/A" ;
VAL_ 2566884385 SeatBeltSt 0 "Off" 1 "On" 2 "Error" 3 "N/A" ;
VAL_ 2566884385 FrWiperStpSw 0 "Off" 1 "On" 2 "Error" 3 "N/A" ;
VAL_ 2566884641 SusRhDn 0 "Off" 1 "On" 2 "Error" 3 "N/A" ;
VAL_ 2566884641 TocRvs 0 "Off" 1 "On" 2 "Error" 3 "N/A" ;
VAL_ 2566884641 TurnSigRhRly 0 "Off" 1 "On" 2 "Error" 3 "N/A" ;
VAL_ 2566884641 TurnSigLhRly 0 "Off" 1 "On" 2 "Error" 3 "N/A" ;
VAL_ 2566884641 SusRhUp 0 "Off" 1 "On" 2 "Error" 3 "N/A" ;
VAL_ 2566884641 EgRunOutSig 0 "Off" 1 "On" 2 "Error" 3 "N/A" ;
VAL_ 2566884641 SusLhDn 0 "Off" 1 "On" 2 "Error" 3 "N/A" ;
VAL_ 2566884641 UreaSuperChgWrnSig 0 "Off" 1 "On" 2 "Error" 3 "N/A" ;
VAL_ 2566884641 FanStpSv 0 "Off" 1 "On" 2 "Error" 3 "N/A" ;
VAL_ 2566884641 Dhl3Sig 0 "Off" 1 "On" 2 "Error" 3 "N/A" ;
VAL_ 2566884641 Dhl2Sig 0 "Off" 1 "On" 2 "Error" 3 "N/A" ;
VAL_ 2566884641 SusLhUp 0 "Off" 1 "On" 2 "Error" 3 "N/A" ;
VAL_ 2566884641 PrkBrkRlsSv 0 "Off" 1 "On" 2 "Error" 3 "N/A" ;
VAL_ 2566884641 AxleOilCoolSv 0 "Off" 1 "On" 2 "Error" 3 "N/A" ;
VAL_ 2566884641 TocUnloading 0 "Off" 1 "On" 2 "Error" 3 "N/A" ;
VAL_ 2566884641 AccRly 0 "Off" 1 "On" 2 "Error" 3 "N/A" ;
VAL_ 2566884641 RrWinHtRly 0 "Off" 1 "On" 2 "Error" 3 "N/A" ;
VAL_ 2566884641 LiftArmFlt 0 "Off" 1 "On" 2 "Error" 3 "N/A" ;
VAL_ 2566884641 AutoShutOffRly 0 "Off" 1 "On" 2 "Error" 3 "N/A" ;
VAL_ 2566884641 BrkChgSv 0 "Off" 1 "On" 2 "Error" 3 "N/A" ;
VAL_ 2566884641 Dhl1Sig 0 "Off" 1 "On" 2 "Error" 3 "N/A" ;
VAL_ 2566886952 RrVwPriMd 0 "Normal Mode" 1 "Priority Mode" ;
VAL_ 2566886952 VwMd 0 "Top" 1 "Rear" 2 "Right" 3 "Top+Rear" 4 "3D" 5 "Boom" 15 "Not Available" ;
VAL_ 2566887223 RrVwPriMd 0 "Normal Mode" 1 "Priority Mode" ;
VAL_ 2566887223 AvmWrnGud 0 "Not Used" 1 "AVM Warning Guide Line Off" 2 "AVM Warning Guide Line On" 6 "Error" 7 "Invalid" ;
VAL_ 2566887223 AvmSt 0 "Not Used" 1 "AVM Not Ready (IGN Off)" 2 "AVM Normal (IGN On)" 3 "AVM Fail" 30 "Error" 31 "Invalid" ;
VAL_ 2566887223 AvmUltraBz 0 "Ultrasonic All Off" 1 "Left Activation" 2 "Righr Activation" 3 "Rear Activation" 4 "Left / Rear Activation" 5 "Left / Right Activation" 6 "Right / Rear Activation" 7 "Left / Right / Rear Activation" 14 "Error" 15 "Invalid" ;
VAL_ 2566887223 AvmTonSize 0 "Not Used" 1 "5T Crawler" 2 "5T Wheel" 3 "14T Wheel" 4 "21T Wheel" 5 "30T Crawler" 14 "Error" 15 "Invalid" ;
VAL_ 2566887223 AvmDisplayMsg 0 "Not Used" 1 "No Message" 2 "InCameraCalibarionMode" 62 "Warning_Check_Front&Right&Left" 63 "Warning_Check_Back&Right&Left" 254 "Error" 255 "Invalid" ;
VAL_ 2566887223 AvmOutType 0 "Not Used" 1 "AVM Output Type NTSC" 2 "AVM Output Type LVDS" 6 "Error" 7 "Invalid" ;
VAL_ 2566887223 AvmVw 0 "Topview" 1 "Rear Wide" 2 "Top + Right" 3 "Rear + Corner" 4 "3D" 5 "Boom (Option)" ;
VAL_ 2566887223 AvmLanguagePack 0 "NotUsed" 1 "Korean (Default)" 2 "English" 3 "Chinese (PRC)" 4 "French(France)" 5 "German(Germany)" 6 "Dutch(Netherlands)" 7 "Italian(Italy)" 8 "Portuguese(Portugal)" 9 "Spanish(International)" 10 "Finnish" 11 "Swedish" 12 "Norwegian(Bokmal)" 13 "Danish" 14 "Japanese" 15 "Turkish" 16 " Indonesian" 17 "Polish" 18 "Russian" 19 "Arabic(Saudi Arabia)" 20 "Farsi(Persian)" 21 " Hindi" 22 "Thai" 23 "Greek" 24 "Vietnamese" ;
VAL_ 2566887479 UltsSigL6 0 "Off" 1 "Level 1" 2 "Level 2" 3 "Level 3" 4 "Fault" 5 "Noise Error" 14 "Error" 15 "Invalid" ;
VAL_ 2566887479 UltsSigR6 0 "Off" 1 "Level 1" 2 "Level 2" 3 "Level 3" 4 "Fault" 5 "Noise Error" 14 "Error" 15 "Invalid" ;
VAL_ 2566887479 UltsSigL5 0 "Off" 1 "Level 1" 2 "Level 2" 3 "Level 3" 4 "Fault" 5 "Noise Error" 14 "Error" 15 "Invalid" ;
VAL_ 2566887479 UltsSigR5 0 "Off" 1 "Level 1" 2 "Level 2" 3 "Level 3" 4 "Fault" 5 "Noise Error" 14 "Error" 15 "Invalid" ;
VAL_ 2566887479 UltsSigL4 0 "Off" 1 "Level 1" 2 "Level 2" 3 "Level 3" 4 "Fault" 5 "Noise Error" 14 "Error" 15 "Invalid" ;
VAL_ 2566887479 UltsSigR4 0 "Off" 1 "Level 1" 2 "Level 2" 3 "Level 3" 4 "Fault" 5 "Noise Error" 14 "Error" 15 "Invalid" ;
VAL_ 2566887479 UltsSigL3 0 "Off" 1 "Level 1" 2 "Level 2" 3 "Level 3" 4 "Fault" 5 "Noise Error" 14 "Error" 15 "Invalid" ;
VAL_ 2566887479 UltsSigR3 0 "Off" 1 "Level 1" 2 "Level 2" 3 "Level 3" 4 "Fault" 5 "Noise Error" 14 "Error" 15 "Invalid" ;
VAL_ 2566887479 UltsSigL2 0 "Off" 1 "Level 1" 2 "Level 2" 3 "Level 3" 4 "Fault" 5 "Noise Error" 14 "Error" 15 "Invalid" ;
VAL_ 2566887479 UltsSigR2 0 "Off" 1 "Level 1" 2 "Level 2" 3 "Level 3" 4 "Fault" 5 "Noise Error" 14 "Error" 15 "Invalid" ;
VAL_ 2566887479 UltsSigL1 0 "Off" 1 "Level 1" 2 "Level 2" 3 "Level 3" 4 "Fault" 5 "Noise Error" 14 "Error" 15 "Invalid" ;
VAL_ 2566887479 UltsSigR1 0 "Off" 1 "Level 1" 2 "Level 2" 3 "Level 3" 4 "Fault" 5 "Noise Error" 14 "Error" 15 "Invalid" ;
VAL_ 2566887720 CamPrmtCorCompleteSt 0 "???" ;
VAL_ 2566887720 ToleranceCorMenuentryCmd 0 "?? ?? ?? ??" 1 "?? ?? ?? ??" ;
VAL_ 2566887720 WrnGudSetCmd 0 "Off" 1 "On" 2 "Error" 3 "N/A" ;
VAL_ 2566887720 UltsSs08Cmd 0 "Off" 1 "On" 2 "Error" 3 "N/A" ;
VAL_ 2566887720 UltsSs07Cmd 0 "Off" 1 "On" 2 "Error" 3 "N/A" ;
VAL_ 2566887720 UltsSs06Cmd 0 "Off" 1 "On" 2 "Error" 3 "N/A" ;
VAL_ 2566887720 UltsSs05Cmd 0 "Off" 1 "On" 2 "Error" 3 "N/A" ;
VAL_ 2566887720 UltsSs04Cmd 0 "Off" 1 "On" 2 "Error" 3 "N/A" ;
VAL_ 2566887720 UltsSs03Cmd 0 "Off" 1 "On" 2 "Error" 3 "N/A" ;
VAL_ 2566887720 UltsSs02Cmd 0 "Off" 1 "On" 2 "Error" 3 "N/A" ;
VAL_ 2566887720 UltsSs01Cmd 0 "Off" 1 "On" 2 "Error" 3 "N/A" ;
VAL_ 2566887720 UltsSs12Cmd 0 "Off" 1 "On" 2 "Error" 3 "N/A" ;
VAL_ 2566887720 UltsSs11Cmd 0 "Off" 1 "On" 2 "Error" 3 "N/A" ;
VAL_ 2566887720 UltsSs10Cmd 0 "Off" 1 "On" 2 "Error" 3 "N/A" ;
VAL_ 2566887720 UltsSs09Cmd 0 "Off" 1 "On" 2 "Error" 3 "N/A" ;
VAL_ 2566887720 SetApplicationCmd 0 "Disable" 1 "Enable" ;
VAL_ 2566887720 ToleranceCorCmd 0 "?? ?? ?" 1 "?? ?? ?" 2 "?? ?? ??" 3 "?? ?? ??" ;
VAL_ 2566887720 FactoryReCmd 0 "Disable" 1 "Enable" ;
VAL_ 2566887720 UltsSsOpt 0 "?? ??" 1 "?? ??" ;
VAL_ 2566887720 UltsBuzzerStopSig 0 "On" 1 "Off" ;
VAL_ 2566887720 BoomCamOpt 0 "Boom Camera ???" 1 "Boom Camera ??" ;
VAL_ 2566887720 UltsBzOffSig 0 "On" 1 "Off" ;
VAL_ 2566887720 UltsRecognitionDistanceSet 0 "??" 1 "???" ;
VAL_ 2566887720 VhcType2 0 "LC(??)" 1 "LCR(???)" 2 "LL" 3 "Not Defined" ;
VAL_ 2566887720 VhcType1 0 "Wheel" 1 "Crawler" ;
VAL_ 2566887720 FactoryType 0 "?? 1" 1 "?? 2" 2 "?? 3" 3 "?? 4" ;
VAL_ 2566887720 VwMd 0 "Top" 1 "Rear" 2 "Right" 3 "Top+Rear" 4 "3D" 5 "Boom" 15 "Not Available" ;
VAL_ 2566887991 CamPrmtCorCompleteSt 0 "???" ;
VAL_ 2566887991 ToleranceCorMenuentryCmd 0 "?? ?? ?? ??" 1 "?? ?? ?? ??" ;
VAL_ 2566887991 WrnGudSetCmd 0 "Off" 1 "On" 2 "Error" 3 "N/A" ;
VAL_ 2566887991 UltsSs08Cmd 0 "Off" 1 "On" 2 "Error" 3 "N/A" ;
VAL_ 2566887991 UltsSs07Cmd 0 "Off" 1 "On" 2 "Error" 3 "N/A" ;
VAL_ 2566887991 UltsSs06Cmd 0 "Off" 1 "On" 2 "Error" 3 "N/A" ;
VAL_ 2566887991 UltsSs05Cmd 0 "Off" 1 "On" 2 "Error" 3 "N/A" ;
VAL_ 2566887991 UltsSs04Cmd 0 "Off" 1 "On" 2 "Error" 3 "N/A" ;
VAL_ 2566887991 UltsSs03Cmd 0 "Off" 1 "On" 2 "Error" 3 "N/A" ;
VAL_ 2566887991 UltsSs02Cmd 0 "Off" 1 "On" 2 "Error" 3 "N/A" ;
VAL_ 2566887991 UltsSs01Cmd 0 "Off" 1 "On" 2 "Error" 3 "N/A" ;
VAL_ 2566887991 UltsSs12Cmd 0 "Off" 1 "On" 2 "Error" 3 "N/A" ;
VAL_ 2566887991 UltsSs11Cmd 0 "Off" 1 "On" 2 "Error" 3 "N/A" ;
VAL_ 2566887991 UltsSs10Cmd 0 "Off" 1 "On" 2 "Error" 3 "N/A" ;
VAL_ 2566887991 UltsSs09Cmd 0 "Off" 1 "On" 2 "Error" 3 "N/A" ;
VAL_ 2566887991 SetAppCmd 0 "Disable" 1 "Enable" ;
VAL_ 2566887991 ToleranceCorCmd 0 "?? ?? ?" 1 "?? ?? ?" 2 "?? ?? ??" 3 "?? ?? ??" ;
VAL_ 2566887991 FactoryResetCmd 0 "Disable" 1 "Enable" ;
VAL_ 2566887991 UltsSsOpt 0 "?? ??" 1 "?? ??" ;
VAL_ 2566887991 UltsBzStopSig 0 "On" 1 "Off" ;
VAL_ 2566887991 BoomCamOpt 0 "Boom Camera ???" 1 "Boom Camera ??" ;
VAL_ 2566887991 UltsBzOffSig 0 "On" 1 "Off" ;
VAL_ 2566887991 UltsRecognitionDistanceSet 0 "??" 1 "???" ;
VAL_ 2566887991 VhcType2 0 "LC(??)" 1 "LCR(???)" 2 "LL" 3 "Not Defined" ;
VAL_ 2566887991 VhcType1 0 "Wheel" 1 "Crawler" ;
VAL_ 2566887991 FactoryType 0 "?? 1" 1 "?? 2" 2 "?? 3" 3 "?? 4" ;
VAL_ 2566887991 VwMd 0 "Top" 1 "Rear" 2 "Right" 3 "Top+Rear" 4 "3D" 5 "Boom" 15 "Not Available" ;
VAL_ 2566889512 EvMdCmd 0 "Normal Mode" 1 "EV Mode" 2 "N/A" 3 "N/A" ;
VAL_ 2566889512 ObjectSsChmsl 0 "Off" 1 "On" 2 "Error" 3 "N/A" ;
VAL_ 2566889512 KeylessCrankEnbSt 0 "Off" 1 "On" 2 "Error" 3 "N/A" ;
VAL_ 2566889512 DaacmdSt 0 "Off" 1 "On" 2 "Error" 3 "N/A" ;
VAL_ 2566889512 QuickCoolMdSt 0 "Off" 1 "On" 2 "Error" 3 "N/A" ;
VAL_ 2566889512 DzAstMdSt 0 "Off" 1 "On" 2 "Error" 3 "N/A" ;
VAL_ 2566889512 KeyPadPri 0 "KeyPad" 1 "Virtual KePad" ;
VAL_ 2566889512 TractionMdSt 0 "Max" 1 "A(3)" 2 "B(2)" 3 "C(1)" 4 "Auto" ;
VAL_ 2566889512 EgLckSt 0 "Unlock " 1 "Lock" ;
VAL_ 2566889512 JduseStforRpm 0 "Off" 1 "On" 2 "Error" 3 "N/A" ;
VAL_ 2566889512 AutoIdleMdSt 0 "Off" 1 "On" 2 "Error" 3 "N/A" ;
VAL_ 2566889512 WrkMdSt 0 "Dig" 1 "Lift" 2 "Breaker" 3 "Two Way" ;
VAL_ 2566889512 PwrMdSt 0 "Standard Mode" 1 "Economy Mode" 2 "Power + Mode" 3 "Power Mode" ;
VAL_ 2566890280 AttSetSaveFlag 0 "Disable" 1 "Enable" ;
VAL_ 2566890280 AttType 0 "Breaker" 1 "Two Way" ;
VAL_ 2566890536 MgSoundGudStep 0 "Alarm Off" 1 "Alarm #1" 2 "Alarm #2" 3 "Alarm #3" 4 "Alarm #4" 5 "Alarm #5" 6 "Alarm #6" 7 "Alarm #7" 8 "Alarm #8" 9 "Alarm #9" ;
VAL_ 2566890536 AlmSt 0 "Alarm Off" 1 "Alarm #1" 2 "Alarm #2" 3 "Alarm #3" 4 "Alarm #4" 5 "Alarm #5" ;
VAL_ 2566890561 MgSoundGudStep 0 "Alarm Off" 1 "Alarm #1" 2 "Alarm #2" 3 "Alarm #3" 4 "Alarm #4" 5 "Alarm #5" 6 "Alarm #6" 7 "Alarm #7" 8 "Alarm #8" 9 "Alarm #9" ;
VAL_ 2566890561 AlmSt 0 "Alarm Off" 1 "Alarm #1" 2 "Alarm #2" 3 "Alarm #3" 4 "Alarm #4" 5 "Alarm #5" ;
VAL_ 2566890792 OptSetJoyPatternChange 0 "ISO (for CTL EXC)" 1 "BHL (for CTL Backhoe)" 2 "MHI" 3 "KOBE" 4 "SCM" 5 "CTL ISO" 6 "CTL H" ;
VAL_ 2566892072 ReqCallIndex 0 "None" 1 "1st Index" 2 "2nd Index" 3 "3rd Index" 4 "4th Index" 5 "5th Index" 6 "6th Index" 7 "7th Index" 8 "8th Index" 9 "9th Index" 10 "10th Index" ;
VAL_ 2566892072 PairingRequest 0 "Off" 1 "On" 2 "Error Indicator" 3 "N/A" ;
VAL_ 2566892072 HangUpBtn 0 "Off" 1 "On" 2 "Error Indicator" 3 "N/A" ;
VAL_ 2566892072 DabSel 0 "Off" 1 "On" 2 "Error Indicator" 3 "N/A" ;
VAL_ 2566892072 MdSel 0 "Off" 1 "On" 2 "Error Indicator" 3 "N/A" ;
VAL_ 2566892072 AudioVolDownSel 0 "Off" 1 "On" 2 "Error Indicator" 3 "N/A" ;
VAL_ 2566892072 AudioVolUpSel 0 "Off" 1 "On" 2 "Error Indicator" 3 "N/A" ;
VAL_ 2566892072 BandSel 0 "Off" 1 "On" 2 "Error Indicator" 3 "N/A" ;
VAL_ 2566892072 TalkBtn 0 "Off" 1 "On" 2 "Error Indicator" 3 "N/A" ;
VAL_ 2566892072 AudioTuneDownSel 0 "Off" 1 "On" 2 "Error Indicator" 3 "N/A" ;
VAL_ 2566892072 AudioCallListPopupSt 0 "Off" 1 "On" 2 "Error Indicator" 3 "N/A" ;
VAL_ 2566892072 AudioMenuSel 0 "Off" 1 "On" 2 "Error Indicator" 3 "N/A" ;
VAL_ 2566892072 AudioPowerSel 0 "Off" 1 "On" 2 "Error Indicator" 3 "N/A" ;
VAL_ 2566892072 AudioP5Sel 0 "Off" 1 "On" 2 "Error Indicator" 3 "N/A" ;
VAL_ 2566892072 AudioP6Sel 0 "Off" 1 "On" 2 "Error Indicator" 3 "N/A" ;
VAL_ 2566892072 AudioTuneSel 0 "Off" 1 "On" 2 "Error Indicator" 3 "N/A" ;
VAL_ 2566892072 AudioTuneUpSel 0 "Off" 1 "On" 2 "Error Indicator" 3 "N/A" ;
VAL_ 2566892072 AudioP1Sel 0 "Off" 1 "On" 2 "Error Indicator" 3 "N/A" ;
VAL_ 2566892072 AudioP2Sel 0 "Off" 1 "On" 2 "Error Indicator" 3 "N/A" ;
VAL_ 2566892072 AudioP3Sel 0 "Off" 1 "On" 2 "Error Indicator" 3 "N/A" ;
VAL_ 2566892072 AudioP4Sel 0 "Off" 1 "On" 2 "Error Indicator" 3 "N/A" ;
VAL_ 2566892072 AudioFmSel 0 "Off" 1 "On" 2 "Error Indicator" 3 "N/A" ;
VAL_ 2566892072 AudioUsbSel 0 "Off" 1 "On" 2 "Error Indicator" 3 "N/A" ;
VAL_ 2566892072 AudioAuxSel 0 "Off" 1 "On" 2 "Error Indicator" 3 "N/A" ;
